VERSION ""

NS_ :

BS_:

BU_:

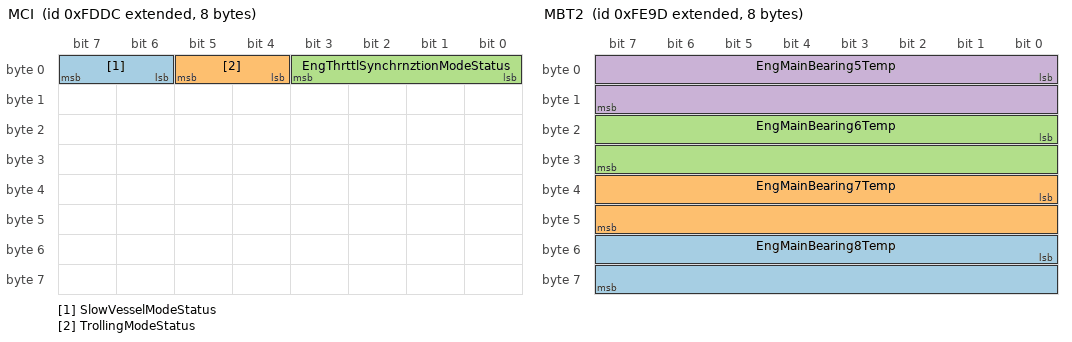
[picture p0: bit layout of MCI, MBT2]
BO_ 2147548636 MCI: 8 Vector__XXX
 SG_ SlowVesselModeStatus : 6|2@1+ (1,0) [0|3] "" Vector__XXX
 SG_ TrollingModeStatus : 4|2@1+ (1,0) [0|3] "" Vector__XXX
 SG_ EngThrttlSynchrnztionModeStatus : 0|4@1+ (1,0) [0|15] "" Vector__XXX

BO_ 2147548828 MBT3: 8 Vector__XXX
 SG_ EngMainBearing11Temp : 32|16@1+ (0.03125,-273) [-273|1735] "deg" Vector__XXX
 SG_ EngMainBearing10Temp : 16|16@1+ (0.03125,-273) [-273|1735] "deg" Vector__XXX
 SG_ EngMainBearing9Temp : 0|16@1+ (0.03125,-273) [-273|1735] "deg" Vector__XXX

BO_ 2147548829 MBT2: 8 Vector__XXX
 SG_ EngMainBearing8Temp : 48|16@1+ (0.03125,-273) [-273|1735] "deg" Vector__XXX
 SG_ EngMainBearing7Temp : 32|16@1+ (0.03125,-273) [-273|1735] "deg" Vector__XXX
 SG_ EngMainBearing6Temp : 16|16@1+ (0.03125,-273) [-273|1735] "deg" Vector__XXX
 SG_ EngMainBearing5Temp : 0|16@1+ (0.03125,-273) [-273|1735] "deg" Vector__XXX

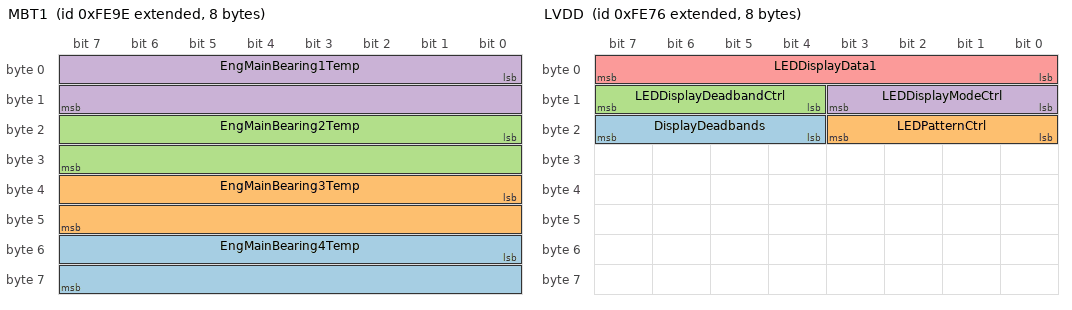
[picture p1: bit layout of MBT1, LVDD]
BO_ 2147548830 MBT1: 8 Vector__XXX
 SG_ EngMainBearing4Temp : 48|16@1+ (0.03125,-273) [-273|1735] "deg" Vector__XXX
 SG_ EngMainBearing3Temp : 32|16@1+ (0.03125,-273) [-273|1735] "deg" Vector__XXX
 SG_ EngMainBearing2Temp : 16|16@1+ (0.03125,-273) [-273|1735] "deg" Vector__XXX
 SG_ EngMainBearing1Temp : 0|16@1+ (0.03125,-273) [-273|1735] "deg" Vector__XXX

BO_ 2147548790 LVDD: 8 Vector__XXX
 SG_ DisplayDeadbands : 20|4@1+ (1,0) [0|15] "" Vector__XXX
 SG_ LEDPatternCtrl : 16|4@1+ (1,0) [0|15] "" Vector__XXX
 SG_ LEDDisplayDeadbandCtrl : 12|4@1+ (1,0) [0|15] "" Vector__XXX
 SG_ LEDDisplayModeCtrl : 8|4@1+ (1,0) [0|15] "" Vector__XXX
 SG_ LEDDisplayData1 : 0|8@1+ (1,0) [0|255] "" Vector__XXX

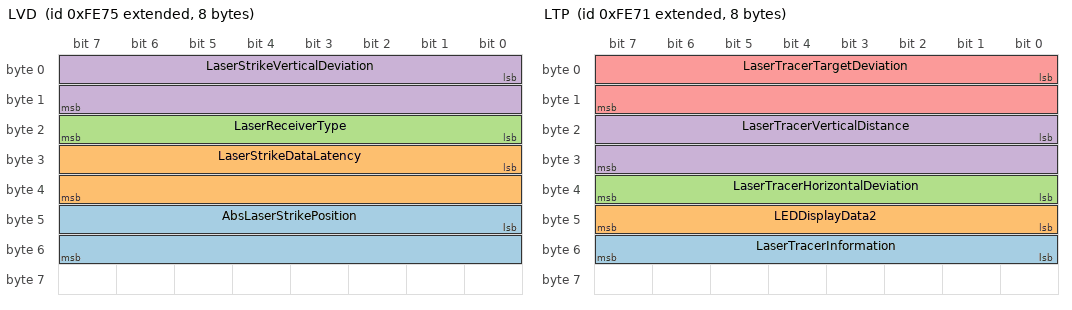
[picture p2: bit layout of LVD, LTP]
BO_ 2147548789 LVD: 8 Vector__XXX
 SG_ AbsLaserStrikePosition : 40|16@1+ (0.1,0) [0|6425.5] "mm" Vector__XXX
 SG_ LaserStrikeDataLatency : 24|16@1+ (51.2,0) [0|3.289856] "s" Vector__XXX
 SG_ LaserReceiverType : 16|8@1+ (1,0) [0|250] "" Vector__XXX
 SG_ LaserStrikeVerticalDeviation : 0|16@1+ (0.1,-2800) [-2800|3225.5] "mm" Vector__XXX

BO_ 2147548785 LTP: 8 Vector__XXX
 SG_ LaserTracerInformation : 48|8@1+ (1,0) [0|255] "" Vector__XXX
 SG_ LEDDisplayData2 : 40|8@1+ (1,0) [0|255] "" Vector__XXX
 SG_ LaserTracerHorizontalDeviation : 32|8@1+ (1,0) [0|250] "%" Vector__XXX
 SG_ LaserTracerVerticalDistance : 16|16@1+ (0.1,0) [0|6425.5] "mm" Vector__XXX
 SG_ LaserTracerTargetDeviation : 0|16@1+ (0.1,-2800) [-2800|3225.5] "mm" Vector__XXX

BO_ 2147548857 LTFI: 22 Vector__XXX
 SG_ TripDriveFuelEconomy : 160|16@1+ (1,0) [0|125.5] "km/kg" Vector__XXX
 SG_ TripCruiseFuelUsed : 128|32@1+ (0.5,0) [0|2105540607.5] "kg" Vector__XXX
 SG_ TripVehicleIdleFuelUsed : 96|32@1+ (0.5,0) [0|2105540607.5] "kg" Vector__XXX
 SG_ TripPTONonmovingFuelUsed : 64|32@1+ (0.5,0) [0|2105540607.5] "kg" Vector__XXX
 SG_ TripPTOMovingFuelUsed : 32|32@1+ (0.5,0) [0|2105540607.5] "kg" Vector__XXX
 SG_ TripDriveFuelUsed : 0|32@1+ (0.5,0) [0|2105540607.5] "kg" Vector__XXX

BO_ 2147548788 LSP: 8 Vector__XXX
 SG_ BldHeightSetPointHighResolution : 16|32@1+ (100,-208.2848) [-208.2848|0] "" Vector__XXX
 SG_ ModifySetPoint : 0|16@1+ (0.1,-2800) [-2800|3225.5] "mm" Vector__XXX

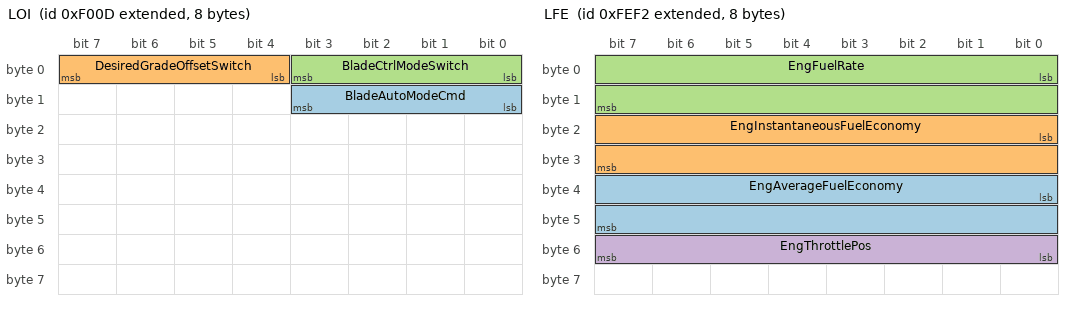
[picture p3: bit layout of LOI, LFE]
BO_ 2147545101 LOI: 8 Vector__XXX
 SG_ BladeAutoModeCmd : 8|4@1+ (1,0) [0|15] "" Vector__XXX
 SG_ DesiredGradeOffsetSwitch : 4|4@1+ (1,0) [0|15] "" Vector__XXX
 SG_ BladeCtrlModeSwitch : 0|4@1+ (1,0) [0|15] "" Vector__XXX

BO_ 2147548787 LMP: 8 Vector__XXX
 SG_ MastPos : 0|16@1+ (0.1,-2800) [-2800|3225.5] "mm" Vector__XXX

BO_ 2147548851 LFI: 8 Vector__XXX
 SG_ TripAverageFuelRate : 32|16@1+ (0.05,0) [0|3212.75] "kg/h" Vector__XXX
 SG_ TotalEngPTOFuelUsed : 0|32@1+ (0.5,0) [0|2105540607.5] "kg" Vector__XXX

BO_ 2147548914 LFE: 8 Vector__XXX
 SG_ EngAverageFuelEconomy : 32|16@1+ (1,0) [0|125.5] "km/kg" Vector__XXX
 SG_ EngInstantaneousFuelEconomy : 16|16@1+ (1,0) [0|125.5] "km/kg" Vector__XXX
 SG_ EngFuelRate : 0|16@1+ (0.05,0) [0|3212.75] "L/h" Vector__XXX
 SG_ EngThrottlePos : 48|8@1+ (0.4,0) [0|100] "%" Vector__XXX

BO_ 2147548905 LFC: 8 Vector__XXX
 SG_ EngTotalFuelUsed : 32|32@1+ (0.5,0) [0|2105540607.5] "L" Vector__XXX
 SG_ EngTripFuel : 0|32@1+ (0.5,0) [0|2105540607.5] "L" Vector__XXX

BO_ 2147548639 FWD: 8 Vector__XXX
 SG_ FrontWheelDriveActuatorStatus : 0|2@1+ (1,0) [0|3] "" Vector__XXX

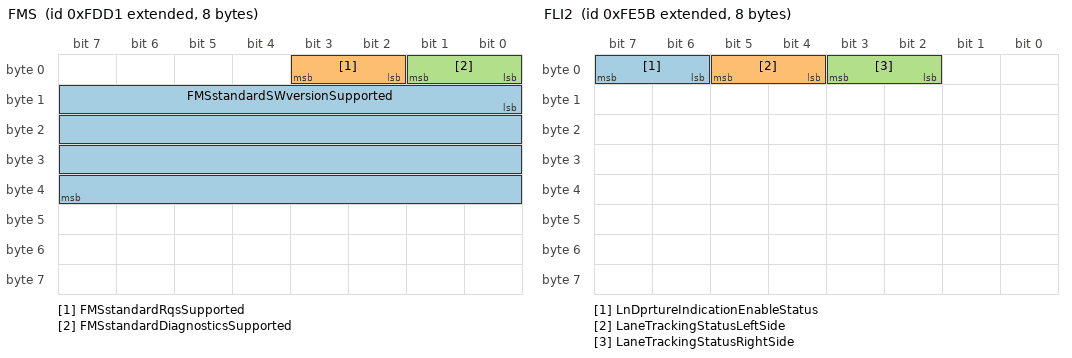
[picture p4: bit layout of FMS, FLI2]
BO_ 2147548625 FMS: 8 Vector__XXX
 SG_ FMSstandardSWversionSupported : 8|32@1+ (1,0) [0|255] "per" Vector__XXX
 SG_ FMSstandardRqsSupported : 2|2@1+ (1,0) [0|3] "" Vector__XXX
 SG_ FMSstandardDiagnosticsSupported : 0|2@1+ (1,0) [0|3] "" Vector__XXX

BO_ 2147548763 FLI2: 8 Vector__XXX
 SG_ LnDprtureIndicationEnableStatus : 6|2@1+ (1,0) [0|3] "" Vector__XXX
 SG_ LaneTrackingStatusLeftSide : 4|2@1+ (1,0) [0|3] "" Vector__XXX
 SG_ LaneTrackingStatusRightSide : 2|2@1+ (1,0) [0|3] "" Vector__XXX

BO_ 2147545095 FLI1: 8 Vector__XXX
 SG_ LaneDepartureImminentLeftSide : 6|2@1+ (1,0) [0|3] "" Vector__XXX
 SG_ LaneDepartureImminentRightSide : 4|2@1+ (1,0) [0|3] "" Vector__XXX

BO_ 2147548817 FL: 8 Vector__XXX
 SG_ EngFuelLeakage2 : 2|2@1+ (1,0) [0|3] "" Vector__XXX
 SG_ EngFuelLeakage1 : 0|2@1+ (1,0) [0|3] "" Vector__XXX

BO_ 2147548861 FD: 8 Vector__XXX
 SG_ FanSpeed : 16|16@1+ (0.125,0) [0|8031.875] "rpm" Vector__XXX
 SG_ FanDriveState : 8|4@1+ (1,0) [0|15] "" Vector__XXX
 SG_ EstPercentFanSpeed : 0|8@1+ (0.4,0) [0|100] "%" Vector__XXX

BO_ 2147548816 ETH: 33 Vector__XXX
 SG_ EngTorqueLimit6AxleInput : 248|16@1+ (2,0) [0|128510] "Nm" Vector__XXX
 SG_ EngTorqueLimit5Switch : 232|16@1+ (1,0) [0|64255] "Nm" Vector__XXX
 SG_ EngTorqueLimit4Trans : 216|16@1+ (1,0) [0|64255] "Nm" Vector__XXX
 SG_ EngTorqueLimit3Trans : 200|16@1+ (1,0) [0|64255] "Nm" Vector__XXX
 SG_ TransGearRatio3 : 184|16@1+ (0.01,0) [0|642.55] "" Vector__XXX
 SG_ EngTorqueLimit2Trans : 168|16@1+ (1,0) [0|64255] "Nm" Vector__XXX
 SG_ TransGearRatio2 : 152|16@1+ (0.01,0) [0|642.55] "" Vector__XXX
 SG_ EngTorqueLimit1Trans : 136|16@1+ (1,0) [0|64255] "Nm" Vector__XXX
 SG_ TransGearRatio1 : 120|16@1+ (0.01,0) [0|642.55] "" Vector__XXX
 SG_ EngTorqueLimitFeature : 114|3@1+ (1,0) [0|7] "" Vector__XXX
 SG_ TorqueLimitingFeatureStatus : 112|2@1+ (1,0) [0|3] "" Vector__XXX
 SG_ CalibRecordDurationTime : 80|32@1+ (0.05,0) [0|210554060.75] "hr" Vector__XXX
 SG_ CalibRecordStartYear : 72|8@1+ (1,1985) [1985|2235] "years" Vector__XXX
 SG_ CalibRecordStartDay : 64|8@1+ (0.25,0) [0|62.5] "days" Vector__XXX
 SG_ CalibRecordStartMonth : 56|8@1+ (1,0) [0|250] "months" Vector__XXX
 SG_ EngPeakTorque2 : 40|16@1+ (1,0) [0|64255] "Nm" Vector__XXX
 SG_ EngPeakTorque1 : 24|16@1+ (1,0) [0|64255] "Nm" Vector__XXX
 SG_ EngPower : 8|16@1+ (0.5,0) [0|32127.5] "kW" Vector__XXX
 SG_ NumberOfEngTorqueHistoryRecords : 0|8@1+ (1,0) [0|250] "records" Vector__XXX

BO_ 2147545100 ETC8: 8 Vector__XXX
 SG_ TransTorqueConverterRatio : 0|16@1+ (0.001,0) [0|64.255] "" Vector__XXX

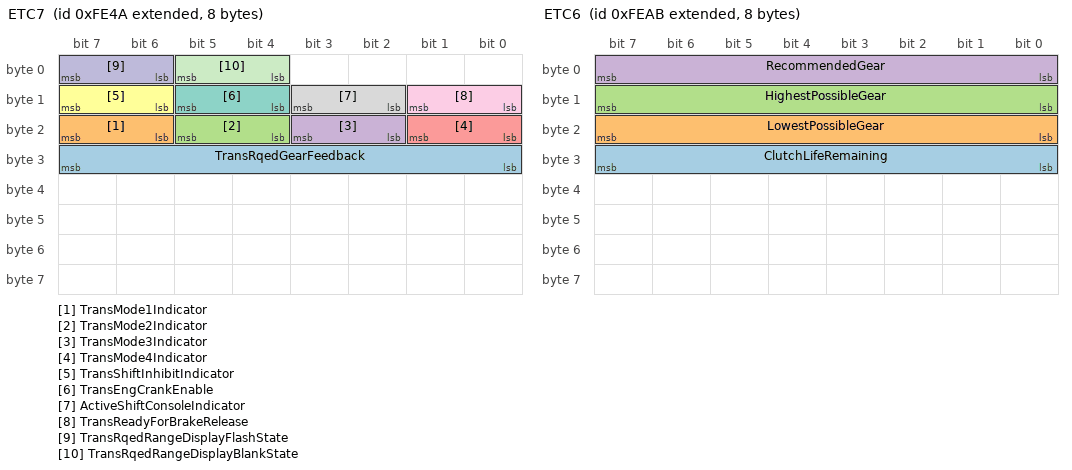
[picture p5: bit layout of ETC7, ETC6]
BO_ 2147548746 ETC7: 8 Vector__XXX
 SG_ TransRqedGearFeedback : 24|8@1+ (1,-125) [-125|125] "" Vector__XXX
 SG_ TransMode1Indicator : 22|2@1+ (1,0) [0|3] "" Vector__XXX
 SG_ TransMode2Indicator : 20|2@1+ (1,0) [0|3] "" Vector__XXX
 SG_ TransMode3Indicator : 18|2@1+ (1,0) [0|3] "" Vector__XXX
 SG_ TransMode4Indicator : 16|2@1+ (1,0) [0|3] "" Vector__XXX
 SG_ TransShiftInhibitIndicator : 14|2@1+ (1,0) [0|3] "" Vector__XXX
 SG_ TransEngCrankEnable : 12|2@1+ (1,0) [0|3] "" Vector__XXX
 SG_ ActiveShiftConsoleIndicator : 10|2@1+ (1,0) [0|3] "" Vector__XXX
 SG_ TransReadyForBrakeRelease : 8|2@1+ (1,0) [0|3] "" Vector__XXX
 SG_ TransRqedRangeDisplayFlashState : 6|2@1+ (1,0) [0|3] "" Vector__XXX
 SG_ TransRqedRangeDisplayBlankState : 4|2@1+ (1,0) [0|3] "" Vector__XXX

BO_ 2147548843 ETC6: 8 Vector__XXX
 SG_ ClutchLifeRemaining : 24|8@1+ (0.4,0) [0|100] "%" Vector__XXX
 SG_ LowestPossibleGear : 16|8@1+ (1,-125) [-125|125] "" Vector__XXX
 SG_ HighestPossibleGear : 8|8@1+ (1,-125) [-125|125] "" Vector__XXX
 SG_ RecommendedGear : 0|8@1+ (1,-125) [-125|125] "" Vector__XXX

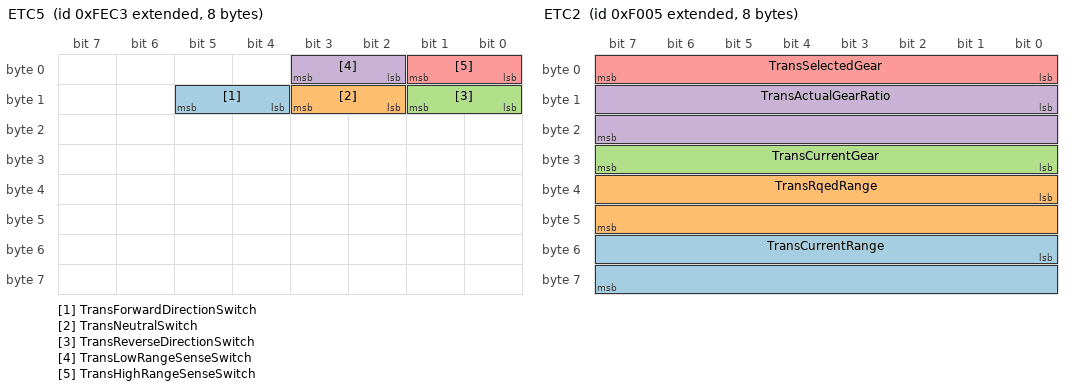
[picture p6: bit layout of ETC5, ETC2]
BO_ 2147548867 ETC5: 8 Vector__XXX
 SG_ TransForwardDirectionSwitch : 12|2@1+ (1,0) [0|3] "" Vector__XXX
 SG_ TransNeutralSwitch : 10|2@1+ (1,0) [0|3] "" Vector__XXX
 SG_ TransReverseDirectionSwitch : 8|2@1+ (1,0) [0|3] "" Vector__XXX
 SG_ TransLowRangeSenseSwitch : 2|2@1+ (1,0) [0|3] "" Vector__XXX
 SG_ TransHighRangeSenseSwitch : 0|2@1+ (1,0) [0|3] "" Vector__XXX

BO_ 2147548869 ETC4: 8 Vector__XXX
 SG_ TransSynchronizerBrakeValue : 8|8@1+ (0.4,0) [0|100] "%" Vector__XXX
 SG_ TransSynchronizerClutchValue : 0|8@1+ (0.4,0) [0|100] "%" Vector__XXX

BO_ 2147548871 ETC3: 8 Vector__XXX
 SG_ TransInertiaBrakeActuator : 46|2@1+ (1,0) [0|3] "" Vector__XXX
 SG_ TransDefuelActuator : 44|2@1+ (1,0) [0|3] "" Vector__XXX
 SG_ TransLockupClutchActuator : 42|2@1+ (1,0) [0|3] "" Vector__XXX
 SG_ TransClutchActuator : 40|2@1+ (1,0) [0|3] "" Vector__XXX
 SG_ TransSplitterIndirectActuator : 38|2@1+ (1,0) [0|3] "" Vector__XXX
 SG_ TransSplitterDirectActuator : 36|2@1+ (1,0) [0|3] "" Vector__XXX
 SG_ TransRangeLowActuator : 34|2@1+ (1,0) [0|3] "" Vector__XXX
 SG_ TransRangeHighActuator : 32|2@1+ (1,0) [0|3] "" Vector__XXX
 SG_ TransShiftFingerGearActuator2 : 30|2@1+ (1,0) [0|3] "" Vector__XXX
 SG_ TransShiftFingerRailActuator2 : 28|2@1+ (1,0) [0|3] "" Vector__XXX
 SG_ TransShiftFingerGearActuator1 : 26|2@1+ (1,0) [0|3] "" Vector__XXX
 SG_ TransShiftFingerRailActuator1 : 24|2@1+ (1,0) [0|3] "" Vector__XXX
 SG_ TrnsShftFngrCenterRailIndicator : 20|2@1+ (1,0) [0|3] "" Vector__XXX
 SG_ TrnsShftFngrEngagementIndicator : 18|2@1+ (1,0) [0|3] "" Vector__XXX
 SG_ TrnsShiftFingerNeutralIndicator : 16|2@1+ (1,0) [0|3] "" Vector__XXX
 SG_ TransShiftFingerRailPos : 8|8@1+ (0.4,0) [0|100] "%" Vector__XXX
 SG_ TransShiftFingerGearPos : 0|8@1+ (0.4,0) [0|100] "%" Vector__XXX

BO_ 2147545093 ETC2: 8 Vector__XXX
 SG_ TransCurrentRange : 48|16@1+ (1,0) [0|255] "per" Vector__XXX
 SG_ TransRqedRange : 32|16@1+ (1,0) [0|255] "per" Vector__XXX
 SG_ TransCurrentGear : 24|8@1+ (1,-125) [-125|125] "" Vector__XXX
 SG_ TransActualGearRatio : 8|16@1+ (0.001,0) [0|64.255] "" Vector__XXX
 SG_ TransSelectedGear : 0|8@1+ (1,-125) [-125|125] "" Vector__XXX

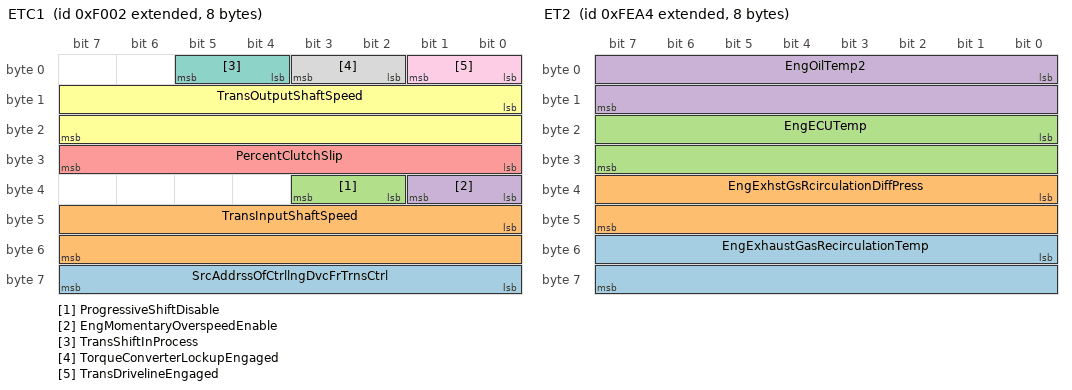
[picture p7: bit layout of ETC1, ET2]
BO_ 2147545090 ETC1: 8 Vector__XXX
 SG_ SrcAddrssOfCtrllngDvcFrTrnsCtrl : 56|8@1+ (1,0) [0|255] "" Vector__XXX
 SG_ TransInputShaftSpeed : 40|16@1+ (0.125,0) [0|8031.875] "rpm" Vector__XXX
 SG_ ProgressiveShiftDisable : 34|2@1+ (1,0) [0|3] "" Vector__XXX
 SG_ EngMomentaryOverspeedEnable : 32|2@1+ (1,0) [0|3] "" Vector__XXX
 SG_ PercentClutchSlip : 24|8@1+ (0.4,0) [0|100] "%" Vector__XXX
 SG_ TransOutputShaftSpeed : 8|16@1+ (0.125,0) [0|8031.875] "rpm" Vector__XXX
 SG_ TransShiftInProcess : 4|2@1+ (1,0) [0|3] "" Vector__XXX
 SG_ TorqueConverterLockupEngaged : 2|2@1+ (1,0) [0|3] "" Vector__XXX
 SG_ TransDrivelineEngaged : 0|2@1+ (1,0) [0|3] "" Vector__XXX

BO_ 2147548777 ET3: 8 Vector__XXX
 SG_ EngCoolantTempHiRes : 16|16@1+ (0.03125,-273) [-273|1735] "deg" Vector__XXX
 SG_ EngIntkVlvActationSystemOilTemp : 32|16@1+ (0.03125,-273) [-273|1735] "deg" Vector__XXX
 SG_ EngIntakeManifold1AirTemp : 0|16@1+ (0.03125,-273) [-273|1735] "deg" Vector__XXX

BO_ 2147548836 ET2: 8 Vector__XXX
 SG_ EngExhaustGasRecirculationTemp : 48|16@1+ (0.03125,-273) [-273|1735] "deg" Vector__XXX
 SG_ EngExhstGsRcirculationDiffPress : 32|16@1+ (1,-250) [-250|0] "a" Vector__XXX
 SG_ EngECUTemp : 16|16@1+ (0.03125,-273) [-273|1735] "deg" Vector__XXX
 SG_ EngOilTemp2 : 0|16@1+ (0.03125,-273) [-273|1735] "deg" Vector__XXX

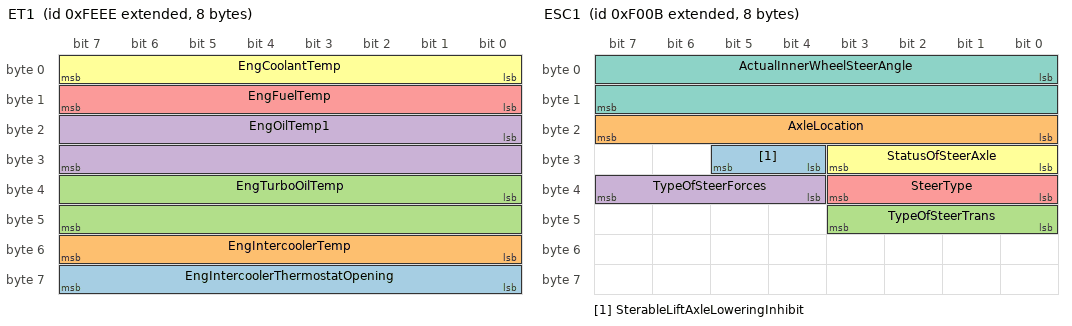
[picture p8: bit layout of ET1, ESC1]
BO_ 2147548910 ET1: 8 Vector__XXX
 SG_ EngIntercoolerThermostatOpening : 56|8@1+ (0.4,0) [0|100] "%" Vector__XXX
 SG_ EngIntercoolerTemp : 48|8@1+ (1,-40) [-40|210] "deg" Vector__XXX
 SG_ EngTurboOilTemp : 32|16@1+ (0.03125,-273) [-273|1735] "deg" Vector__XXX
 SG_ EngOilTemp1 : 16|16@1+ (0.03125,-273) [-273|1735] "deg" Vector__XXX
 SG_ EngFuelTemp : 8|8@1+ (1,-40) [-40|210] "deg" Vector__XXX
 SG_ EngCoolantTemp : 0|8@1+ (1,-40) [-40|210] "deg" Vector__XXX

BO_ 2147548679 ET: 8 Vector__XXX
 SG_ EngExhstExhstGsTempLeftManifold : 16|16@1+ (0.03125,-273) [-273|1735] "deg" Vector__XXX
 SG_ EngExhstExhstGsTmpRightManifold : 0|16@1+ (0.03125,-273) [-273|1735] "deg" Vector__XXX

BO_ 2147545099 ESC1: 8 Vector__XXX
 SG_ SterableLiftAxleLoweringInhibit : 28|2@1+ (1,0) [0|3] "" Vector__XXX
 SG_ AxleLocation : 16|8@1+ (1,0) [0|255] "" Vector__XXX
 SG_ TypeOfSteerTrans : 40|4@1+ (1,0) [0|15] "" Vector__XXX
 SG_ TypeOfSteerForces : 36|4@1+ (1,0) [0|15] "" Vector__XXX
 SG_ SteerType : 32|4@1+ (1,0) [0|15] "" Vector__XXX
 SG_ StatusOfSteerAxle : 24|4@1+ (1,0) [0|15] "" Vector__XXX
 SG_ ActualInnerWheelSteerAngle : 0|16@1+ (1,-125) [-125|125] "deg" Vector__XXX

BO_ 2147548866 ERC2: 8 Vector__XXX
 SG_ TransOutputRetarder : 0|2@1+ (1,0) [0|3] "" Vector__XXX

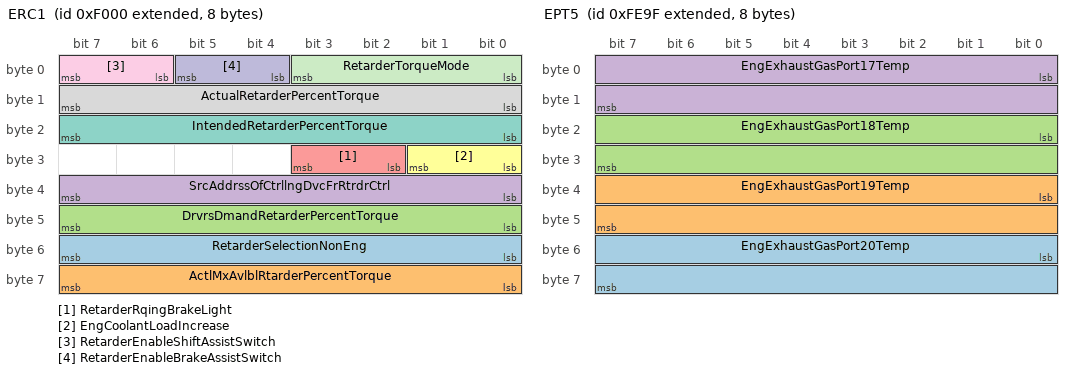
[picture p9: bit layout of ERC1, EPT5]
BO_ 2147545088 ERC1: 8 Vector__XXX
 SG_ RetarderSelectionNonEng : 48|8@1+ (0.4,0) [0|100] "%" Vector__XXX
 SG_ ActlMxAvlblRtarderPercentTorque : 56|8@1+ (1,-125) [-125|125] "%" Vector__XXX
 SG_ DrvrsDmandRetarderPercentTorque : 40|8@1+ (1,-125) [-125|125] "%" Vector__XXX
 SG_ SrcAddrssOfCtrllngDvcFrRtrdrCtrl : 32|8@1+ (1,0) [0|255] "" Vector__XXX
 SG_ RetarderRqingBrakeLight : 26|2@1+ (1,0) [0|3] "" Vector__XXX
 SG_ EngCoolantLoadIncrease : 24|2@1+ (1,0) [0|3] "" Vector__XXX
 SG_ IntendedRetarderPercentTorque : 16|8@1+ (1,-125) [-125|125] "%" Vector__XXX
 SG_ ActualRetarderPercentTorque : 8|8@1+ (1,-125) [-125|125] "%" Vector__XXX
 SG_ RetarderEnableShiftAssistSwitch : 6|2@1+ (1,0) [0|3] "" Vector__XXX
 SG_ RetarderEnableBrakeAssistSwitch : 4|2@1+ (1,0) [0|3] "" Vector__XXX
 SG_ RetarderTorqueMode : 0|4@1+ (1,0) [0|15] "" Vector__XXX

BO_ 2147548831 EPT5: 8 Vector__XXX
 SG_ EngExhaustGasPort20Temp : 48|16@1+ (0.03125,-273) [-273|1735] "deg" Vector__XXX
 SG_ EngExhaustGasPort19Temp : 32|16@1+ (0.03125,-273) [-273|1735] "deg" Vector__XXX
 SG_ EngExhaustGasPort18Temp : 16|16@1+ (0.03125,-273) [-273|1735] "deg" Vector__XXX
 SG_ EngExhaustGasPort17Temp : 0|16@1+ (0.03125,-273) [-273|1735] "deg" Vector__XXX

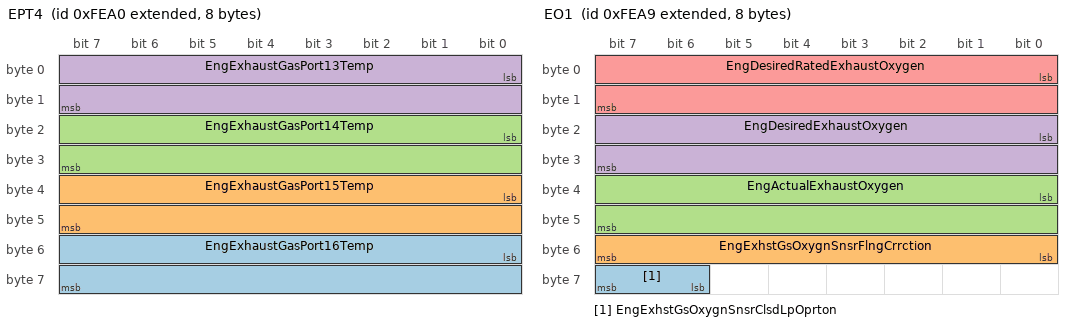
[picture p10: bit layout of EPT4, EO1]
BO_ 2147548832 EPT4: 8 Vector__XXX
 SG_ EngExhaustGasPort16Temp : 48|16@1+ (0.03125,-273) [-273|1735] "deg" Vector__XXX
 SG_ EngExhaustGasPort15Temp : 32|16@1+ (0.03125,-273) [-273|1735] "deg" Vector__XXX
 SG_ EngExhaustGasPort14Temp : 16|16@1+ (0.03125,-273) [-273|1735] "deg" Vector__XXX
 SG_ EngExhaustGasPort13Temp : 0|16@1+ (0.03125,-273) [-273|1735] "deg" Vector__XXX

BO_ 2147548833 EPT3: 8 Vector__XXX
 SG_ EngExhaustGasPort12Temp : 48|16@1+ (0.03125,-273) [-273|1735] "deg" Vector__XXX
 SG_ EngExhaustGasPort11Temp : 32|16@1+ (0.03125,-273) [-273|1735] "deg" Vector__XXX
 SG_ EngExhaustGasPort10Temp : 16|16@1+ (0.03125,-273) [-273|1735] "deg" Vector__XXX
 SG_ EngExhaustGasPort9Temp : 0|16@1+ (0.03125,-273) [-273|1735] "deg" Vector__XXX

BO_ 2147548834 EPT2: 8 Vector__XXX
 SG_ EngExhaustGasPort8Temp : 48|16@1+ (0.03125,-273) [-273|1735] "deg" Vector__XXX
 SG_ EngExhaustGasPort7Temp : 32|16@1+ (0.03125,-273) [-273|1735] "deg" Vector__XXX
 SG_ EngExhaustGasPort6Temp : 16|16@1+ (0.03125,-273) [-273|1735] "deg" Vector__XXX
 SG_ EngExhaustGasPort5Temp : 0|16@1+ (0.03125,-273) [-273|1735] "deg" Vector__XXX

BO_ 2147548835 EPT1: 8 Vector__XXX
 SG_ EngExhaustGasPort4Temp : 48|16@1+ (0.03125,-273) [-273|1735] "deg" Vector__XXX
 SG_ EngExhaustGasPort3Temp : 32|16@1+ (0.03125,-273) [-273|1735] "deg" Vector__XXX
 SG_ EngExhaustGasPort2Temp : 16|16@1+ (0.03125,-273) [-273|1735] "deg" Vector__XXX
 SG_ EngExhaustGasPort1Temp : 0|16@1+ (0.03125,-273) [-273|1735] "deg" Vector__XXX

BO_ 2147548644 EPD: 8 Vector__XXX
 SG_ PayloadPercentage : 0|8@1+ (1,0) [0|250] "%" Vector__XXX

BO_ 2147548626 EP: 8 Vector__XXX
 SG_ DataMemoryUsage : 16|8@1+ (0.4,0) [0|100] "%" Vector__XXX
 SG_ KeepAliveBatteryConsumption : 0|16@1+ (1,0) [0|64255] "mAhr" Vector__XXX

BO_ 2147548643 EOAC: 8 Vector__XXX
 SG_ TravelVelocityCtrlPos : 0|8@1+ (1,-125) [-125|125] "%" Vector__XXX

BO_ 2147548841 EO1: 8 Vector__XXX
 SG_ EngExhstGsOxygnSnsrClsdLpOprton : 62|2@1+ (1,0) [0|3] "" Vector__XXX
 SG_ EngExhstGsOxygnSnsrFlngCrrction : 48|8@1+ (1,-125) [-125|125] "%" Vector__XXX
 SG_ EngActualExhaustOxygen : 32|16@1+ (0.0025,0) [0|160.6375] "%" Vector__XXX
 SG_ EngDesiredExhaustOxygen : 16|16@1+ (0.0025,0) [0|160.6375] "%" Vector__XXX
 SG_ EngDesiredRatedExhaustOxygen : 0|16@1+ (0.0025,0) [0|160.6375] "%" Vector__XXX

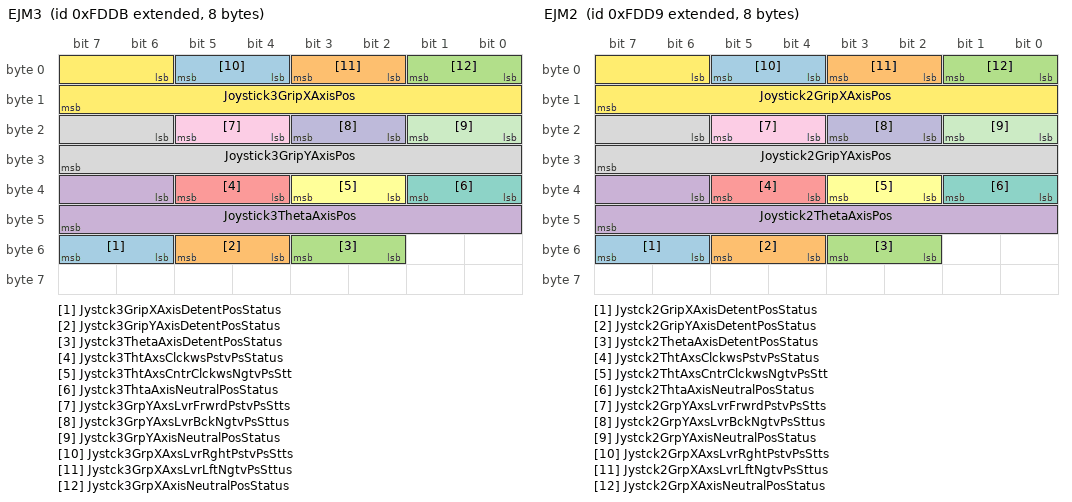
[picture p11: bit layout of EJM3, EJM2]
BO_ 2147548635 EJM3: 8 Vector__XXX
 SG_ Jystck3GripXAxisDetentPosStatus : 54|2@1+ (1,0) [0|3] "" Vector__XXX
 SG_ Jystck3GripYAxisDetentPosStatus : 52|2@1+ (1,0) [0|3] "" Vector__XXX
 SG_ Jystck3ThetaAxisDetentPosStatus : 50|2@1+ (1,0) [0|3] "" Vector__XXX
 SG_ Joystick3ThetaAxisPos : 38|10@1+ (0.1,0) [0|102] "%" Vector__XXX
 SG_ Jystck3ThtAxsClckwsPstvPsStatus : 36|2@1+ (1,0) [0|3] "" Vector__XXX
 SG_ Jystck3ThtAxsCntrClckwsNgtvPsStt : 34|2@1+ (1,0) [0|3] "" Vector__XXX
 SG_ Jystck3ThtaAxisNeutralPosStatus : 32|2@1+ (1,0) [0|3] "" Vector__XXX
 SG_ Joystick3GripYAxisPos : 22|10@1+ (0.1,0) [0|102] "%" Vector__XXX
 SG_ Jystck3GrpYAxsLvrFrwrdPstvPsStts : 20|2@1+ (1,0) [0|3] "" Vector__XXX
 SG_ Jystck3GrpYAxsLvrBckNgtvPsSttus : 18|2@1+ (1,0) [0|3] "" Vector__XXX
 SG_ Jystck3GrpYAxisNeutralPosStatus : 16|2@1+ (1,0) [0|3] "" Vector__XXX
 SG_ Joystick3GripXAxisPos : 6|10@1+ (0.1,0) [0|102] "%" Vector__XXX
 SG_ Jystck3GrpXAxsLvrRghtPstvPsStts : 4|2@1+ (1,0) [0|3] "" Vector__XXX
 SG_ Jystck3GrpXAxsLvrLftNgtvPsSttus : 2|2@1+ (1,0) [0|3] "" Vector__XXX
 SG_ Jystck3GrpXAxisNeutralPosStatus : 0|2@1+ (1,0) [0|3] "" Vector__XXX

BO_ 2147548633 EJM2: 8 Vector__XXX
 SG_ Jystck2GripXAxisDetentPosStatus : 54|2@1+ (1,0) [0|3] "" Vector__XXX
 SG_ Jystck2GripYAxisDetentPosStatus : 52|2@1+ (1,0) [0|3] "" Vector__XXX
 SG_ Jystck2ThetaAxisDetentPosStatus : 50|2@1+ (1,0) [0|3] "" Vector__XXX
 SG_ Joystick2ThetaAxisPos : 38|10@1+ (0.1,0) [0|102] "%" Vector__XXX
 SG_ Jystck2ThtAxsClckwsPstvPsStatus : 36|2@1+ (1,0) [0|3] "" Vector__XXX
 SG_ Jystck2ThtAxsCntrClckwsNgtvPsStt : 34|2@1+ (1,0) [0|3] "" Vector__XXX
 SG_ Jystck2ThtaAxisNeutralPosStatus : 32|2@1+ (1,0) [0|3] "" Vector__XXX
 SG_ Joystick2GripYAxisPos : 22|10@1+ (0.1,0) [0|102] "%" Vector__XXX
 SG_ Jystck2GrpYAxsLvrFrwrdPstvPsStts : 20|2@1+ (1,0) [0|3] "" Vector__XXX
 SG_ Jystck2GrpYAxsLvrBckNgtvPsSttus : 18|2@1+ (1,0) [0|3] "" Vector__XXX
 SG_ Jystck2GrpYAxisNeutralPosStatus : 16|2@1+ (1,0) [0|3] "" Vector__XXX
 SG_ Joystick2GripXAxisPos : 6|10@1+ (0.1,0) [0|102] "%" Vector__XXX
 SG_ Jystck2GrpXAxsLvrRghtPstvPsStts : 4|2@1+ (1,0) [0|3] "" Vector__XXX
 SG_ Jystck2GrpXAxsLvrLftNgtvPsSttus : 2|2@1+ (1,0) [0|3] "" Vector__XXX
 SG_ Jystck2GrpXAxisNeutralPosStatus : 0|2@1+ (1,0) [0|3] "" Vector__XXX

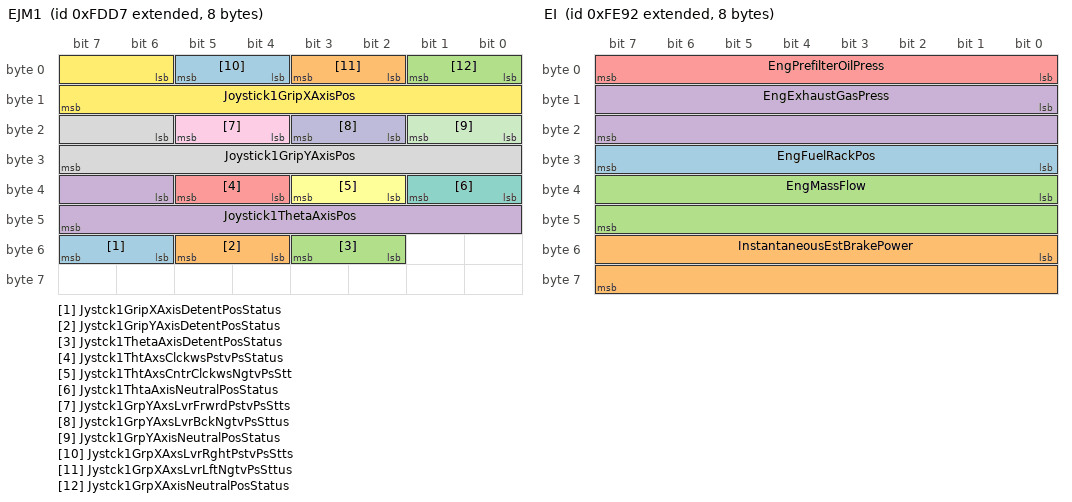
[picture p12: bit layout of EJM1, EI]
BO_ 2147548631 EJM1: 8 Vector__XXX
 SG_ Jystck1GripXAxisDetentPosStatus : 54|2@1+ (1,0) [0|3] "" Vector__XXX
 SG_ Jystck1GripYAxisDetentPosStatus : 52|2@1+ (1,0) [0|3] "" Vector__XXX
 SG_ Jystck1ThetaAxisDetentPosStatus : 50|2@1+ (1,0) [0|3] "" Vector__XXX
 SG_ Joystick1ThetaAxisPos : 38|10@1+ (0.1,0) [0|102] "%" Vector__XXX
 SG_ Jystck1ThtAxsClckwsPstvPsStatus : 36|2@1+ (1,0) [0|3] "" Vector__XXX
 SG_ Jystck1ThtAxsCntrClckwsNgtvPsStt : 34|2@1+ (1,0) [0|3] "" Vector__XXX
 SG_ Jystck1ThtaAxisNeutralPosStatus : 32|2@1+ (1,0) [0|3] "" Vector__XXX
 SG_ Joystick1GripYAxisPos : 22|10@1+ (0.1,0) [0|102] "%" Vector__XXX
 SG_ Jystck1GrpYAxsLvrFrwrdPstvPsStts : 20|2@1+ (1,0) [0|3] "" Vector__XXX
 SG_ Jystck1GrpYAxsLvrBckNgtvPsSttus : 18|2@1+ (1,0) [0|3] "" Vector__XXX
 SG_ Jystck1GrpYAxisNeutralPosStatus : 16|2@1+ (1,0) [0|3] "" Vector__XXX
 SG_ Joystick1GripXAxisPos : 6|10@1+ (0.1,0) [0|102] "%" Vector__XXX
 SG_ Jystck1GrpXAxsLvrRghtPstvPsStts : 4|2@1+ (1,0) [0|3] "" Vector__XXX
 SG_ Jystck1GrpXAxsLvrLftNgtvPsSttus : 2|2@1+ (1,0) [0|3] "" Vector__XXX
 SG_ Jystck1GrpXAxisNeutralPosStatus : 0|2@1+ (1,0) [0|3] "" Vector__XXX

BO_ 2147548818 EI: 8 Vector__XXX
 SG_ EngFuelRackPos : 24|8@1+ (0.4,0) [0|100] "%" Vector__XXX
 SG_ InstantaneousEstBrakePower : 48|16@1+ (0.5,0) [0|32127.5] "kW" Vector__XXX
 SG_ EngMassFlow : 32|16@1+ (0.05,0) [0|3212.75] "kg/h" Vector__XXX
 SG_ EngExhaustGasPress : 8|16@1+ (1,-250) [-250|0] "a" Vector__XXX
 SG_ EngPrefilterOilPress : 0|8@1+ (4,0) [0|1000] "kPa" Vector__XXX

BO_ 2147548849 EH: 8 Vector__XXX
 SG_ TotalECURunTime : 32|32@1+ (0.05,0) [0|210554060.75] "hr" Vector__XXX
 SG_ TotalECUDistance : 0|32@1+ (0.125,0) [0|526385151.9] "km" Vector__XXX

BO_ 2147545098 EGF1: 8 Vector__XXX
 SG_ EngInletAirMassFlowRate : 16|16@1+ (0.05,0) [0|3212.75] "kg/h" Vector__XXX
 SG_ EngExhstGsRcrcltionMassFlowRate : 0|16@1+ (0.05,0) [0|3212.75] "kg/h" Vector__XXX

BO_ 2147548778 EFS: 8 Vector__XXX
 SG_ EngFuelFilterSucSideDiffPress : 16|8@1+ (2,0) [0|500] "kPa" Vector__XXX
 SG_ EngFuelSupplyPumpInletPress : 8|8@1+ (2,0) [0|500] "kPa" Vector__XXX
 SG_ EngOilLevelRemoteReservoir : 0|8@1+ (0.4,0) [0|100] "%" Vector__XXX

BO_ 2147548609 EFL_P3: 8 Vector__XXX
 SG_ EngIntkVlvActtionSystemOilPress : 0|16@1+ (1,0) [0|251] "Mpa" Vector__XXX

BO_ 2147548891 EFL_P2: 8 Vector__XXX
 SG_ EngInjectorMeteringRail2Press : 48|16@1+ (1,0) [0|251] "Mpa" Vector__XXX
 SG_ EngInjectorTimingRail1Press : 32|16@1+ (1,0) [0|251] "Mpa" Vector__XXX
 SG_ EngInjectorMeteringRail1Press : 16|16@1+ (1,0) [0|251] "Mpa" Vector__XXX
 SG_ EngInjectionCtrlPress : 0|16@1+ (1,0) [0|251] "Mpa" Vector__XXX

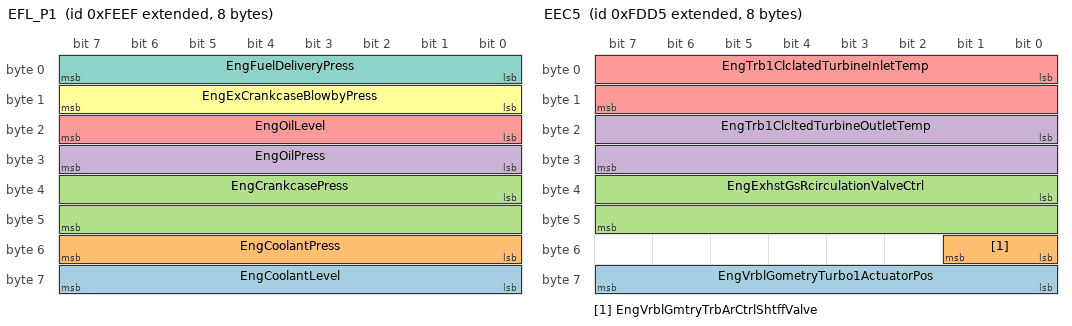
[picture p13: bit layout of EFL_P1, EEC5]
BO_ 2147548911 EFL_P1: 8 Vector__XXX
 SG_ EngCoolantLevel : 56|8@1+ (0.4,0) [0|100] "%" Vector__XXX
 SG_ EngCoolantPress : 48|8@1+ (2,0) [0|500] "kPa" Vector__XXX
 SG_ EngCrankcasePress : 32|16@1+ (1,-250) [-250|0] "a" Vector__XXX
 SG_ EngOilPress : 24|8@1+ (4,0) [0|1000] "kPa" Vector__XXX
 SG_ EngOilLevel : 16|8@1+ (0.4,0) [0|100] "%" Vector__XXX
 SG_ EngExCrankcaseBlowbyPress : 8|8@1+ (0.05,0) [0|12.5] "kPa" Vector__XXX
 SG_ EngFuelDeliveryPress : 0|8@1+ (4,0) [0|1000] "kPa" Vector__XXX

BO_ 2147548819 EES: 8 Vector__XXX
 SG_ TurningGearEngaged : 18|2@1+ (1,0) [0|3] "" Vector__XXX
 SG_ SafetyWireStatus : 16|2@1+ (1,0) [0|3] "" Vector__XXX
 SG_ ElectricalLoad : 0|16@1+ (0.5,0) [0|32127.5] "kW" Vector__XXX

BO_ 2147548629 EEC5: 8 Vector__XXX
 SG_ EngVrblGometryTurbo1ActuatorPos : 56|8@1+ (0.4,0) [0|100] "%" Vector__XXX
 SG_ EngVrblGmtryTrbArCtrlShtffValve : 48|2@1+ (1,0) [0|3] "" Vector__XXX
 SG_ EngExhstGsRcirculationValveCtrl : 32|16@1+ (0.0025,0) [0|160.6375] "%" Vector__XXX
 SG_ EngTrb1ClcltedTurbineOutletTemp : 16|16@1+ (0.03125,-273) [-273|1735] "deg" Vector__XXX
 SG_ EngTrb1ClclatedTurbineInletTemp : 0|16@1+ (0.03125,-273) [-273|1735] "deg" Vector__XXX

BO_ 2147548862 EEC4: 8 Vector__XXX
 SG_ EngRatedSpeed : 16|16@1+ (0.125,0) [0|8031.875] "rpm" Vector__XXX
 SG_ EngRatedPower : 0|16@1+ (0.5,0) [0|32127.5] "kW" Vector__XXX

BO_ 2147548895 EEC3: 8 Vector__XXX
 SG_ EstEngPrsticLossesPercentTorque : 32|8@1+ (1,-125) [-125|125] "%" Vector__XXX
 SG_ EngsDsrdOprtngSpdAsymmtryAdjstmn : 24|8@1+ (1,0) [0|250] "" Vector__XXX
 SG_ EngsDesiredOperatingSpeed : 8|16@1+ (0.125,0) [0|8031.875] "rpm" Vector__XXX
 SG_ NominalFrictionPercentTorque : 0|8@1+ (1,-125) [-125|125] "%" Vector__XXX

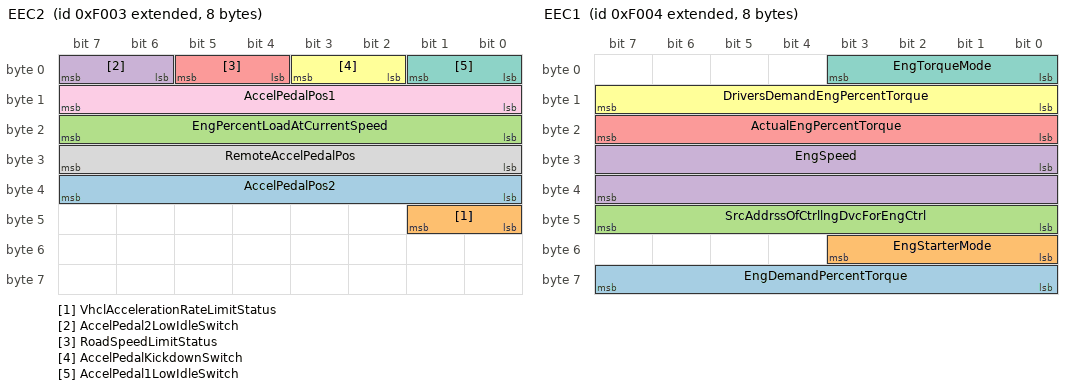
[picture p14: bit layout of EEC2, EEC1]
BO_ 2147545091 EEC2: 8 Vector__XXX
 SG_ AccelPedalPos2 : 32|8@1+ (0.4,0) [0|100] "%" Vector__XXX
 SG_ VhclAccelerationRateLimitStatus : 40|2@1+ (1,0) [0|3] "" Vector__XXX
 SG_ EngPercentLoadAtCurrentSpeed : 16|8@1+ (1,0) [0|250] "%" Vector__XXX
 SG_ AccelPedal2LowIdleSwitch : 6|2@1+ (1,0) [0|3] "" Vector__XXX
 SG_ RoadSpeedLimitStatus : 4|2@1+ (1,0) [0|3] "" Vector__XXX
 SG_ AccelPedalKickdownSwitch : 2|2@1+ (1,0) [0|3] "" Vector__XXX
 SG_ AccelPedal1LowIdleSwitch : 0|2@1+ (1,0) [0|3] "" Vector__XXX
 SG_ RemoteAccelPedalPos : 24|8@1+ (0.4,0) [0|100] "%" Vector__XXX
 SG_ AccelPedalPos1 : 8|8@1+ (0.4,0) [0|100] "%" Vector__XXX

BO_ 2147545092 EEC1: 8 Vector__XXX
 SG_ EngDemandPercentTorque : 56|8@1+ (1,-125) [-125|125] "%" Vector__XXX
 SG_ EngStarterMode : 48|4@1+ (1,0) [0|15] "" Vector__XXX
 SG_ SrcAddrssOfCtrllngDvcForEngCtrl : 40|8@1+ (1,0) [0|255] "" Vector__XXX
 SG_ EngSpeed : 24|16@1+ (0.125,0) [0|8031.875] "rpm" Vector__XXX
 SG_ ActualEngPercentTorque : 16|8@1+ (1,-125) [-125|125] "%" Vector__XXX
 SG_ DriversDemandEngPercentTorque : 8|8@1+ (1,-125) [-125|125] "%" Vector__XXX
 SG_ EngTorqueMode : 0|4@1+ (1,0) [0|15] "" Vector__XXX

BO_ 2147548613 ECUID: 8 Vector__XXX

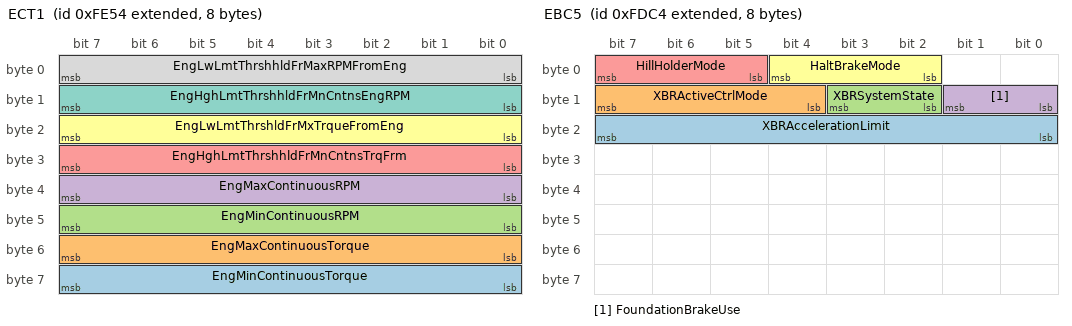
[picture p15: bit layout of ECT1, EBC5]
BO_ 2147548756 ECT1: 8 Vector__XXX
 SG_ EngMinContinuousTorque : 56|8@1+ (1,-125) [-125|125] "%" Vector__XXX
 SG_ EngMaxContinuousTorque : 48|8@1+ (1,-125) [-125|125] "%" Vector__XXX
 SG_ EngMinContinuousRPM : 40|8@1+ (32,0) [0|8000] "rpm" Vector__XXX
 SG_ EngMaxContinuousRPM : 32|8@1+ (32,0) [0|8000] "rpm" Vector__XXX
 SG_ EngHghLmtThrshhldFrMnCntnsTrqFrm : 24|8@1+ (1,-125) [-125|125] "%" Vector__XXX
 SG_ EngLwLmtThrshldFrMxTrqueFromEng : 16|8@1+ (1,-125) [-125|125] "%" Vector__XXX
 SG_ EngHghLmtThrshhldFrMnCntnsEngRPM : 8|8@1+ (32,0) [0|8000] "rpm" Vector__XXX
 SG_ EngLwLmtThrshhldFrMaxRPMFromEng : 0|8@1+ (32,0) [0|8000] "rpm" Vector__XXX

BO_ 2147548899 EC: 34 Vector__XXX
 SG_ EngDefaultTorqueLimit : 256|16@1+ (1,0) [0|64255] "Nm" Vector__XXX
 SG_ EngMomentOfInertia : 240|16@1+ (0.004,0) [0|257.02] "kg-m^2" Vector__XXX
 SG_ EngExRngRqdSpdCtrlRngUpperLimit : 224|16@1+ (0.125,0) [0|8031.875] "rpm" Vector__XXX
 SG_ EngRqdTorqueCtrlRangeUpperLimit : 216|8@1+ (1,-125) [-125|125] "%" Vector__XXX
 SG_ EngRqdTorqueCtrlRangeLowerLimit : 208|8@1+ (1,-125) [-125|125] "%" Vector__XXX
 SG_ EngRqedSpeedCtrlRangeUpperLimit : 200|8@1+ (10,0) [0|2500] "rpm" Vector__XXX
 SG_ EngRqedSpeedCtrlRangeLowerLimit : 192|8@1+ (10,0) [0|2500] "rpm" Vector__XXX
 SG_ EngMxMomentaryOverrideTimeLimit : 184|8@1+ (0.1,0) [0|25] "s" Vector__XXX
 SG_ EngMxMmntaryOverrideSpeedPoint7 : 168|16@1+ (0.125,0) [0|8031.875] "rpm" Vector__XXX
 SG_ EngReferenceTorque : 152|16@1+ (1,0) [0|64255] "Nm" Vector__XXX
 SG_ EngSpeedAtHighIdlePoint6 : 120|16@1+ (0.125,0) [0|8031.875] "rpm" Vector__XXX
 SG_ EngGainOfEndspeedGovernor : 136|16@1+ (1,0) [0|50.2] "%/rpm" Vector__XXX
 SG_ EngPercentTorqueAtPoint5 : 112|8@1+ (1,-125) [-125|125] "%" Vector__XXX
 SG_ EngSpeedAtPoint5 : 96|16@1+ (0.125,0) [0|8031.875] "rpm" Vector__XXX
 SG_ EngPercentTorqueAtPoint4 : 88|8@1+ (1,-125) [-125|125] "%" Vector__XXX
 SG_ EngSpeedAtPoint4 : 72|16@1+ (0.125,0) [0|8031.875] "rpm" Vector__XXX
 SG_ EngPercentTorqueAtPoint3 : 64|8@1+ (1,-125) [-125|125] "%" Vector__XXX
 SG_ EngSpeedAtPoint3 : 48|16@1+ (0.125,0) [0|8031.875] "rpm" Vector__XXX
 SG_ EngPercentTorqueAtPoint2 : 40|8@1+ (1,-125) [-125|125] "%" Vector__XXX
 SG_ EngSpeedAtPoint2 : 24|16@1+ (0.125,0) [0|8031.875] "rpm" Vector__XXX
 SG_ EngPercentTorqueAtIdlePoint1 : 16|8@1+ (1,-125) [-125|125] "%" Vector__XXX
 SG_ EngSpeedAtIdlePoint1 : 0|16@1+ (0.125,0) [0|8031.875] "rpm" Vector__XXX

BO_ 2147548612 EBC5: 8 Vector__XXX
 SG_ XBRAccelerationLimit : 16|8@1+ (0.1,-11.5) [-11.5|0] "+12.5" Vector__XXX
 SG_ XBRActiveCtrlMode : 12|4@1+ (1,0) [0|15] "" Vector__XXX
 SG_ XBRSystemState : 10|2@1+ (1,0) [0|3] "" Vector__XXX
 SG_ FoundationBrakeUse : 8|2@1+ (1,0) [0|3] "" Vector__XXX
 SG_ HillHolderMode : 5|3@1+ (1,0) [0|7] "" Vector__XXX
 SG_ HaltBrakeMode : 2|3@1+ (1,0) [0|7] "" Vector__XXX

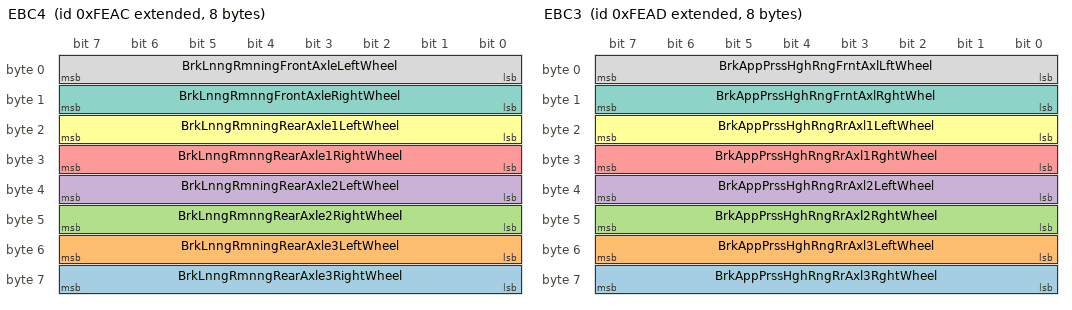
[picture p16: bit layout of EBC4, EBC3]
BO_ 2147548844 EBC4: 8 Vector__XXX
 SG_ BrkLnngRmnngRearAxle3RightWheel : 56|8@1+ (0.4,0) [0|100] "%" Vector__XXX
 SG_ BrkLnngRmningRearAxle3LeftWheel : 48|8@1+ (0.4,0) [0|100] "%" Vector__XXX
 SG_ BrkLnngRmnngRearAxle2RightWheel : 40|8@1+ (0.4,0) [0|100] "%" Vector__XXX
 SG_ BrkLnngRmningRearAxle2LeftWheel : 32|8@1+ (0.4,0) [0|100] "%" Vector__XXX
 SG_ BrkLnngRmnngRearAxle1RightWheel : 24|8@1+ (0.4,0) [0|100] "%" Vector__XXX
 SG_ BrkLnngRmningRearAxle1LeftWheel : 16|8@1+ (0.4,0) [0|100] "%" Vector__XXX
 SG_ BrkLnngRmnngFrontAxleRightWheel : 8|8@1+ (0.4,0) [0|100] "%" Vector__XXX
 SG_ BrkLnngRmningFrontAxleLeftWheel : 0|8@1+ (0.4,0) [0|100] "%" Vector__XXX

BO_ 2147548845 EBC3: 8 Vector__XXX
 SG_ BrkAppPrssHghRngRrAxl3RghtWheel : 56|8@1+ (5,0) [0|1250] "kPa" Vector__XXX
 SG_ BrkAppPrssHghRngRrAxl3LeftWheel : 48|8@1+ (5,0) [0|1250] "kPa" Vector__XXX
 SG_ BrkAppPrssHghRngRrAxl2RghtWheel : 40|8@1+ (5,0) [0|1250] "kPa" Vector__XXX
 SG_ BrkAppPrssHghRngRrAxl2LeftWheel : 32|8@1+ (5,0) [0|1250] "kPa" Vector__XXX
 SG_ BrkAppPrssHghRngRrAxl1RghtWheel : 24|8@1+ (5,0) [0|1250] "kPa" Vector__XXX
 SG_ BrkAppPrssHghRngRrAxl1LeftWheel : 16|8@1+ (5,0) [0|1250] "kPa" Vector__XXX
 SG_ BrkAppPrssHghRngFrntAxlRghtWhel : 8|8@1+ (5,0) [0|1250] "kPa" Vector__XXX
 SG_ BrkAppPrssHghRngFrntAxlLftWheel : 0|8@1+ (5,0) [0|1250] "kPa" Vector__XXX

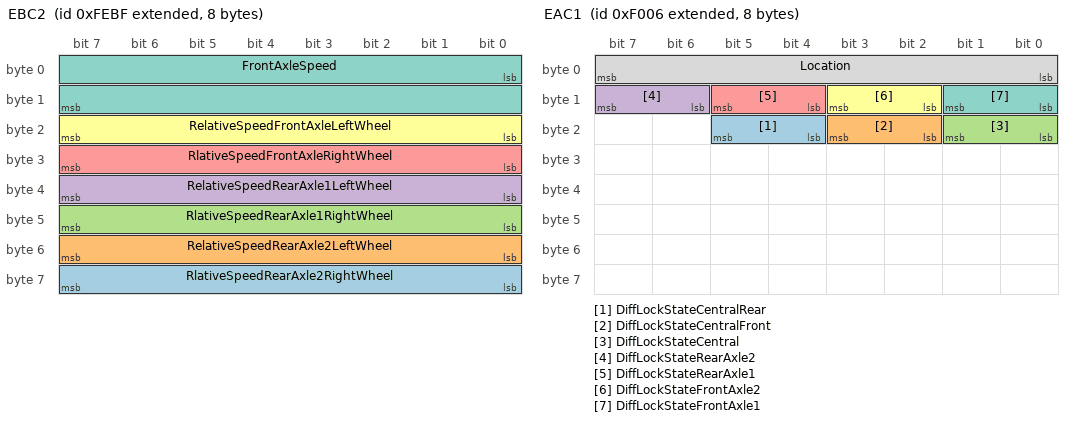
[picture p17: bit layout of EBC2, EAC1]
BO_ 2147548863 EBC2: 8 Vector__XXX
 SG_ RlativeSpeedRearAxle2RightWheel : 56|8@1+ (1,-6.1875) [-6.1875|7.8125] "km/h" Vector__XXX
 SG_ RelativeSpeedRearAxle2LeftWheel : 48|8@1+ (1,-6.1875) [-6.1875|7.8125] "km/h" Vector__XXX
 SG_ RlativeSpeedRearAxle1RightWheel : 40|8@1+ (1,-6.1875) [-6.1875|7.8125] "km/h" Vector__XXX
 SG_ RelativeSpeedRearAxle1LeftWheel : 32|8@1+ (1,-6.1875) [-6.1875|7.8125] "km/h" Vector__XXX
 SG_ RlativeSpeedFrontAxleRightWheel : 24|8@1+ (1,-6.1875) [-6.1875|7.8125] "km/h" Vector__XXX
 SG_ RelativeSpeedFrontAxleLeftWheel : 16|8@1+ (1,-6.1875) [-6.1875|7.8125] "km/h" Vector__XXX
 SG_ FrontAxleSpeed : 0|16@1+ (0.01,0) [0|655.35] "km/h" Vector__XXX

BO_ 2147545089 EBC1: 8 Vector__XXX
 SG_ SrcAddrssOfCtrllngDvcFrBrkCntrl : 48|8@1+ (1,0) [0|255] "" Vector__XXX
 SG_ BrakePedalPos : 8|8@1+ (0.4,0) [0|100] "%" Vector__XXX
 SG_ TrctrMntdTrilerABSWarningSignal : 62|2@1+ (1,0) [0|3] "" Vector__XXX
 SG_ TrailerABSStatus : 60|2@1+ (1,0) [0|3] "" Vector__XXX
 SG_ HaltBrakeSwitch : 58|2@1+ (1,0) [0|3] "" Vector__XXX
 SG_ ATC_ASRInformationSignal : 46|2@1+ (1,0) [0|3] "" Vector__XXX
 SG_ ABS_EBSAmberWarningSignal : 44|2@1+ (1,0) [0|3] "" Vector__XXX
 SG_ EBSRedWarningSignal : 42|2@1+ (1,0) [0|3] "" Vector__XXX
 SG_ ABSFullyOperational : 40|2@1+ (1,0) [0|3] "" Vector__XXX
 SG_ EngRetarderSelection : 32|8@1+ (0.4,0) [0|100] "%" Vector__XXX
 SG_ RemoteAccelEnableSwitch : 30|2@1+ (1,0) [0|3] "" Vector__XXX
 SG_ EngAuxEngShutdownSwitch : 28|2@1+ (1,0) [0|3] "" Vector__XXX
 SG_ EngDerateSwitch : 26|2@1+ (1,0) [0|3] "" Vector__XXX
 SG_ AccelInterlockSwitch : 24|2@1+ (1,0) [0|3] "" Vector__XXX
 SG_ TractionCtrlOverrideSwitch : 22|2@1+ (1,0) [0|3] "" Vector__XXX
 SG_ ASRHillHolderSwitch : 20|2@1+ (1,0) [0|3] "" Vector__XXX
 SG_ ASROffroadSwitch : 18|2@1+ (1,0) [0|3] "" Vector__XXX
 SG_ ABSOffroadSwitch : 16|2@1+ (1,0) [0|3] "" Vector__XXX
 SG_ EBSBrakeSwitch : 6|2@1+ (1,0) [0|3] "" Vector__XXX
 SG_ AntiLockBrakingActive : 4|2@1+ (1,0) [0|3] "" Vector__XXX
 SG_ ASRBrakeCtrlActive : 2|2@1+ (1,0) [0|3] "" Vector__XXX
 SG_ ASREngCtrlActive : 0|2@1+ (1,0) [0|3] "" Vector__XXX

BO_ 2147545094 EAC1: 8 Vector__XXX
 SG_ DiffLockStateCentralRear : 20|2@1+ (1,0) [0|3] "" Vector__XXX
 SG_ DiffLockStateCentralFront : 18|2@1+ (1,0) [0|3] "" Vector__XXX
 SG_ DiffLockStateCentral : 16|2@1+ (1,0) [0|3] "" Vector__XXX
 SG_ DiffLockStateRearAxle2 : 14|2@1+ (1,0) [0|3] "" Vector__XXX
 SG_ DiffLockStateRearAxle1 : 12|2@1+ (1,0) [0|3] "" Vector__XXX
 SG_ DiffLockStateFrontAxle2 : 10|2@1+ (1,0) [0|3] "" Vector__XXX
 SG_ DiffLockStateFrontAxle1 : 8|2@1+ (1,0) [0|3] "" Vector__XXX
 SG_ Location : 0|8@1+ (1,0) [0|255] "" Vector__XXX

BO_ 2147548820 EAC: 8 Vector__XXX
 SG_ SeaWaterPumpOutletPress : 16|8@1+ (2,0) [0|500] "kPa" Vector__XXX
 SG_ EngAuxCoolantTemp : 8|8@1+ (1,-40) [-40|210] "deg" Vector__XXX
 SG_ EngAuxCoolantPress : 0|8@1+ (4,0) [0|1000] "kPa" Vector__XXX

BO_ 2147548779 DI: 8 Vector__XXX

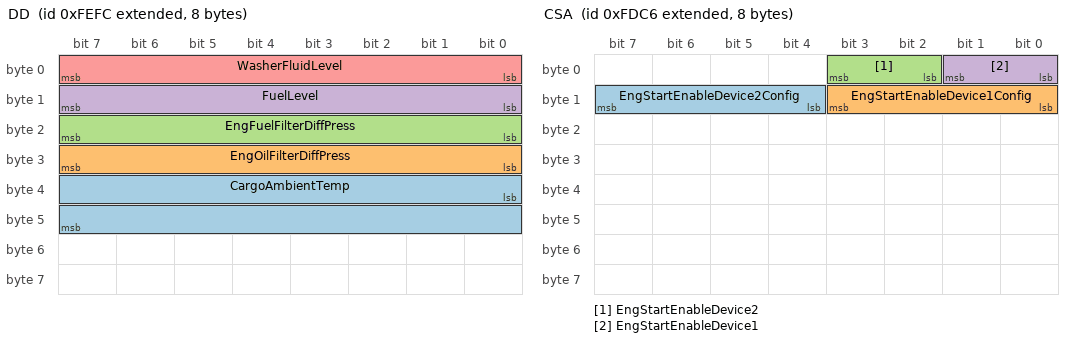
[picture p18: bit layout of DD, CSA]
BO_ 2147548924 DD: 8 Vector__XXX
 SG_ CargoAmbientTemp : 32|16@1+ (0.03125,-273) [-273|1735] "deg" Vector__XXX
 SG_ EngOilFilterDiffPress : 24|8@1+ (0.5,0) [0|125] "kPa" Vector__XXX
 SG_ EngFuelFilterDiffPress : 16|8@1+ (2,0) [0|500] "kPa" Vector__XXX
 SG_ FuelLevel : 8|8@1+ (0.4,0) [0|100] "%" Vector__XXX
 SG_ WasherFluidLevel : 0|8@1+ (0.4,0) [0|100] "%" Vector__XXX

BO_ 2147548750 DC: 8 Vector__XXX
 SG_ Ramp_WheelChairLiftPos : 4|2@1+ (1,0) [0|3] "" Vector__XXX
 SG_ PosOfDoors : 0|4@1+ (1,0) [0|15] "" Vector__XXX

BO_ 2147548614 CSA: 8 Vector__XXX
 SG_ EngStartEnableDevice2Config : 12|4@1+ (1,0) [0|15] "" Vector__XXX
 SG_ EngStartEnableDevice1Config : 8|4@1+ (1,0) [0|15] "" Vector__XXX
 SG_ EngStartEnableDevice2 : 2|2@1+ (1,0) [0|3] "" Vector__XXX
 SG_ EngStartEnableDevice1 : 0|2@1+ (1,0) [0|3] "" Vector__XXX

BO_ 2147548784 CVW: 8 Vector__XXX
 SG_ PoweredVehicleWeight : 0|16@1+ (10,0) [0|642550] "kg" Vector__XXX
 SG_ GrossCombinationVehicleWeight : 16|16@1+ (10,0) [0|642550] "kg" Vector__XXX

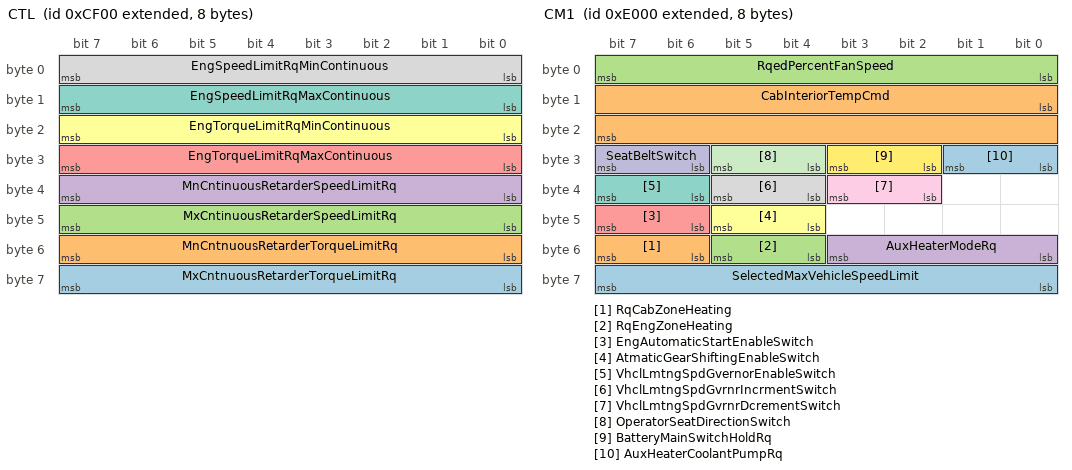
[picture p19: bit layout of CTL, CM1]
BO_ 2147536640 CTL: 8 Vector__XXX
 SG_ MxCntnuousRetarderTorqueLimitRq : 56|8@1+ (1,-125) [-125|125] "%" Vector__XXX
 SG_ MnCntnuousRetarderTorqueLimitRq : 48|8@1+ (1,-125) [-125|125] "%" Vector__XXX
 SG_ MxCntinuousRetarderSpeedLimitRq : 40|8@1+ (32,0) [0|8000] "rpm" Vector__XXX
 SG_ MnCntinuousRetarderSpeedLimitRq : 32|8@1+ (32,0) [0|8000] "rpm" Vector__XXX
 SG_ EngTorqueLimitRqMaxContinuous : 24|8@1+ (1,-125) [-125|125] "%" Vector__XXX
 SG_ EngTorqueLimitRqMinContinuous : 16|8@1+ (1,-125) [-125|125] "%" Vector__XXX
 SG_ EngSpeedLimitRqMaxContinuous : 8|8@1+ (32,0) [0|8000] "rpm" Vector__XXX
 SG_ EngSpeedLimitRqMinContinuous : 0|8@1+ (32,0) [0|8000] "rpm" Vector__XXX

BO_ 2147548800 CT6: 8 Vector__XXX
 SG_ EngAverageCombustionTime : 16|16@1+ (0.01,0) [0|642.55] "ms" Vector__XXX
 SG_ EngDesiredCombustionTime : 0|16@1+ (0.01,0) [0|642.55] "ms" Vector__XXX

BO_ 2147548799 CT5: 8 Vector__XXX
 SG_ EngCyl20CombustionTime : 48|16@1+ (0.01,0) [0|642.55] "ms" Vector__XXX
 SG_ EngCyl19CombustionTime : 32|16@1+ (0.01,0) [0|642.55] "ms" Vector__XXX
 SG_ EngCyl18CombustionTime : 16|16@1+ (0.01,0) [0|642.55] "ms" Vector__XXX
 SG_ EngCyl17CombustionTime : 0|16@1+ (0.01,0) [0|642.55] "ms" Vector__XXX

BO_ 2147548798 CT4: 8 Vector__XXX
 SG_ EngCyl16CombustionTime : 48|16@1+ (0.01,0) [0|642.55] "ms" Vector__XXX
 SG_ EngCyl15CombustionTime : 32|16@1+ (0.01,0) [0|642.55] "ms" Vector__XXX
 SG_ EngCyl14CombustionTime : 16|16@1+ (0.01,0) [0|642.55] "ms" Vector__XXX
 SG_ EngCyl13CombustionTime : 0|16@1+ (0.01,0) [0|642.55] "ms" Vector__XXX

BO_ 2147548797 CT3: 8 Vector__XXX
 SG_ EngCyl12CombustionTime : 48|16@1+ (0.01,0) [0|642.55] "ms" Vector__XXX
 SG_ EngCyl11CombustionTime : 32|16@1+ (0.01,0) [0|642.55] "ms" Vector__XXX
 SG_ EngCyl10CombustionTime : 16|16@1+ (0.01,0) [0|642.55] "ms" Vector__XXX
 SG_ EngCyl9CombustionTime : 0|16@1+ (0.01,0) [0|642.55] "ms" Vector__XXX

BO_ 2147548796 CT2: 8 Vector__XXX
 SG_ EngCyl8CombustionTime : 48|16@1+ (0.01,0) [0|642.55] "ms" Vector__XXX
 SG_ EngCyl7CombustionTime : 32|16@1+ (0.01,0) [0|642.55] "ms" Vector__XXX
 SG_ EngCyl6CombustionTime : 16|16@1+ (0.01,0) [0|642.55] "ms" Vector__XXX
 SG_ EngCyl5CombustionTime : 0|16@1+ (0.01,0) [0|642.55] "ms" Vector__XXX

BO_ 2147548795 CT1: 8 Vector__XXX
 SG_ EngCyl4CombustionTime : 48|16@1+ (0.01,0) [0|642.55] "ms" Vector__XXX
 SG_ EngCyl3CombustionTime : 32|16@1+ (0.01,0) [0|642.55] "ms" Vector__XXX
 SG_ EngCyl2CombustionTime : 16|16@1+ (0.01,0) [0|642.55] "ms" Vector__XXX
 SG_ EngCyl1CombustionTime : 0|16@1+ (0.01,0) [0|642.55] "ms" Vector__XXX

BO_ 2147548617 CMI: 8 Vector__XXX
 SG_ TotalCountOfConfigChangesMade : 0|16@1+ (1,0) [0|64255] "counts" Vector__XXX

BO_ 2147548628 CM3: 8 Vector__XXX
 SG_ TransferCaseSelectorSwitch : 0|3@1+ (1,0) [0|7] "" Vector__XXX

BO_ 2147540992 CM1: 8 Vector__XXX
 SG_ SelectedMaxVehicleSpeedLimit : 56|8@1+ (1,0) [0|250] "" Vector__XXX
 SG_ RqCabZoneHeating : 54|2@1+ (1,0) [0|3] "" Vector__XXX
 SG_ RqEngZoneHeating : 52|2@1+ (1,0) [0|3] "" Vector__XXX
 SG_ AuxHeaterModeRq : 48|4@1+ (1,0) [0|15] "" Vector__XXX
 SG_ EngAutomaticStartEnableSwitch : 46|2@1+ (1,0) [0|3] "" Vector__XXX
 SG_ AtmaticGearShiftingEnableSwitch : 44|2@1+ (1,0) [0|3] "" Vector__XXX
 SG_ VhclLmtngSpdGvernorEnableSwitch : 38|2@1+ (1,0) [0|3] "" Vector__XXX
 SG_ VhclLmtngSpdGvrnrIncrmentSwitch : 36|2@1+ (1,0) [0|3] "" Vector__XXX
 SG_ VhclLmtngSpdGvrnrDcrementSwitch : 34|2@1+ (1,0) [0|3] "" Vector__XXX
 SG_ SeatBeltSwitch : 30|2@1+ (1,0) [0|3] "" Vector__XXX
 SG_ OperatorSeatDirectionSwitch : 28|2@1+ (1,0) [0|3] "" Vector__XXX
 SG_ BatteryMainSwitchHoldRq : 26|2@1+ (1,0) [0|3] "" Vector__XXX
 SG_ AuxHeaterCoolantPumpRq : 24|2@1+ (1,0) [0|3] "" Vector__XXX
 SG_ CabInteriorTempCmd : 8|16@1+ (0.03125,-273) [-273|1735] "deg" Vector__XXX
 SG_ RqedPercentFanSpeed : 0|8@1+ (0.4,0) [0|100] "%" Vector__XXX

BO_ 2147536896 CL: 8 Vector__XXX
 SG_ IlluminationBrightnessPercent : 0|8@1+ (0.4,0) [0|100] "%" Vector__XXX

BO_ 2147548907 CI: 8 Vector__XXX

BO_ 2147548913 CCVS: 8 Vector__XXX
 SG_ EngShutdownOverrideSwitch : 62|2@1+ (1,0) [0|3] "" Vector__XXX
 SG_ EngTestModeSwitch : 60|2@1+ (1,0) [0|3] "" Vector__XXX
 SG_ EngIdleDecrementSwitch : 58|2@1+ (1,0) [0|3] "" Vector__XXX
 SG_ EngIdleIncrementSwitch : 56|2@1+ (1,0) [0|3] "" Vector__XXX
 SG_ CruiseCtrlStates : 53|3@1+ (1,0) [0|7] "" Vector__XXX
 SG_ PTOState : 48|5@1+ (1,0) [0|31] "" Vector__XXX
 SG_ CruiseCtrlSetSpeed : 40|8@1+ (1,0) [0|250] "km/h" Vector__XXX
 SG_ CruiseCtrlAccelerateSwitch : 38|2@1+ (1,0) [0|3] "" Vector__XXX
 SG_ CruiseCtrlResumeSwitch : 36|2@1+ (1,0) [0|3] "" Vector__XXX
 SG_ CruiseCtrlCoastSwitch : 34|2@1+ (1,0) [0|3] "" Vector__XXX
 SG_ CruiseCtrlSetSwitch : 32|2@1+ (1,0) [0|3] "" Vector__XXX
 SG_ ClutchSwitch : 30|2@1+ (1,0) [0|3] "" Vector__XXX
 SG_ BrakeSwitch : 28|2@1+ (1,0) [0|3] "" Vector__XXX
 SG_ CruiseCtrlEnableSwitch : 26|2@1+ (1,0) [0|3] "" Vector__XXX
 SG_ CruiseCtrlActive : 24|2@1+ (1,0) [0|3] "" Vector__XXX
 SG_ WheelBasedVehicleSpeed : 8|16@1+ (0.00390625,0) [0|250.99609375] "km/h" Vector__XXX
 SG_ CruiseCtrlPauseSwitch : 4|2@1+ (1,0) [0|3] "" Vector__XXX
 SG_ ParkingBrakeSwitch : 2|2@1+ (1,0) [0|3] "" Vector__XXX
 SG_ TwoSpeedAxleSwitch : 0|2@1+ (1,0) [0|3] "" Vector__XXX

BO_ 2147548909 CCSS: 8 Vector__XXX
 SG_ CruiseCtrlLowSetLimitSpeed : 16|8@1+ (1,0) [0|250] "km/h" Vector__XXX
 SG_ CruiseCtrlHighSetLimitSpeed : 8|8@1+ (1,0) [0|250] "km/h" Vector__XXX
 SG_ MaxVehicleSpeedLimit : 0|8@1+ (1,0) [0|250] "km/h" Vector__XXX

BO_ 2147548775 CCC: 8 Vector__XXX
 SG_ AuxHeaterMaxOutputPower : 0|16@1+ (2,0) [0|128510] "W" Vector__XXX

BO_ 2147548860 CBI: 16 Vector__XXX
 SG_ TripServiceBrakeApps : 96|32@1+ (1,0) [0|4227858431] "appl" Vector__XXX
 SG_ TripServiceBrakeDistance : 64|32@1+ (0.125,0) [0|526385151.9] "km" Vector__XXX
 SG_ TripCompressionBrakeDistance : 32|32@1+ (0.125,0) [0|526385151.9] "km" Vector__XXX
 SG_ TotalCompressionBrakeDistance : 0|32@1+ (0.125,0) [0|526385151.9] "km" Vector__XXX

BO_ 2147548641 CACI: 8 Vector__XXX
 SG_ CbA_CRfrgrntCmprssorOutletPress : 0|8@1+ (16,0) [0|4000] "kPa" Vector__XXX

BO_ 2147548752 BT1: 8 Vector__XXX
 SG_ Battery2Temp : 8|8@1+ (1,-40) [-40|210] "deg" Vector__XXX
 SG_ Battery1Temp : 0|8@1+ (1,-40) [-40|210] "deg" Vector__XXX

BO_ 2147548774 BM: 8 Vector__XXX
 SG_ BatteryMainSwitchHoldState : 0|2@1+ (1,0) [0|3] "" Vector__XXX

BO_ 2147548634 BJM3: 8 Vector__XXX
 SG_ Joystick3XAxisDetentPosStatus : 38|2@1+ (1,0) [0|3] "" Vector__XXX
 SG_ Joystick3Button9PressedStatus : 62|2@1+ (1,0) [0|3] "" Vector__XXX
 SG_ Joystick3Button10PressedStatus : 60|2@1+ (1,0) [0|3] "" Vector__XXX
 SG_ Joystick3Button11PressedStatus : 58|2@1+ (1,0) [0|3] "" Vector__XXX
 SG_ Joystick3Button12PressedStatus : 56|2@1+ (1,0) [0|3] "" Vector__XXX
 SG_ Joystick3YAxisDetentPosStatus : 36|2@1+ (1,0) [0|3] "" Vector__XXX
 SG_ Joystick3YAxisPos : 22|10@1+ (0.1,0) [0|102] "%" Vector__XXX
 SG_ Jystck3YAxsLvrFrwrdPstvPsStatus : 20|2@1+ (1,0) [0|3] "" Vector__XXX
 SG_ Jystck3YAxsLvrBckNgtvePosStatus : 18|2@1+ (1,0) [0|3] "" Vector__XXX
 SG_ Joystick3YAxisNeutralPosStatus : 16|2@1+ (1,0) [0|3] "" Vector__XXX
 SG_ Joystick3XAxisPos : 6|10@1+ (0.1,0) [0|102] "%" Vector__XXX
 SG_ Jystck3XAxsLvrRghtPstvPosStatus : 4|2@1+ (1,0) [0|3] "" Vector__XXX
 SG_ Jystck3XAxsLvrLftNgtvePosStatus : 2|2@1+ (1,0) [0|3] "" Vector__XXX
 SG_ Joystick3XAxisNeutralPosStatus : 0|2@1+ (1,0) [0|3] "" Vector__XXX
 SG_ Joystick3Button5PressedStatus : 54|2@1+ (1,0) [0|3] "" Vector__XXX
 SG_ Joystick3Button6PressedStatus : 52|2@1+ (1,0) [0|3] "" Vector__XXX
 SG_ Joystick3Button7PressedStatus : 50|2@1+ (1,0) [0|3] "" Vector__XXX
 SG_ Joystick3Button8PressedStatus : 48|2@1+ (1,0) [0|3] "" Vector__XXX
 SG_ Joystick3Button1PressedStatus : 46|2@1+ (1,0) [0|3] "" Vector__XXX
 SG_ Joystick3Button2PressedStatus : 44|2@1+ (1,0) [0|3] "" Vector__XXX
 SG_ Joystick3Button3PressedStatus : 42|2@1+ (1,0) [0|3] "" Vector__XXX
 SG_ Joystick3Button4PressedStatus : 40|2@1+ (1,0) [0|3] "" Vector__XXX

BO_ 2147548632 BJM2: 8 Vector__XXX
 SG_ Joystick2XAxisDetentPosStatus : 38|2@1+ (1,0) [0|3] "" Vector__XXX
 SG_ Joystick2YAxisDetentPosStatus : 36|2@1+ (1,0) [0|3] "" Vector__XXX
 SG_ Joystick2YAxisPos : 22|10@1+ (0.1,0) [0|102] "%" Vector__XXX
 SG_ Jystck2YAxsLvrFrwrdPstvPsStatus : 20|2@1+ (1,0) [0|3] "" Vector__XXX
 SG_ Jystck2YAxsLvrBckNgtvePosStatus : 18|2@1+ (1,0) [0|3] "" Vector__XXX
 SG_ Joystick2YAxisNeutralPosStatus : 16|2@1+ (1,0) [0|3] "" Vector__XXX
 SG_ Joystick2XAxisPos : 6|10@1+ (0.1,0) [0|102] "%" Vector__XXX
 SG_ Jystck2XAxsLvrRghtPstvPosStatus : 4|2@1+ (1,0) [0|3] "" Vector__XXX
 SG_ Jystck2XAxsLvrLftNgtvePosStatus : 2|2@1+ (1,0) [0|3] "" Vector__XXX
 SG_ Joystick2XAxisNeutralPosStatus : 0|2@1+ (1,0) [0|3] "" Vector__XXX
 SG_ Joystick2Button9PressedStatus : 62|2@1+ (1,0) [0|3] "" Vector__XXX
 SG_ Joystick2Button10PressedStatus : 60|2@1+ (1,0) [0|3] "" Vector__XXX
 SG_ Joystick2Button11PressedStatus : 58|2@1+ (1,0) [0|3] "" Vector__XXX
 SG_ Joystick2Button12PressedStatus : 56|2@1+ (1,0) [0|3] "" Vector__XXX
 SG_ Joystick2Button5PressedStatus : 54|2@1+ (1,0) [0|3] "" Vector__XXX
 SG_ Joystick2Button6PressedStatus : 52|2@1+ (1,0) [0|3] "" Vector__XXX
 SG_ Joystick2Button7PressedStatus : 50|2@1+ (1,0) [0|3] "" Vector__XXX
 SG_ Joystick2Button8PressedStatus : 48|2@1+ (1,0) [0|3] "" Vector__XXX
 SG_ Joystick2Button1PressedStatus : 46|2@1+ (1,0) [0|3] "" Vector__XXX
 SG_ Joystick2Button2PressedStatus : 44|2@1+ (1,0) [0|3] "" Vector__XXX
 SG_ Joystick2Button3PressedStatus : 42|2@1+ (1,0) [0|3] "" Vector__XXX
 SG_ Joystick2Button4PressedStatus : 40|2@1+ (1,0) [0|3] "" Vector__XXX

CM_ BO_ 2147548636 "Marine Control Information";
CM_ SG_ 2147548636 SlowVesselModeStatus "The status of the Slow Vessel Mode.";
CM_ SG_ 2147548636 TrollingModeStatus "The status of the Trolling Mode.";
CM_ SG_ 2147548636 EngThrttlSynchrnztionModeStatus "The status of the Throttle Synchronization Mode.";
CM_ BO_ 2147548828 "Main Bearing Temperature 3";
CM_ SG_ 2147548828 EngMainBearing11Temp "Temperature of the main bearing which supports the crankshaft of the engine.";
CM_ SG_ 2147548828 EngMainBearing10Temp "Temperature of the main bearing which supports the crankshaft of the engine.";
CM_ SG_ 2147548828 EngMainBearing9Temp "Temperature of the main bearing which supports the crankshaft of the engine.";
CM_ BO_ 2147548829 "Main Bearing Temperature 2";
CM_ SG_ 2147548829 EngMainBearing8Temp "Temperature of the main bearing which supports the crankshaft of the engine.";
CM_ SG_ 2147548829 EngMainBearing7Temp "Temperature of the main bearing which supports the crankshaft of the engine.";
CM_ SG_ 2147548829 EngMainBearing6Temp "Temperature of the main bearing which supports the crankshaft of the engine.";
CM_ SG_ 2147548829 EngMainBearing5Temp "Temperature of the main bearing which supports the crankshaft of the engine.";
CM_ BO_ 2147548830 "Main Bearing Temperature 1";
CM_ SG_ 2147548830 EngMainBearing4Temp "Temperature of the main bearing which supports the crankshaft of the engine.";
CM_ SG_ 2147548830 EngMainBearing3Temp "Temperature of the main bearing which supports the crankshaft of the engine.";
CM_ SG_ 2147548830 EngMainBearing2Temp "Temperature of the main bearing which supports the crankshaft of the engine.";
CM_ SG_ 2147548830 EngMainBearing1Temp "Temperature of the main bearing which supports the crankshaft of the engine.";
CM_ BO_ 2147548790 "Laser Leveling System Vertical Position Display Data";
CM_ SG_ 2147548790 DisplayDeadbands "Sets Display Deadbands mode.";
CM_ SG_ 2147548790 LEDPatternCtrl "Sets LED Pattern control mode on laser leveling systems.";
CM_ SG_ 2147548790 LEDDisplayDeadbandCtrl "This parameter informs the system what the selected Display deadband will be.";
CM_ SG_ 2147548790 LEDDisplayModeCtrl "This parameter informs the system what the selected Display mode will be.";
CM_ SG_ 2147548790 LEDDisplayData1 "Informs display devices how to display the current vertical position.";
CM_ BO_ 2147548789 "Laser Leveling System Vertical Deviation";
CM_ SG_ 2147548789 AbsLaserStrikePosition "Laser Strike location on the survey type laser receiver.";
CM_ SG_ 2147548789 LaserStrikeDataLatency "Time from laser strike to CAN message transmission.";
CM_ SG_ 2147548789 LaserReceiverType "Identifies which type of Laser Receiver transmitted the message.";
CM_ SG_ 2147548789 LaserStrikeVerticalDeviation "The calculated distance from the laser strike position to the current land leveling system reference point.";
CM_ BO_ 2147548785 "Laser Tracer Position";
CM_ SG_ 2147548785 LaserTracerInformation "Provides the status of the laser tracer to the operator.";
CM_ SG_ 2147548785 LEDDisplayData2 "Informs display devices how to display the current position of the laser tracer.";
CM_ SG_ 2147548785 LaserTracerHorizontalDeviation "The calculated percent deviation between the target distance and the center of the laser tracer.";
CM_ SG_ 2147548785 LaserTracerVerticalDistance "The elevation of the laser tracer sensor in a laser leveling system.";
CM_ SG_ 2147548785 LaserTracerTargetDeviation "The calculated distance for the laser target to the current laser tracer reference point.";
CM_ BO_ 2147548857 "Trip Fuel Information (Liquid)";
CM_ SG_ 2147548857 TripCruiseFuelUsed "Total fuel consumed while the engine is in the cruise hold state since the last trip reset.";
CM_ BO_ 2147548788 "Modify Leveling System Control Set Point";
CM_ SG_ 2147548788 BldHeightSetPointHighResolution "High resolution for the laser guided blade set point.";
CM_ SG_ 2147548788 ModifySetPoint "Used to control and coordinate the set point for the leveling system.";
CM_ BO_ 2147545101 "Land Leveling System Operational Information";
CM_ SG_ 2147545101 DesiredGradeOffsetSwitch "This parameter indicates the grade offset switch state the user has set for the land leveling system.";
CM_ SG_ 2147545101 BladeCtrlModeSwitch "This parameter indicates the blade control mode switch state the user has set for the land leveling system.";
CM_ BO_ 2147548787 "Laser Receiver Mast Position";
CM_ SG_ 2147548787 MastPos "Used to monitor the position of the sensor attached to the land leveling mast.";
CM_ BO_ 2147548851 "Fuel Information (Liquid)";
CM_ SG_ 2147548851 TripAverageFuelRate "Average fuel rate, equal to trip fuel divided by trip time while the engine speed is above zero, since the last trip reset.";
CM_ SG_ 2147548851 TotalEngPTOFuelUsed "Total fuel used while the PTO or remote PTO is in the hold state and engine speed is above zero, over the life of the engine.";
CM_ BO_ 2147548914 "Fuel Economy (Liquid)";
CM_ SG_ 2147548914 EngAverageFuelEconomy "Average of instantaneous fuel economy for that segment of vehicle operation of interest.";
CM_ SG_ 2147548914 EngInstantaneousFuelEconomy "Current fuel economy at current vehicle velocity.";
CM_ SG_ 2147548914 EngFuelRate "Amount of fuel consumed by engine per unit of time.";
CM_ SG_ 2147548914 EngThrottlePos "The position of the valve used to regulate the supply of a fluid, usually air or fuel/air mixture, to an engine.";
CM_ BO_ 2147548905 "Fuel Consumption (Liquid)";
CM_ SG_ 2147548905 EngTotalFuelUsed "Accumulated amount of fuel used during vehicle operation.";
CM_ SG_ 2147548905 EngTripFuel "Fuel consumed during all or part of a journey.";
CM_ BO_ 2147548639 "Front Wheel Drive Status";
CM_ SG_ 2147548639 FrontWheelDriveActuatorStatus "Feedback on the front wheel drive actuator.";
CM_ BO_ 2147548625 "FMS-standard Interface Identity/Capabilities";
CM_ BO_ 2147548763 "Forward Lane Image";
CM_ SG_ 2147548763 LnDprtureIndicationEnableStatus "Indicates whether lane departure indication is active.";
CM_ SG_ 2147548763 LaneTrackingStatusLeftSide "Indicates whether the left side is tracking lane.";
CM_ SG_ 2147548763 LaneTrackingStatusRightSide "Indicates whether right side is tracking lane.";
CM_ BO_ 2147545095 "Forward Lane Image urgent msg";
CM_ SG_ 2147545095 LaneDepartureImminentLeftSide "Indicates departure imminent on left side of lane.";
CM_ SG_ 2147545095 LaneDepartureImminentRightSide "Indicates departure imminent on right side of lane.";
CM_ BO_ 2147548817 "Fuel Leakage";
CM_ SG_ 2147548817 EngFuelLeakage2 "Status signal which indicates fuel leakage in the fuel rail of the engine.";
CM_ SG_ 2147548817 EngFuelLeakage1 "Status signal which indicates fuel leakage in the fuel rail of the engine.";
CM_ BO_ 2147548861 "Fan Drive";
CM_ SG_ 2147548861 FanSpeed "The speed of the fan associated with engine coolant system.";
CM_ SG_ 2147548861 FanDriveState "This parameter is used to indicate the current state or mode of operation by the fan drive.";
CM_ SG_ 2147548861 EstPercentFanSpeed "Estimated fan speed as a ratio of the fan drive (current speed) to the fully engaged fan drive (maximum fan speed).";
CM_ BO_ 2147548816 "Engine Torque History";
CM_ SG_ 2147548816 EngTorqueLimit6AxleInput "Limit applied to the engine output torque based on the maximum allowable axle input torque.";
CM_ SG_ 2147548816 EngTorqueLimit5Switch "Limit applied to the engine output torque based on activation of an ECU switch input.";
CM_ SG_ 2147548816 EngTorqueLimitFeature "Torque limit rating described in the current record.";
CM_ SG_ 2147548816 TorqueLimitingFeatureStatus "Status of an ECU feature which limits the torque output of the engine.";
CM_ SG_ 2147548816 CalibRecordDurationTime "Duration in hours for which the engine operated in the conditions captured in the current record.";
CM_ SG_ 2147548816 CalibRecordStartYear "Calendar year timestamp when an ECU record was established.";
CM_ SG_ 2147548816 CalibRecordStartDay "Calendar day timestamp when an ECU record was established.";
CM_ SG_ 2147548816 CalibRecordStartMonth "Calendar month timestamp when an ECU record was established.";
CM_ SG_ 2147548816 EngPeakTorque2 "Maximum torque output of the current ECU calibration when the engine operates on torque curve 2.";
CM_ SG_ 2147548816 EngPeakTorque1 "Maximum torque output of the current ECU calibration when the engine operates on torque curve 1.";
CM_ SG_ 2147548816 EngPower "Advertised engine power capability.";
CM_ SG_ 2147548816 NumberOfEngTorqueHistoryRecords "Number of torque history records contained in the engine torque history PGN.";
CM_ BO_ 2147545100 "Electronic Transmission Controller #8";
CM_ SG_ 2147545100 TransTorqueConverterRatio "Ratio of the transmissions torque converter output torque to torque converter input torque at current speed.";
CM_ BO_ 2147548746 "Electronic Transmission Controller 7";
CM_ SG_ 2147548746 TransShiftInhibitIndicator "State signal indicating a transmission request for the Shift Inhibit Indicator to be active or inactive.";
CM_ SG_ 2147548746 TransEngCrankEnable "State signal from the transmission indicating if the transmission’s status is such that engine cranking is allowed (i.";
CM_ BO_ 2147548843 "Electronic Transmission Controller 6";
CM_ SG_ 2147548843 ClutchLifeRemaining "Signal which indicates the actual clutch life remaining in percent.";
CM_ SG_ 2147548843 LowestPossibleGear "The transmission calculates this gear continuously.";
CM_ SG_ 2147548843 HighestPossibleGear "The transmission calculates this gear continuously.";
CM_ SG_ 2147548843 RecommendedGear "The transmission calculates this gear continuously.";
CM_ BO_ 2147548867 "Electronic Transmission Controller 5";
CM_ SG_ 2147548867 TransForwardDirectionSwitch "Identifies the status of the switch that indicates forward direction.";
CM_ SG_ 2147548867 TransNeutralSwitch "Identifies the status of the switch that indicates neutral.";
CM_ SG_ 2147548867 TransReverseDirectionSwitch "Identifies the status of the switch that indicates reverse direction.";
CM_ SG_ 2147548867 TransLowRangeSenseSwitch "Identifies the status of the switch that represents low range.";
CM_ SG_ 2147548867 TransHighRangeSenseSwitch "Identifies the status of the switch that represents high range.";
CM_ BO_ 2147548869 "Electronic Transmission Controller 4";
CM_ SG_ 2147548869 TransSynchronizerBrakeValue "The current modulated value for the air supply to the synchronizer brake.";
CM_ SG_ 2147548869 TransSynchronizerClutchValue "The current modulated value for the air supply to the synchronizer clutch.";
CM_ BO_ 2147548871 "Electronic Transmission Controller 3";
CM_ SG_ 2147548871 TransInertiaBrakeActuator "Identifies the status of the actuator that controls the inertia brake.";
CM_ SG_ 2147548871 TransDefuelActuator "Identifies the status of the actuator that controls the engine defuel mechanism.";
CM_ SG_ 2147548871 TransLockupClutchActuator "Identifies the status of the actuator that controls the lockup clutch.";
CM_ SG_ 2147548871 TransClutchActuator "Identifies the status of the actuator that controls the clutch.";
CM_ SG_ 2147548871 TransSplitterIndirectActuator "Identifies the status of the splitter indirect actuator in the auxiliary unit.";
CM_ SG_ 2147548871 TransSplitterDirectActuator "Identifies the status of the splitter direct actuator in the auxiliary unit.";
CM_ SG_ 2147548871 TransRangeLowActuator "Identifies the status of the range low actuator in the auxiliary unit.";
CM_ SG_ 2147548871 TransRangeHighActuator "Identifies the status of the range high actuator in the auxiliary unit.";
CM_ SG_ 2147548871 TransShiftFingerGearActuator2 "Identifies the status of the actuator that moves the shift finger identified as gear actuator #2.";
CM_ SG_ 2147548871 TransShiftFingerRailActuator2 "Identifies the status of the actuator that moves the shift finger identified as rail actuator #2.";
CM_ SG_ 2147548871 TransShiftFingerGearActuator1 "Identifies the status of the actuator that moves the shift finger identified as gear actuator #1.";
CM_ SG_ 2147548871 TransShiftFingerRailActuator1 "Identifies the status of the actuator that moves the shift finger identified as rail actuator #1.";
CM_ SG_ 2147548871 TrnsShftFngrCenterRailIndicator "Identifies the status of the shift finger in the center rail position.";
CM_ SG_ 2147548871 TrnsShftFngrEngagementIndicator "Identifies the status of the shift finger in the engagement position.";
CM_ SG_ 2147548871 TrnsShiftFingerNeutralIndicator "Indicates the status of the shift finger in the neutral position.";
CM_ SG_ 2147548871 TransShiftFingerRailPos "The current position of the shift finger in the rail direction.";
CM_ SG_ 2147548871 TransShiftFingerGearPos "The current position of the shift finger in the gear direction.";
CM_ BO_ 2147545093 "Electronic Transmission Controller 2";
CM_ SG_ 2147545093 TransCurrentRange "Range currently being commanded by the transmission control system.";
CM_ SG_ 2147545093 TransRqedRange "Range selected by the operator.";
CM_ SG_ 2147545093 TransActualGearRatio "Actual ratio of input shaft speed to output shaft speed.";
CM_ BO_ 2147545090 "Electronic Transmission Controller 1";
CM_ SG_ 2147545090 SrcAddrssOfCtrllngDvcFrTrnsCtrl "The source address of the SAE J1939 device currently controlling the transmission.";
CM_ SG_ 2147545090 TransInputShaftSpeed "Rotational velocity of the primary shaft transferring power into the transmission.";
CM_ SG_ 2147545090 ProgressiveShiftDisable "Command signal used to indicate that progressive shifting by the engine should be disallowed.";
CM_ SG_ 2147545090 PercentClutchSlip "Parameter which represents the ratio of input shaft speed to current engine speed (in percent).";
CM_ SG_ 2147545090 TransOutputShaftSpeed "Calculated speed of the transmission output shaft.";
CM_ SG_ 2147545090 TransShiftInProcess "Indicates that the transmission is in process of shifting from the current gear to the selected gear.";
CM_ SG_ 2147545090 TorqueConverterLockupEngaged "State signal which indicates whether the torque converter lockup is engaged.";
CM_ BO_ 2147548777 "Engine Temperature 3";
CM_ SG_ 2147548777 EngCoolantTempHiRes "Temperature of liquid found in engine cooling system.";
CM_ SG_ 2147548777 EngIntkVlvActationSystemOilTemp "The temperature of the oil in the hydraulic system that powers the intake valve actuation system.";
CM_ SG_ 2147548777 EngIntakeManifold1AirTemp "Temperature of pre-combustion air found in intake manifold of engine air supply system.";
CM_ BO_ 2147548836 "Engine Temperature 2";
CM_ SG_ 2147548836 EngECUTemp "Temperature of the engine electronic control unit.";
CM_ SG_ 2147548836 EngOilTemp2 "Temperature of the engine lubricant.";
CM_ BO_ 2147548910 "Engine Temperature 1";
CM_ SG_ 2147548910 EngIntercoolerThermostatOpening "The current position of the thermostat used to regulate the temperature of the engine intercooler.";
CM_ SG_ 2147548910 EngIntercoolerTemp "Temperature of liquid found in the intercooler located after the turbocharger.";
CM_ SG_ 2147548910 EngTurboOilTemp "Temperature of the turbocharger lubricant.";
CM_ SG_ 2147548910 EngOilTemp1 "Temperature of the engine lubricant.";
CM_ SG_ 2147548910 EngFuelTemp "Temperature of fuel entering injectors.";
CM_ SG_ 2147548910 EngCoolantTemp "Temperature of liquid found in engine cooling system.";
CM_ BO_ 2147548679 "Exhaust Temperature";
CM_ SG_ 2147548679 EngExhstExhstGsTempLeftManifold "Temperature of combustion byproducts within the left engine exhaust manifold.";
CM_ SG_ 2147548679 EngExhstExhstGsTmpRightManifold "Temperature of combustion byproducts within the right engine exhaust manifold.";
CM_ BO_ 2147545099 "Electronic Steering Control";
CM_ SG_ 2147545099 SterableLiftAxleLoweringInhibit "A signal which indicates if lowering of lifted axle is allowed or inhibited.";
CM_ SG_ 2147545099 AxleLocation "To identify to which of several similar devices (such as tires or fuel tanks) the information applies.";
CM_ SG_ 2147545099 TypeOfSteerTrans "Type of Steering Transmission (Ref.";
CM_ SG_ 2147545099 TypeOfSteerForces "Type of Steering Forces (Ref.";
CM_ SG_ 2147545099 SteerType "Indicates the different types of steering systems (ref.";
CM_ SG_ 2147545099 ActualInnerWheelSteerAngle "Signal which indicates the actual inner wheel steering angle.";
CM_ BO_ 2147548866 "Electronic Retarder Controller 2";
CM_ SG_ 2147548866 TransOutputRetarder "Identifies the status of the transmission output retarder.";
CM_ BO_ 2147545088 "Electronic Retarder Controller 1";
CM_ SG_ 2147545088 ActlMxAvlblRtarderPercentTorque "This is the maximum amount of torque that the retarder can immediately deliver.";
CM_ SG_ 2147545088 SrcAddrssOfCtrllngDvcFrRtrdrCtrl "The source address of the SAE J1939 device currently controlling the retarder.";
CM_ SG_ 2147545088 EngCoolantLoadIncrease "Status of an event, external to the engine, that may increase the nominal temperature of the engine coolant liquid.";
CM_ SG_ 2147545088 IntendedRetarderPercentTorque "Braking torque of retarder that the retarder is currently trying to achieve.";
CM_ SG_ 2147545088 ActualRetarderPercentTorque "Actual braking torque of the retarder as a percent of retarder configuration reference torque SPN 556.";
CM_ SG_ 2147545088 RetarderEnableShiftAssistSwitch "Switch signal which indicates whether the operator wishes the retarder to be enabled for transmission shift assist.";
CM_ SG_ 2147545088 RetarderEnableBrakeAssistSwitch "Switch signal which indicates whether the operator wishes the retarder to be enabled for vehicle braking assist.";
CM_ SG_ 2147545088 RetarderTorqueMode "State signal which indicates which retarder torque mode is currently generating, limiting, or controlling the torque.";
CM_ BO_ 2147548831 "Exhaust Port Temperature 5";
CM_ SG_ 2147548831 EngExhaustGasPort20Temp "Temperature at the cylinder exhaust port of the engine.";
CM_ SG_ 2147548831 EngExhaustGasPort19Temp "Temperature at the cylinder exhaust port of the engine.";
CM_ SG_ 2147548831 EngExhaustGasPort18Temp "Temperature at the cylinder exhaust port of the engine.";
CM_ SG_ 2147548831 EngExhaustGasPort17Temp "Temperature at the cylinder exhaust port of the engine.";
CM_ BO_ 2147548832 "Exhaust Port Temperature 4";
CM_ SG_ 2147548832 EngExhaustGasPort16Temp "Temperature at the cylinder exhaust port of the engine.";
CM_ SG_ 2147548832 EngExhaustGasPort15Temp "Temperature at the cylinder exhaust port of the engine.";
CM_ SG_ 2147548832 EngExhaustGasPort14Temp "Temperature at the cylinder exhaust port of the engine.";
CM_ SG_ 2147548832 EngExhaustGasPort13Temp "Temperature at the cylinder exhaust port of the engine.";
CM_ BO_ 2147548833 "Exhaust Port Temperature 3";
CM_ SG_ 2147548833 EngExhaustGasPort12Temp "Temperature at the cylinder exhaust port of the engine.";
CM_ SG_ 2147548833 EngExhaustGasPort11Temp "Temperature at the cylinder exhaust port of the engine.";
CM_ SG_ 2147548833 EngExhaustGasPort10Temp "Temperature at the cylinder exhaust port of the engine.";
CM_ SG_ 2147548833 EngExhaustGasPort9Temp "Temperature at the cylinder exhaust port of the engine.";
CM_ BO_ 2147548834 "Exhaust Port Temperature 2";
CM_ SG_ 2147548834 EngExhaustGasPort8Temp "Temperature at the cylinder exhaust port of the engine.";
CM_ SG_ 2147548834 EngExhaustGasPort7Temp "Temperature at the cylinder exhaust port of the engine.";
CM_ SG_ 2147548834 EngExhaustGasPort6Temp "Temperature at the cylinder exhaust port of the engine.";
CM_ SG_ 2147548834 EngExhaustGasPort5Temp "Temperature at the cylinder exhaust port of the engine.";
CM_ BO_ 2147548835 "Exhaust Port Temperature 1";
CM_ SG_ 2147548835 EngExhaustGasPort4Temp "Temperature at the cylinder exhaust port of the engine.";
CM_ SG_ 2147548835 EngExhaustGasPort3Temp "Temperature at the cylinder exhaust port of the engine.";
CM_ SG_ 2147548835 EngExhaustGasPort2Temp "Temperature at the cylinder exhaust port of the engine.";
CM_ SG_ 2147548835 EngExhaustGasPort1Temp "Temperature at the cylinder exhaust port of the engine.";
CM_ BO_ 2147548644 "Equipment Performance Data";
CM_ SG_ 2147548644 PayloadPercentage "The current payload of the equipment, reported as a percentage of the equipment's rated payload limit.";
CM_ BO_ 2147548626 "ECU Performance";
CM_ SG_ 2147548626 DataMemoryUsage "The used storage capacity of the data buffer memory internal to an ECU, such as a data logger.";
CM_ SG_ 2147548626 KeepAliveBatteryConsumption "The capacity consumed from the direct battery connection since the key was last turned off.";
CM_ BO_ 2147548643 "Equipment Operation and Control";
CM_ BO_ 2147548841 "Exhaust Oxygen 1";
CM_ SG_ 2147548841 EngExhstGsOxygnSnsrClsdLpOprton "Indicates whether the engine is using the Exhaust Gas Oxygen sensor to control the air/fuel ratio.";
CM_ BO_ 2147548635 "Extended Joystick Message 3";
CM_ SG_ 2147548635 Jystck3GripXAxisDetentPosStatus "Reports when the current joystick grip position is in the detent position for that axis of travel.";
CM_ SG_ 2147548635 Jystck3GripYAxisDetentPosStatus "Reports when the current joystick grip position is in the detent position for that axis of travel.";
CM_ SG_ 2147548635 Jystck3ThetaAxisDetentPosStatus "Reports when the current joystick position is in the detent position for that axis of travel.";
CM_ SG_ 2147548635 Joystick3ThetaAxisPos "The position of the joystick in the relative motion of travel from the neutral position.";
CM_ SG_ 2147548635 Jystck3ThtaAxisNeutralPosStatus "Reports when the current joystick position is in the neutral position for that axis of travel.";
CM_ SG_ 2147548635 Joystick3GripYAxisPos "The position of the joystick grip in the relative motion of travel from the neutral position.";
CM_ SG_ 2147548635 Jystck3GrpYAxisNeutralPosStatus "Reports when the current joystick grip position is in the neutral position for that axis of travel.";
CM_ SG_ 2147548635 Joystick3GripXAxisPos "The position of the joystick grip in the relative motion of travel from the neutral position.";
CM_ SG_ 2147548635 Jystck3GrpXAxisNeutralPosStatus "Reports when the current joystick grip position is in the neutral position for that axis of travel.";
CM_ BO_ 2147548633 "Extended Joystick Message 2";
CM_ SG_ 2147548633 Jystck2GripXAxisDetentPosStatus "Reports when the current joystick grip position is in the detent position for that axis of travel.";
CM_ SG_ 2147548633 Jystck2GripYAxisDetentPosStatus "Reports when the current joystick grip position is in the detent position for that axis of travel.";
CM_ SG_ 2147548633 Jystck2ThetaAxisDetentPosStatus "Reports when the current joystick position is in the detent position for that axis of travel.";
CM_ SG_ 2147548633 Joystick2ThetaAxisPos "The position of the joystick in the relative motion of travel from the neutral position.";
CM_ SG_ 2147548633 Jystck2ThtaAxisNeutralPosStatus "Reports when the current joystick position is in the neutral position for that axis of travel.";
CM_ SG_ 2147548633 Joystick2GripYAxisPos "The position of the joystick grip in the relative motion of travel from the neutral position.";
CM_ SG_ 2147548633 Jystck2GrpYAxisNeutralPosStatus "Reports when the current joystick grip position is in the neutral position for that axis of travel.";
CM_ SG_ 2147548633 Joystick2GripXAxisPos "The position of the joystick grip in the relative motion of travel from the neutral position.";
CM_ SG_ 2147548633 Jystck2GrpXAxisNeutralPosStatus "Reports when the current joystick grip position is in the neutral position for that axis of travel.";
CM_ BO_ 2147548631 "Extended Joystick Message 1";
CM_ SG_ 2147548631 Jystck1GripXAxisDetentPosStatus "Reports when the current joystick grip position is in the detent position for that axis of travel.";
CM_ SG_ 2147548631 Jystck1GripYAxisDetentPosStatus "Reports when the current joystick grip position is in the detent position for that axis of travel.";
CM_ SG_ 2147548631 Jystck1ThetaAxisDetentPosStatus "Reports when the current joystick position is in the detent position for that axis of travel.";
CM_ SG_ 2147548631 Joystick1ThetaAxisPos "The position of the joystick in the relative motion of travel from the neutral position.";
CM_ SG_ 2147548631 Jystck1ThtaAxisNeutralPosStatus "Reports when the current joystick position is in the neutral position for that axis of travel.";
CM_ SG_ 2147548631 Joystick1GripYAxisPos "The position of the joystick grip in the relative motion of travel from the neutral position.";
CM_ SG_ 2147548631 Jystck1GrpYAxisNeutralPosStatus "Reports when the current joystick grip position is in the neutral position for that axis of travel.";
CM_ SG_ 2147548631 Joystick1GripXAxisPos "The position of the joystick grip in the relative motion of travel from the neutral position.";
CM_ SG_ 2147548631 Jystck1GrpXAxisNeutralPosStatus "Reports when the current joystick grip position is in the neutral position for that axis of travel.";
CM_ BO_ 2147548818 "Engine Information";
CM_ SG_ 2147548818 EngFuelRackPos "Measured position of the engine fuel rack.";
CM_ SG_ 2147548818 InstantaneousEstBrakePower "Estimate of the power developed by the engine.";
CM_ SG_ 2147548818 EngMassFlow "Mass flow of natural gas to the engine.";
CM_ SG_ 2147548818 EngExhaustGasPress "Gage pressure of the exhaust gasses as measured at the turbine inlet of the turbocharger.";
CM_ SG_ 2147548818 EngPrefilterOilPress "Gage pressure of the engine oil before the oil reaches the oil filter.";
CM_ BO_ 2147548849 "ECU History";
CM_ SG_ 2147548849 TotalECURunTime "Total time accumulated over the life of the ECU, from ignition switch ON to ignition switch OFF.";
CM_ SG_ 2147548849 TotalECUDistance "Total distance accumulated over the life of the ECU.";
CM_ BO_ 2147545098 "Engine Gas Flow Rate";
CM_ SG_ 2147545098 EngInletAirMassFlowRate "Mass flow rate of fresh air entering the engine air intake, before any EGR mixer, if used.";
CM_ SG_ 2147545098 EngExhstGsRcrcltionMassFlowRate "Flow rate of gas through the EGR system.";
CM_ BO_ 2147548778 "Engine Fuel/lube systems";
CM_ SG_ 2147548778 EngFuelFilterSucSideDiffPress "Differential pressure measured across the fuel filter located between the fuel tank and the supply pump.";
CM_ SG_ 2147548778 EngFuelSupplyPumpInletPress "Absolute pressure of fuel at the fuel supply pump inlet.";
CM_ SG_ 2147548778 EngOilLevelRemoteReservoir "Ratio of current volume of engine oil in a remote reservoir to the maximum required volume.";
CM_ BO_ 2147548609 "Engine Fluid Level/Pressure 3";
CM_ BO_ 2147548891 "Engine Fluid Level/Pressure 2";
CM_ SG_ 2147548891 EngInjectorMeteringRail2Press "The gage pressure of fuel in the metering rail #2 as delivered from the supply pump to the injector metering inlet.";
CM_ SG_ 2147548891 EngInjectorTimingRail1Press "The gage pressure of fuel in the timing rail delivered from the supply pump to the injector timing inlet.";
CM_ SG_ 2147548891 EngInjectionCtrlPress "The gage pressure of the engine oil in the hydraulic accumulator that powers an intensifier used for fuel injection.";
CM_ BO_ 2147548911 "Engine Fluid Level/Pressure 1";
CM_ SG_ 2147548911 EngCoolantLevel "Ratio of volume of liquid found in engine cooling system to total cooling system volume.";
CM_ SG_ 2147548911 EngCoolantPress "Gage pressure of liquid found in engine cooling system.";
CM_ SG_ 2147548911 EngCrankcasePress "Gage pressure inside engine crankcase.";
CM_ SG_ 2147548911 EngOilPress "Gage pressure of oil in engine lubrication system as provided by oil pump.";
CM_ SG_ 2147548911 EngOilLevel "Ratio of current volume of engine sump oil to maximum required volume.";
CM_ SG_ 2147548911 EngExCrankcaseBlowbyPress "Differential crankcase blow-by pressure as measured through a tube with a venturi.";
CM_ SG_ 2147548911 EngFuelDeliveryPress "Gage pressure of fuel in system as delivered from supply pump to the injection pump.";
CM_ BO_ 2147548819 "Engine Electrical System/Module Information";
CM_ SG_ 2147548819 TurningGearEngaged "Status signal which indicates that the turning gear is engaged.";
CM_ SG_ 2147548819 SafetyWireStatus "Status signal which indicates that the safety wire has been activated.";
CM_ SG_ 2147548819 ElectricalLoad "Electrical power delivered by the engine to the electrical system connected to the generator.";
CM_ BO_ 2147548629 "Electronic Engine Controller 5";
CM_ SG_ 2147548629 EngVrblGometryTurbo1ActuatorPos "Sensor that measures the position of the variable geometry turbocharger actuator.";
CM_ SG_ 2147548629 EngVrblGmtryTrbArCtrlShtffValve "Isolates vehicle brake air from the Variable Geometry Turbocharger (VGT) system when engine is not running.";
CM_ SG_ 2147548629 EngExhstGsRcirculationValveCtrl "Desired percentage of maximum Exhaust Gas Recirculation (EGR) valve opening.";
CM_ SG_ 2147548629 EngTrb1ClcltedTurbineOutletTemp "Calculated value of turbocharger compressor outlet air temperature.";
CM_ BO_ 2147548862 "Electronic Engine Controller 4";
CM_ SG_ 2147548862 EngRatedSpeed "The maximum governed rotational velocity of the engine crankshaft under full load conditions.";
CM_ SG_ 2147548862 EngRatedPower "Net brake power that the engine will deliver continuously, specified for a given application at a rated speed.";
CM_ BO_ 2147548895 "Electronic Engine Controller 3";
CM_ SG_ 2147548895 EngsDesiredOperatingSpeed "An indication by the engine of the optimal operating speed of the engine for the current existing conditions.";
CM_ BO_ 2147545091 "Electronic Engine Controller 2";
CM_ SG_ 2147545091 VhclAccelerationRateLimitStatus "Status (active or not active) of the system used to limit maximum forward vehicle acceleration.";
CM_ SG_ 2147545091 AccelPedal2LowIdleSwitch "Switch signal which indicates the state of the accelerator pedal 2 low idle switch.";
CM_ SG_ 2147545091 RoadSpeedLimitStatus "Status (active or not active) of the system used to limit maximum vehicle velocity.";
CM_ SG_ 2147545091 AccelPedalKickdownSwitch "Switch signal which indicates whether the accelerator pedal kickdown switch is opened or closed.";
CM_ SG_ 2147545091 AccelPedal1LowIdleSwitch "Switch signal which indicates the state of the accelerator pedal 1 low idle switch.";
CM_ BO_ 2147545092 "Electronic Engine Controller 1";
CM_ SG_ 2147545092 EngStarterMode "There are several phases in a starting action and different reasons why a start cannot take place.";
CM_ SG_ 2147545092 SrcAddrssOfCtrllngDvcForEngCtrl "The source address of the SAE J1939 device currently controlling the engine.";
CM_ SG_ 2147545092 ActualEngPercentTorque "The calculated output torque of the engine.";
CM_ SG_ 2147545092 DriversDemandEngPercentTorque "The requested torque output of the engine by the driver.";
CM_ SG_ 2147545092 EngTorqueMode "State signal which indicates which engine torque mode is currently generating, limiting, or controlling the torque.";
CM_ BO_ 2147548613 "ECU Identification Information";
CM_ BO_ 2147548756 "Engine Continuous Torque & Speed Limit";
CM_ SG_ 2147548756 EngMaxContinuousTorque "Applied limit for maximum continuous engine torque.";
CM_ SG_ 2147548756 EngHghLmtThrshhldFrMnCntnsTrqFrm "Maximum allowable value for minimum continuous torque.";
CM_ SG_ 2147548756 EngLwLmtThrshldFrMxTrqueFromEng "Minimum allowable value for maximum continuous torque.";
CM_ BO_ 2147548899 "Engine Configuration";
CM_ SG_ 2147548899 EngDefaultTorqueLimit "Companion parameter to Transmission Torque Limit (SPN 1845).";
CM_ SG_ 2147548899 EngMomentOfInertia "Moment of inertia for the engine, including items driven full-time by the engine such as fuel, oil and cooling pumps.";
CM_ SG_ 2147548899 EngRqdTorqueCtrlRangeUpperLimit "The maximum engine torque that the engine will allow when operating in a torque control/limit mode.";
CM_ SG_ 2147548899 EngRqdTorqueCtrlRangeLowerLimit "The minimum engine torque that the engine will allow when operating in a torque control/limit mode.";
CM_ SG_ 2147548899 EngRqedSpeedCtrlRangeLowerLimit "The minimum engine speed that the engine will allow when operating in a speed control/limit mode.";
CM_ SG_ 2147548899 EngMxMomentaryOverrideTimeLimit "The maximum time limit allowed to override the engine's high idle speed.";
CM_ SG_ 2147548899 EngMxMmntaryOverrideSpeedPoint7 "The maximum engine speed above high idle allowed by the engine control during a momentary high idle override.";
CM_ SG_ 2147548899 EngReferenceTorque "This parameter is the 100% reference value for all defined indicated engine torque parameters.";
CM_ SG_ 2147548899 EngSpeedAtHighIdlePoint6 "Engine speed of high idle (point 6) of the engine torque map (see PGN 65251 and supporting document).";
CM_ SG_ 2147548899 EngSpeedAtPoint5 "Engine speed of point 3, 4, and 5 of the engine torque map (see PGN 65251 and supporting document).";
CM_ SG_ 2147548899 EngSpeedAtPoint4 "Engine speed of point 3, 4, and 5 of the engine torque map (see PGN 65251 and supporting document).";
CM_ SG_ 2147548899 EngSpeedAtPoint3 "Engine speed of point 3, 4, and 5 of the engine torque map (see PGN 65251 and supporting document).";
CM_ SG_ 2147548899 EngSpeedAtPoint2 "Engine speed of point 2 of the engine torque map (see PGN 65251 and supporting document).";
CM_ SG_ 2147548899 EngPercentTorqueAtIdlePoint1 "The torque limit that indicates the available engine torque which can be provided by the engine at idle speed.";
CM_ BO_ 2147548612 "Electronic Brake Controller 5";
CM_ SG_ 2147548612 XBRAccelerationLimit "The brake system may temporarily or generally limit the maximum brake performance available for external systems.";
CM_ SG_ 2147548612 XBRActiveCtrlMode "This parameter indicates which XBR Control Mode is executed by the brake system.";
CM_ SG_ 2147548612 XBRSystemState "This parameter indicates which external brake control is allowed.";
CM_ SG_ 2147548612 FoundationBrakeUse "This parameter indicates if the brake system presently uses the foundation brakes.";
CM_ SG_ 2147548612 HillHolderMode "Signal which indicates the current mode of the hill holder function.";
CM_ SG_ 2147548612 HaltBrakeMode "Signal which indicates the current mode of the halt brake function.";
CM_ BO_ 2147548844 "Wheel Brake Lining Remaining Information";
CM_ SG_ 2147548844 BrkLnngRmnngRearAxle3RightWheel "The percentage of brake lining which can still be measured for the right wheel on the rear axle #3.";
CM_ SG_ 2147548844 BrkLnngRmningRearAxle3LeftWheel "The percentage of brake lining which can still be measured for the left wheel on the rear axle #3.";
CM_ SG_ 2147548844 BrkLnngRmnngRearAxle2RightWheel "The percentage of brake lining which can still be measured for the right wheel on the rear axle #2.";
CM_ SG_ 2147548844 BrkLnngRmningRearAxle2LeftWheel "The percentage of brake lining which can still be measured for the left wheel on the rear axle #2.";
CM_ SG_ 2147548844 BrkLnngRmnngRearAxle1RightWheel "The percentage of brake lining which can still be measured for the right wheel on the rear axle #1.";
CM_ SG_ 2147548844 BrkLnngRmningRearAxle1LeftWheel "The percentage of brake lining which can still be measured for the left wheel on the rear axle #1.";
CM_ SG_ 2147548844 BrkLnngRmnngFrontAxleRightWheel "The percentage of brake lining which can still be measured for the right wheel on the front axle.";
CM_ SG_ 2147548844 BrkLnngRmningFrontAxleLeftWheel "The percentage of brake lining which can still be measured for the left wheel on the front axle.";
CM_ BO_ 2147548845 "Wheel Application Pressure High Range Information";
CM_ SG_ 2147548845 BrkAppPrssHghRngRrAxl3RghtWheel "The brake application pressure for the right wheel on the rear axle #3.";
CM_ SG_ 2147548845 BrkAppPrssHghRngRrAxl3LeftWheel "The brake application pressure for the left wheel on the rear axle #3.";
CM_ SG_ 2147548845 BrkAppPrssHghRngRrAxl2RghtWheel "The brake application pressure for the right wheel on the rear axle #2.";
CM_ SG_ 2147548845 BrkAppPrssHghRngRrAxl2LeftWheel "The brake application pressure for the left wheel on the rear axle #2.";
CM_ SG_ 2147548845 BrkAppPrssHghRngRrAxl1RghtWheel "The brake application pressure for the right wheel on the rear axle #1.";
CM_ SG_ 2147548845 BrkAppPrssHghRngRrAxl1LeftWheel "The brake application pressure for the left wheel on the rear axle #1.";
CM_ SG_ 2147548845 BrkAppPrssHghRngFrntAxlRghtWhel "The brake application pressure for the right wheel on the front axle.";
CM_ SG_ 2147548845 BrkAppPrssHghRngFrntAxlLftWheel "The brake application pressure for the left wheel on the front axle.";
CM_ BO_ 2147548863 "Wheel Speed Information";
CM_ SG_ 2147548863 RlativeSpeedRearAxle2RightWheel "The speed of the rear axle #2, right wheel relative to the front axle speed, SPN 904.";
CM_ SG_ 2147548863 RelativeSpeedRearAxle2LeftWheel "The speed of the rear axle #2, left wheel relative to the front axle speed, SPN 904.";
CM_ SG_ 2147548863 RlativeSpeedRearAxle1RightWheel "The speed of the rear axle #1, right wheel relative to the front axle speed, SPN 904.";
CM_ SG_ 2147548863 RelativeSpeedRearAxle1LeftWheel "The speed of the rear axle #1, left wheel relative to the front axle speed, SPN 904.";
CM_ SG_ 2147548863 RlativeSpeedFrontAxleRightWheel "The speed of the front axle, right wheel relative to the front axle speed, SPN 904.";
CM_ SG_ 2147548863 RelativeSpeedFrontAxleLeftWheel "The speed of the front axle, left wheel relative to the front axle speed, SPN 904.";
CM_ SG_ 2147548863 FrontAxleSpeed "The average speed of the two front wheels.";
CM_ BO_ 2147545089 "Electronic Brake Controller 1";
CM_ SG_ 2147545089 SrcAddrssOfCtrllngDvcFrBrkCntrl "The source address of the SAE J1939 device currently controlling the brake system.";
CM_ SG_ 2147545089 BrakePedalPos "Ratio of brake pedal position to maximum pedal position.";
CM_ SG_ 2147545089 TrctrMntdTrilerABSWarningSignal "This parameter commands the tractor-mounted trailer ABS optical warning signal.";
CM_ SG_ 2147545089 TrailerABSStatus "State signal which indicates that ABS in the trailer is actively controlling the brakes.";
CM_ SG_ 2147545089 HaltBrakeSwitch "Switch signal which indicates the position of the halt brake switch.";
CM_ SG_ 2147545089 ATC_ASRInformationSignal "This parameter commands the ATC/ASR driver information signal, for example a dash lamp.";
CM_ SG_ 2147545089 RemoteAccelEnableSwitch "Switch signal which indicates that the remote accelerator has been enabled and controls the engine.";
CM_ SG_ 2147545089 EngAuxEngShutdownSwitch "Switch signal which requests that all engine fueling stop.";
CM_ SG_ 2147545089 EngDerateSwitch "Switch signal used to activate the torque limiting feature of the engine.";
CM_ SG_ 2147545089 AccelInterlockSwitch "Switch signal used to disable the accelerator and remote accelerator inputs, causing the engine to return to idle.";
CM_ SG_ 2147545089 TractionCtrlOverrideSwitch "Switch signal which indicates the position of the traction control override switch.";
CM_ SG_ 2147545089 ASRHillHolderSwitch "Switch signal which indicates the position of the ASR “hill holder” switch.";
CM_ SG_ 2147545089 ASROffroadSwitch "Switch signal which indicates the position of the ASR off-road switch.";
CM_ SG_ 2147545089 ABSOffroadSwitch "Switch signal which indicates the position of the ABS off-road switch.";
CM_ SG_ 2147545089 EBSBrakeSwitch "Switch signal which indicates that the brake pedal is being pressed.";
CM_ SG_ 2147545089 AntiLockBrakingActive "State signal which indicates that the ABS is active.";
CM_ SG_ 2147545089 ASRBrakeCtrlActive "State signal which indicates that ASR brake control is active.";
CM_ SG_ 2147545089 ASREngCtrlActive "State signal which indicates that ASR engine control has been commanded to be active.";
CM_ BO_ 2147545094 "Electronic Axle Controller 1";
CM_ SG_ 2147545094 DiffLockStateCentralRear "State used which indicates the condition of the central rear differential lock.";
CM_ SG_ 2147545094 DiffLockStateCentralFront "State used which indicates the condition of the central front differential lock.";
CM_ SG_ 2147545094 DiffLockStateCentral "State used which indicates the condition of the central differential lock.";
CM_ SG_ 2147545094 DiffLockStateRearAxle2 "State used which indicates the condition of the rear axle 2 differential lock.";
CM_ SG_ 2147545094 DiffLockStateRearAxle1 "State used which indicates the condition of the rear axle 1 differential lock.";
CM_ SG_ 2147545094 DiffLockStateFrontAxle2 "State used which indicates the condition of the front axle 2 differential lock.";
CM_ SG_ 2147545094 DiffLockStateFrontAxle1 "State used which indicates the condition of the front axle 1 differential lock.";
CM_ SG_ 2147545094 Location "To identify to which of several similar devices (such as tires or fuel tanks) the information applies.";
CM_ BO_ 2147548820 "Engine Auxiliary Coolant";
CM_ SG_ 2147548820 SeaWaterPumpOutletPress "Gauge pressure of liquid found at outlet of sea water pump in sea water cooling system.";
CM_ SG_ 2147548820 EngAuxCoolantTemp "Temperature of coolant found in the intercooler which is located after the turbocharger.";
CM_ SG_ 2147548820 EngAuxCoolantPress "Gage pressure of coolant found in the intercooler which is located after the turbocharger.";
CM_ BO_ 2147548779 "Driver's Identification";
CM_ BO_ 2147548924 "Dash Display";
CM_ SG_ 2147548924 CargoAmbientTemp "Temperature of air inside vehicle container used to accommodate cargo.";
CM_ SG_ 2147548924 EngFuelFilterDiffPress "Differential pressure measured across the fuel filter located between the fuel tank and the supply pump.";
CM_ SG_ 2147548924 FuelLevel "Ratio of volume of fuel to the total volume of fuel storage container.";
CM_ SG_ 2147548924 WasherFluidLevel "Ratio of volume of liquid to total container volume of fluid reservoir in windshield wash system.";
CM_ BO_ 2147548750 "Door Control";
CM_ SG_ 2147548750 Ramp_WheelChairLiftPos "Signal which indicates the actual position of the ramp / wheel chair lift.";
CM_ SG_ 2147548750 PosOfDoors "Signal which indicates the actual position of the doors.";
CM_ BO_ 2147548614 "Cold Start Aids";
CM_ SG_ 2147548614 EngStartEnableDevice2Config "The start enable device installed for start enable device 2.";
CM_ SG_ 2147548614 EngStartEnableDevice1Config "The start enable device installed for start enable device 1.";
CM_ SG_ 2147548614 EngStartEnableDevice2 "Devices that assist an engine in starting, e.";
CM_ SG_ 2147548614 EngStartEnableDevice1 "Devices that assist an Engine in starting, e.";
CM_ BO_ 2147548784 "Combination Vehicle Weight";
CM_ SG_ 2147548784 PoweredVehicleWeight "Total mass imposed by the tires of the powered vehicle on the road surface.";
CM_ SG_ 2147548784 GrossCombinationVehicleWeight "The total weight of the truck and all attached trailers.";
CM_ BO_ 2147536640 "Continuous Torque & Speed Limit Request";
CM_ BO_ 2147548800 "Combustion Time 6";
CM_ SG_ 2147548800 EngAverageCombustionTime "The average combustion time of all cylinders of an engine.";
CM_ SG_ 2147548800 EngDesiredCombustionTime "The desired combustion time based upon engine load and speed lookup maps.";
CM_ BO_ 2147548799 "Combustion Time 5";
CM_ SG_ 2147548799 EngCyl20CombustionTime "The amount of time from when the ignition of the fuel is initiated to when the fuel is completely ignited (i.";
CM_ SG_ 2147548799 EngCyl19CombustionTime "The amount of time from when the ignition of the fuel is initiated to when the fuel is completely ignited (i.";
CM_ SG_ 2147548799 EngCyl18CombustionTime "The amount of time from when the ignition of the fuel is initiated to when the fuel is completely ignited (i.";
CM_ SG_ 2147548799 EngCyl17CombustionTime "The amount of time from when the ignition of the fuel is initiated to when the fuel is completely ignited (i.";
CM_ BO_ 2147548798 "Combustion Time 4";
CM_ SG_ 2147548798 EngCyl16CombustionTime "The amount of time from when the ignition of the fuel is initiated to when the fuel is completely ignited (i.";
CM_ SG_ 2147548798 EngCyl15CombustionTime "The amount of time from when the ignition of the fuel is initiated to when the fuel is completely ignited (i.";
CM_ SG_ 2147548798 EngCyl14CombustionTime "The amount of time from when the ignition of the fuel is initiated to when the fuel is completely ignited (i.";
CM_ SG_ 2147548798 EngCyl13CombustionTime "The amount of time from when the ignition of the fuel is initiated to when the fuel is completely ignited (i.";
CM_ BO_ 2147548797 "Combustion Time 3";
CM_ SG_ 2147548797 EngCyl12CombustionTime "The amount of time from when the ignition of the fuel is initiated to when the fuel is completely ignited (i.";
CM_ SG_ 2147548797 EngCyl11CombustionTime "The amount of time from when the ignition of the fuel is initiated to when the fuel is completely ignited (i.";
CM_ SG_ 2147548797 EngCyl10CombustionTime "The amount of time from when the ignition of the fuel is initiated to when the fuel is completely ignited (i.";
CM_ SG_ 2147548797 EngCyl9CombustionTime "The amount of time from when the ignition of the fuel is initiated to when the fuel is completely ignited (i.";
CM_ BO_ 2147548796 "Combustion Time 2";
CM_ SG_ 2147548796 EngCyl8CombustionTime "The amount of time from when the ignition of the fuel is initiated to when the fuel is completely ignited (i.";
CM_ SG_ 2147548796 EngCyl7CombustionTime "The amount of time from when the ignition of the fuel is initiated to when the fuel is completely ignited (i.";
CM_ SG_ 2147548796 EngCyl6CombustionTime "The amount of time from when the ignition of the fuel is initiated to when the fuel is completely ignited (i.";
CM_ SG_ 2147548796 EngCyl5CombustionTime "The amount of time from when the ignition of the fuel is initiated to when the fuel is completely ignited (i.";
CM_ BO_ 2147548795 "Combustion Time 1";
CM_ SG_ 2147548795 EngCyl4CombustionTime "The amount of time from when the ignition of the fuel is initiated to when the fuel is completely ignited (i.";
CM_ SG_ 2147548795 EngCyl3CombustionTime "The amount of time from when the ignition of the fuel is initiated to when the fuel is completely ignited (i.";
CM_ SG_ 2147548795 EngCyl2CombustionTime "The amount of time from when the ignition of the fuel is initiated to when the fuel is completely ignited (i.";
CM_ SG_ 2147548795 EngCyl1CombustionTime "The amount of time from when the ignition of the fuel is initiated to when the fuel is completely ignited (i.";
CM_ BO_ 2147548617 "Electronic Control Module Information";
CM_ SG_ 2147548617 TotalCountOfConfigChangesMade "Total number of times changes have been made to any of the configurable parameters.";
CM_ BO_ 2147548628 "Cab Message 3";
CM_ SG_ 2147548628 TransferCaseSelectorSwitch "Operator switch to select the condition of the transfer case.";
CM_ BO_ 2147540992 "Cab Message 1";
CM_ SG_ 2147540992 RqCabZoneHeating "Request to activate cab zone heating.";
CM_ SG_ 2147540992 RqEngZoneHeating "Request to activate engine zone heating.";
CM_ SG_ 2147540992 AuxHeaterModeRq "Request to activate the auxiliary heater.";
CM_ SG_ 2147540992 EngAutomaticStartEnableSwitch "Switch signal which enables the idle management system to be enabled.";
CM_ SG_ 2147540992 VhclLmtngSpdGvrnrIncrmentSwitch "Switch signal which increases the Vehicle Limiting Speed Governor (VLSG).";
CM_ SG_ 2147540992 VhclLmtngSpdGvrnrDcrementSwitch "Switch signal which decreases the Vehicle Limiting Speed Governor (VLSG).";
CM_ SG_ 2147540992 BatteryMainSwitchHoldRq "Request to hold the battery main switch.";
CM_ SG_ 2147540992 AuxHeaterCoolantPumpRq "Indicates whether to activate the auxiliary heater coolant water pump.";
CM_ SG_ 2147540992 CabInteriorTempCmd "Parameter used to command a certain cab interior temperature.";
CM_ SG_ 2147540992 RqedPercentFanSpeed "Fan speed as a ratio of the actual fan drive (current speed) to the fully engaged fan drive (maximum fan speed).";
CM_ BO_ 2147536896 "Cab Illumination Message";
CM_ BO_ 2147548907 "Component Identification";
CM_ BO_ 2147548913 "Cruise Control/Vehicle Speed";
CM_ SG_ 2147548913 EngShutdownOverrideSwitch "Switch signal which indicates the position of the engine shutdown override switch.";
CM_ SG_ 2147548913 EngTestModeSwitch "Switch signal which indicates the position of the engine test mode switch.";
CM_ SG_ 2147548913 EngIdleDecrementSwitch "Switch signal which indicates the position of the idle decrement switch.";
CM_ SG_ 2147548913 EngIdleIncrementSwitch "Switch signal which indicates the position of the idle increment switch.";
CM_ SG_ 2147548913 CruiseCtrlStates "This parameter is used to indicate the current state, or mode, of operation by the cruise control device.";
CM_ SG_ 2147548913 PTOState "This parameter is used to indicate the current state or mode of operation by the power takeoff (PTO) device.";
CM_ SG_ 2147548913 CruiseCtrlSetSpeed "Value of set (chosen) velocity of velocity control system.";
CM_ SG_ 2147548913 CruiseCtrlAccelerateSwitch "Switch signal of the cruise control activator which indicates that the activator is in the position “accelerate.";
CM_ SG_ 2147548913 CruiseCtrlResumeSwitch "Switch signal of the cruise control activator which indicates that the activator is in the position “resume.";
CM_ SG_ 2147548913 CruiseCtrlCoastSwitch "Switch signal of the cruise control activator which indicates that the activator is in the position “coast (decelerate).";
CM_ SG_ 2147548913 CruiseCtrlSetSwitch "Switch signal of the cruise control activator which indicates that the activator is in the position “set.";
CM_ SG_ 2147548913 ClutchSwitch "Switch signal which indicates that the clutch pedal is being pressed.";
CM_ SG_ 2147548913 BrakeSwitch "Switch signal which indicates that the driver operated brake foot pedal is being pressed.";
CM_ SG_ 2147548913 CruiseCtrlEnableSwitch "Switch signal which indicates that it is possible to manage the cruise control function.";
CM_ SG_ 2147548913 CruiseCtrlActive "Cruise control is switched on.";
CM_ SG_ 2147548913 WheelBasedVehicleSpeed "Speed of the vehicle as calculated from wheel or tailshaft speed.";
CM_ SG_ 2147548913 CruiseCtrlPauseSwitch "Switch signal which indicates the position of the Cruise Control Pause Switch used on Remote Cruise Control applications.";
CM_ SG_ 2147548913 ParkingBrakeSwitch "Switch signal which indicates when the parking brake is set.";
CM_ SG_ 2147548913 TwoSpeedAxleSwitch "Switch signal which indicates the current axle range.";
CM_ BO_ 2147548909 "Cruise Control/Vehicle Speed Setup";
CM_ SG_ 2147548909 CruiseCtrlHighSetLimitSpeed "Maximum vehicle velocity at which cruise can be set.";
CM_ SG_ 2147548909 MaxVehicleSpeedLimit "Maximum vehicle velocity allowed.";
CM_ BO_ 2147548775 "Climate Control Configuration";
CM_ SG_ 2147548775 AuxHeaterMaxOutputPower "The maximum output power of the auxiliary heater.";
CM_ BO_ 2147548860 "Compression/Service Brake Information";
CM_ SG_ 2147548860 TripServiceBrakeApps "Total number of times the service brakes have been activated since the last trip reset.";
CM_ SG_ 2147548860 TripServiceBrakeDistance "Total distance over which the service brakes have been active since the last trip reset.";
CM_ SG_ 2147548860 TripCompressionBrakeDistance "Total distance over which the compression brakes have been active since the last trip reset.";
CM_ SG_ 2147548860 TotalCompressionBrakeDistance "Total distance over which the compression brakes have been active for the life of the engine.";
CM_ BO_ 2147548641 "Cab A/C Climate System Information";
CM_ SG_ 2147548641 CbA_CRfrgrntCmprssorOutletPress "This is the gage pressure at the compressor outlet in the cab air conditioning system.";
CM_ BO_ 2147548752 "Battery Temperature";
CM_ SG_ 2147548752 Battery2Temp "Temperature of the battery 2.";
CM_ SG_ 2147548752 Battery1Temp "Temperature of the battery 1.";
CM_ BO_ 2147548774 "Battery Main Switch Information";
CM_ SG_ 2147548774 BatteryMainSwitchHoldState "Parameter indicating whether the battery main switch is held due to an external request or not.";
CM_ BO_ 2147548634 "Basic Joystick Message 3";
CM_ SG_ 2147548634 Joystick3XAxisDetentPosStatus "Reports when the current joystick position is in the detent position for that axis of travel.";
CM_ SG_ 2147548634 Joystick3Button9PressedStatus "Reports when the joystick button has been pressed.";
CM_ SG_ 2147548634 Joystick3Button10PressedStatus "Reports when the joystick button has been pressed.";
CM_ SG_ 2147548634 Joystick3Button11PressedStatus "Reports when the joystick button has been pressed.";
CM_ SG_ 2147548634 Joystick3Button12PressedStatus "Reports when the joystick button has been pressed.";
CM_ SG_ 2147548634 Joystick3YAxisDetentPosStatus "Reports when the current joystick position is in the detent position for that axis of travel.";
CM_ SG_ 2147548634 Joystick3YAxisPos "The position of the joystick in the relative motion of travel from the neutral position.";
CM_ SG_ 2147548634 Joystick3YAxisNeutralPosStatus "Reports when the current joystick position is in the neutral position for that axis of travel.";
CM_ SG_ 2147548634 Joystick3XAxisPos "The position of the joystick in the relative motion of travel from the neutral position.";
CM_ SG_ 2147548634 Joystick3XAxisNeutralPosStatus "Reports when the current joystick position is in the neutral position for that axis of travel.";
CM_ SG_ 2147548634 Joystick3Button5PressedStatus "Reports when the joystick button has been pressed.";
CM_ SG_ 2147548634 Joystick3Button6PressedStatus "Reports when the joystick button has been pressed.";
CM_ SG_ 2147548634 Joystick3Button7PressedStatus "Reports when the joystick button has been pressed.";
CM_ SG_ 2147548634 Joystick3Button8PressedStatus "Reports when the joystick button has been pressed.";
CM_ SG_ 2147548634 Joystick3Button1PressedStatus "Reports when the joystick button has been pressed.";
CM_ SG_ 2147548634 Joystick3Button2PressedStatus "Reports when the joystick button has been pressed.";
CM_ SG_ 2147548634 Joystick3Button3PressedStatus "Reports when the joystick button has been pressed.";
CM_ SG_ 2147548634 Joystick3Button4PressedStatus "Reports when the joystick button has been pressed.";
CM_ BO_ 2147548632 "Basic Joystick Message 2";
CM_ SG_ 2147548632 Joystick2XAxisDetentPosStatus "Reports when the current joystick position is in the detent position for that axis of travel.";
CM_ SG_ 2147548632 Joystick2YAxisDetentPosStatus "Reports when the current joystick position is in the detent position for that axis of travel.";
CM_ SG_ 2147548632 Joystick2YAxisPos "The position of the joystick in the relative motion of travel from the neutral position.";
CM_ SG_ 2147548632 Joystick2YAxisNeutralPosStatus "Reports when the current joystick position is in the neutral position for that axis of travel.";
CM_ SG_ 2147548632 Joystick2XAxisPos "The position of the joystick in the relative motion of travel from the neutral position.";
CM_ SG_ 2147548632 Joystick2XAxisNeutralPosStatus "Reports when the current joystick position is in the neutral position for that axis of travel.";
CM_ SG_ 2147548632 Joystick2Button9PressedStatus "Reports when the joystick button has been pressed.";
CM_ SG_ 2147548632 Joystick2Button10PressedStatus "Reports when the joystick button has been pressed.";
CM_ SG_ 2147548632 Joystick2Button11PressedStatus "Reports when the joystick button has been pressed.";
CM_ SG_ 2147548632 Joystick2Button12PressedStatus "Reports when the joystick button has been pressed.";
CM_ SG_ 2147548632 Joystick2Button5PressedStatus "Reports when the joystick button has been pressed.";
CM_ SG_ 2147548632 Joystick2Button6PressedStatus "Reports when the joystick button has been pressed.";
CM_ SG_ 2147548632 Joystick2Button7PressedStatus "Reports when the joystick button has been pressed.";
CM_ SG_ 2147548632 Joystick2Button8PressedStatus "Reports when the joystick button has been pressed.";
CM_ SG_ 2147548632 Joystick2Button1PressedStatus "Reports when the joystick button has been pressed.";
CM_ SG_ 2147548632 Joystick2Button2PressedStatus "Reports when the joystick button has been pressed.";
CM_ SG_ 2147548632 Joystick2Button3PressedStatus "Reports when the joystick button has been pressed.";
CM_ SG_ 2147548632 Joystick2Button4PressedStatus "Reports when the joystick button has been pressed.";
BA_DEF_ SG_  "SigType" STRING ;
BA_DEF_ SG_  "SPN" INT 0 524287;
BA_DEF_ BO_  "J1939PGPrio" INT 0 7;
BA_DEF_ BO_  "SingleFrame" INT 0 1;
BA_DEF_ BO_  "J1939PGRepetitionCycle" INT 0 1000000;
BA_DEF_ BO_  "J1939PGRepetitionType" ENUM  "always","when active","on request";
BA_DEF_DEF_  "SigType" "";
BA_DEF_DEF_  "SPN" 0;
BA_DEF_DEF_  "J1939PGPrio" 6;
BA_DEF_DEF_  "SingleFrame" 1;
BA_DEF_DEF_  "J1939PGRepetitionCycle" 0;
BA_DEF_DEF_  "J1939PGRepetitionType" "on request";
BA_ "J1939PGRepetitionCycle" BO_ 2147548636 1000;
BA_ "J1939PGRepetitionType" BO_ 2147548636 0;
BA_ "J1939PGRepetitionCycle" BO_ 2147548828 1000;
BA_ "J1939PGRepetitionType" BO_ 2147548828 0;
BA_ "J1939PGRepetitionCycle" BO_ 2147548829 1000;
BA_ "J1939PGRepetitionType" BO_ 2147548829 0;
BA_ "J1939PGRepetitionCycle" BO_ 2147548830 1000;
BA_ "J1939PGRepetitionType" BO_ 2147548830 0;
BA_ "J1939PGPrio" BO_ 2147548790 4;
BA_ "J1939PGRepetitionCycle" BO_ 2147548790 100;
BA_ "J1939PGRepetitionType" BO_ 2147548790 0;
BA_ "J1939PGPrio" BO_ 2147548789 3;
BA_ "J1939PGRepetitionCycle" BO_ 2147548789 50;
BA_ "J1939PGRepetitionType" BO_ 2147548789 0;
BA_ "J1939PGPrio" BO_ 2147548785 3;
BA_ "J1939PGRepetitionCycle" BO_ 2147548785 50;
BA_ "J1939PGRepetitionType" BO_ 2147548785 0;
BA_ "J1939PGPrio" BO_ 2147548857 7;
BA_ "J1939PGPrio" BO_ 2147548788 3;
BA_ "J1939PGRepetitionCycle" BO_ 2147548788 50;
BA_ "J1939PGRepetitionType" BO_ 2147548788 0;
BA_ "J1939PGPrio" BO_ 2147545101 3;
BA_ "J1939PGRepetitionCycle" BO_ 2147545101 100;
BA_ "J1939PGRepetitionType" BO_ 2147545101 0;
BA_ "J1939PGPrio" BO_ 2147548787 3;
BA_ "J1939PGRepetitionCycle" BO_ 2147548787 50;
BA_ "J1939PGRepetitionType" BO_ 2147548787 0;
BA_ "J1939PGPrio" BO_ 2147548851 7;
BA_ "J1939PGRepetitionCycle" BO_ 2147548914 100;
BA_ "J1939PGRepetitionType" BO_ 2147548914 0;
BA_ "J1939PGPrio" BO_ 2147548639 7;
BA_ "J1939PGRepetitionCycle" BO_ 2147548639 500;
BA_ "J1939PGRepetitionType" BO_ 2147548639 0;
BA_ "J1939PGPrio" BO_ 2147548625 7;
BA_ "J1939PGRepetitionCycle" BO_ 2147548625 10000;
BA_ "J1939PGRepetitionType" BO_ 2147548625 0;
BA_ "J1939PGRepetitionCycle" BO_ 2147548763 100;
BA_ "J1939PGRepetitionType" BO_ 2147548763 0;
BA_ "J1939PGPrio" BO_ 2147545095 4;
BA_ "J1939PGRepetitionCycle" BO_ 2147545095 50;
BA_ "J1939PGRepetitionType" BO_ 2147545095 1;
BA_ "J1939PGPrio" BO_ 2147548817 7;
BA_ "J1939PGRepetitionCycle" BO_ 2147548817 1000;
BA_ "J1939PGRepetitionType" BO_ 2147548817 0;
BA_ "J1939PGRepetitionCycle" BO_ 2147548861 1000;
BA_ "J1939PGRepetitionType" BO_ 2147548861 0;
BA_ "J1939PGPrio" BO_ 2147545100 7;
BA_ "J1939PGRepetitionCycle" BO_ 2147545100 20;
BA_ "J1939PGRepetitionType" BO_ 2147545100 0;
BA_ "J1939PGRepetitionCycle" BO_ 2147548746 100;
BA_ "J1939PGRepetitionType" BO_ 2147548746 0;
BA_ "J1939PGPrio" BO_ 2147548843 7;
BA_ "J1939PGPrio" BO_ 2147548867 7;
BA_ "J1939PGPrio" BO_ 2147548869 7;
BA_ "J1939PGPrio" BO_ 2147548871 7;
BA_ "J1939PGRepetitionCycle" BO_ 2147545093 100;
BA_ "J1939PGRepetitionType" BO_ 2147545093 0;
BA_ "J1939PGPrio" BO_ 2147545090 3;
BA_ "J1939PGRepetitionCycle" BO_ 2147545090 10;
BA_ "J1939PGRepetitionType" BO_ 2147545090 0;
BA_ "J1939PGRepetitionCycle" BO_ 2147548777 1000;
BA_ "J1939PGRepetitionType" BO_ 2147548777 0;
BA_ "J1939PGRepetitionCycle" BO_ 2147548836 1000;
BA_ "J1939PGRepetitionType" BO_ 2147548836 0;
BA_ "J1939PGRepetitionCycle" BO_ 2147548910 1000;
BA_ "J1939PGRepetitionType" BO_ 2147548910 0;
BA_ "J1939PGRepetitionCycle" BO_ 2147548679 500;
BA_ "J1939PGRepetitionType" BO_ 2147548679 0;
BA_ "J1939PGRepetitionCycle" BO_ 2147545099 20;
BA_ "J1939PGRepetitionType" BO_ 2147545099 0;
BA_ "J1939PGPrio" BO_ 2147548866 7;
BA_ "J1939PGRepetitionCycle" BO_ 2147548866 1000;
BA_ "J1939PGRepetitionType" BO_ 2147548866 1;
BA_ "J1939PGRepetitionCycle" BO_ 2147545088 100;
BA_ "J1939PGRepetitionType" BO_ 2147545088 0;
BA_ "J1939PGPrio" BO_ 2147548831 7;
BA_ "J1939PGRepetitionCycle" BO_ 2147548831 1000;
BA_ "J1939PGRepetitionType" BO_ 2147548831 0;
BA_ "J1939PGRepetitionCycle" BO_ 2147548832 1000;
BA_ "J1939PGRepetitionType" BO_ 2147548832 0;
BA_ "J1939PGPrio" BO_ 2147548833 7;
BA_ "J1939PGRepetitionCycle" BO_ 2147548833 1000;
BA_ "J1939PGRepetitionType" BO_ 2147548833 0;
BA_ "J1939PGPrio" BO_ 2147548834 7;
BA_ "J1939PGRepetitionCycle" BO_ 2147548834 1000;
BA_ "J1939PGRepetitionType" BO_ 2147548834 0;
BA_ "J1939PGPrio" BO_ 2147548835 7;
BA_ "J1939PGRepetitionCycle" BO_ 2147548835 1000;
BA_ "J1939PGRepetitionType" BO_ 2147548835 0;
BA_ "J1939PGRepetitionCycle" BO_ 2147548644 500;
BA_ "J1939PGRepetitionType" BO_ 2147548644 0;
BA_ "J1939PGRepetitionCycle" BO_ 2147548643 250;
BA_ "J1939PGRepetitionType" BO_ 2147548643 0;
BA_ "J1939PGPrio" BO_ 2147548841 7;
BA_ "J1939PGPrio" BO_ 2147548635 3;
BA_ "J1939PGRepetitionCycle" BO_ 2147548635 100;
BA_ "J1939PGRepetitionType" BO_ 2147548635 0;
BA_ "J1939PGPrio" BO_ 2147548633 3;
BA_ "J1939PGRepetitionCycle" BO_ 2147548633 100;
BA_ "J1939PGRepetitionType" BO_ 2147548633 0;
BA_ "J1939PGPrio" BO_ 2147548631 3;
BA_ "J1939PGRepetitionCycle" BO_ 2147548631 100;
BA_ "J1939PGRepetitionType" BO_ 2147548631 0;
BA_ "J1939PGPrio" BO_ 2147548818 7;
BA_ "J1939PGRepetitionCycle" BO_ 2147548818 100;
BA_ "J1939PGRepetitionType" BO_ 2147548818 0;
BA_ "J1939PGPrio" BO_ 2147548849 7;
BA_ "J1939PGPrio" BO_ 2147545098 3;
BA_ "J1939PGRepetitionCycle" BO_ 2147545098 50;
BA_ "J1939PGRepetitionType" BO_ 2147545098 0;
BA_ "J1939PGRepetitionCycle" BO_ 2147548778 500;
BA_ "J1939PGRepetitionType" BO_ 2147548778 0;
BA_ "J1939PGRepetitionCycle" BO_ 2147548609 500;
BA_ "J1939PGRepetitionType" BO_ 2147548609 0;
BA_ "J1939PGRepetitionCycle" BO_ 2147548891 500;
BA_ "J1939PGRepetitionType" BO_ 2147548891 0;
BA_ "J1939PGRepetitionCycle" BO_ 2147548911 500;
BA_ "J1939PGRepetitionType" BO_ 2147548911 0;
BA_ "J1939PGPrio" BO_ 2147548819 7;
BA_ "J1939PGRepetitionCycle" BO_ 2147548819 100;
BA_ "J1939PGRepetitionType" BO_ 2147548819 0;
BA_ "J1939PGPrio" BO_ 2147548862 7;
BA_ "J1939PGRepetitionCycle" BO_ 2147548895 250;
BA_ "J1939PGRepetitionType" BO_ 2147548895 0;
BA_ "J1939PGPrio" BO_ 2147545091 3;
BA_ "J1939PGRepetitionCycle" BO_ 2147545091 50;
BA_ "J1939PGRepetitionType" BO_ 2147545091 0;
BA_ "J1939PGPrio" BO_ 2147545092 3;
BA_ "J1939PGRepetitionCycle" BO_ 2147548756 5000;
BA_ "J1939PGRepetitionType" BO_ 2147548756 0;
BA_ "J1939PGRepetitionCycle" BO_ 2147548612 100;
BA_ "J1939PGRepetitionType" BO_ 2147548612 0;
BA_ "J1939PGPrio" BO_ 2147548844 7;
BA_ "J1939PGRepetitionCycle" BO_ 2147548845 100;
BA_ "J1939PGRepetitionType" BO_ 2147548845 0;
BA_ "J1939PGRepetitionCycle" BO_ 2147548863 100;
BA_ "J1939PGRepetitionType" BO_ 2147548863 0;
BA_ "J1939PGRepetitionCycle" BO_ 2147545089 100;
BA_ "J1939PGRepetitionType" BO_ 2147545089 0;
BA_ "J1939PGRepetitionCycle" BO_ 2147545094 500;
BA_ "J1939PGRepetitionType" BO_ 2147545094 0;
BA_ "J1939PGRepetitionCycle" BO_ 2147548820 500;
BA_ "J1939PGRepetitionType" BO_ 2147548820 0;
BA_ "J1939PGRepetitionCycle" BO_ 2147548924 1000;
BA_ "J1939PGRepetitionType" BO_ 2147548924 0;
BA_ "J1939PGRepetitionCycle" BO_ 2147548750 100;
BA_ "J1939PGRepetitionType" BO_ 2147548750 0;
BA_ "J1939PGRepetitionCycle" BO_ 2147536640 5000;
BA_ "J1939PGRepetitionType" BO_ 2147536640 0;
BA_ "J1939PGPrio" BO_ 2147548800 7;
BA_ "J1939PGPrio" BO_ 2147548799 7;
BA_ "J1939PGPrio" BO_ 2147548798 7;
BA_ "J1939PGPrio" BO_ 2147548797 7;
BA_ "J1939PGPrio" BO_ 2147548796 7;
BA_ "J1939PGPrio" BO_ 2147548795 7;
BA_ "J1939PGPrio" BO_ 2147548617 7;
BA_ "J1939PGRepetitionCycle" BO_ 2147540992 1000;
BA_ "J1939PGRepetitionType" BO_ 2147540992 0;
BA_ "J1939PGRepetitionCycle" BO_ 2147548913 100;
BA_ "J1939PGRepetitionType" BO_ 2147548913 0;
BA_ "J1939PGPrio" BO_ 2147548860 7;
BA_ "J1939PGRepetitionCycle" BO_ 2147548641 1000;
BA_ "J1939PGRepetitionType" BO_ 2147548641 0;
BA_ "J1939PGRepetitionCycle" BO_ 2147548752 1000;
BA_ "J1939PGRepetitionType" BO_ 2147548752 0;
BA_ "J1939PGRepetitionCycle" BO_ 2147548774 1000;
BA_ "J1939PGRepetitionType" BO_ 2147548774 0;
BA_ "J1939PGPrio" BO_ 2147548634 3;
BA_ "J1939PGRepetitionCycle" BO_ 2147548634 100;
BA_ "J1939PGRepetitionType" BO_ 2147548634 0;
BA_ "J1939PGPrio" BO_ 2147548632 3;
BA_ "J1939PGRepetitionCycle" BO_ 2147548632 100;
BA_ "J1939PGRepetitionType" BO_ 2147548632 0;
BA_ "SigType" SG_ 2147548636 SlowVesselModeStatus "DISCRETE";
BA_ "SPN" SG_ 2147548636 SlowVesselModeStatus 2617;
BA_ "SigType" SG_ 2147548636 TrollingModeStatus "DISCRETE";
BA_ "SPN" SG_ 2147548636 TrollingModeStatus 2616;
BA_ "SigType" SG_ 2147548636 EngThrttlSynchrnztionModeStatus "DISCRETE";
BA_ "SPN" SG_ 2147548636 EngThrttlSynchrnztionModeStatus 2615;
BA_ "SigType" SG_ 2147548828 EngMainBearing11Temp "RANGE";
BA_ "SPN" SG_ 2147548828 EngMainBearing11Temp 1167;
BA_ "SigType" SG_ 2147548828 EngMainBearing10Temp "RANGE";
BA_ "SPN" SG_ 2147548828 EngMainBearing10Temp 1166;
BA_ "SigType" SG_ 2147548828 EngMainBearing9Temp "RANGE";
BA_ "SPN" SG_ 2147548828 EngMainBearing9Temp 1165;
BA_ "SigType" SG_ 2147548829 EngMainBearing8Temp "RANGE";
BA_ "SPN" SG_ 2147548829 EngMainBearing8Temp 1164;
BA_ "SigType" SG_ 2147548829 EngMainBearing7Temp "RANGE";
BA_ "SPN" SG_ 2147548829 EngMainBearing7Temp 1163;
BA_ "SigType" SG_ 2147548829 EngMainBearing6Temp "RANGE";
BA_ "SPN" SG_ 2147548829 EngMainBearing6Temp 1162;
BA_ "SigType" SG_ 2147548829 EngMainBearing5Temp "RANGE";
BA_ "SPN" SG_ 2147548829 EngMainBearing5Temp 1161;
BA_ "SigType" SG_ 2147548830 EngMainBearing4Temp "RANGE";
BA_ "SPN" SG_ 2147548830 EngMainBearing4Temp 1160;
BA_ "SigType" SG_ 2147548830 EngMainBearing3Temp "RANGE";
BA_ "SPN" SG_ 2147548830 EngMainBearing3Temp 1159;
BA_ "SigType" SG_ 2147548830 EngMainBearing2Temp "RANGE";
BA_ "SPN" SG_ 2147548830 EngMainBearing2Temp 1158;
BA_ "SigType" SG_ 2147548830 EngMainBearing1Temp "RANGE";
BA_ "SPN" SG_ 2147548830 EngMainBearing1Temp 1157;
BA_ "SigType" SG_ 2147548790 DisplayDeadbands "DISCRETE";
BA_ "SPN" SG_ 2147548790 DisplayDeadbands 2577;
BA_ "SigType" SG_ 2147548790 LEDPatternCtrl "DISCRETE";
BA_ "SPN" SG_ 2147548790 LEDPatternCtrl 2578;
BA_ "SigType" SG_ 2147548790 LEDDisplayDeadbandCtrl "DISCRETE";
BA_ "SPN" SG_ 2147548790 LEDDisplayDeadbandCtrl 1806;
BA_ "SigType" SG_ 2147548790 LEDDisplayModeCtrl "DISCRETE";
BA_ "SPN" SG_ 2147548790 LEDDisplayModeCtrl 1805;
BA_ "SigType" SG_ 2147548790 LEDDisplayData1 "RANGE";
BA_ "SPN" SG_ 2147548790 LEDDisplayData1 1573;
BA_ "SigType" SG_ 2147548789 AbsLaserStrikePosition "RANGE";
BA_ "SPN" SG_ 2147548789 AbsLaserStrikePosition 2794;
BA_ "SigType" SG_ 2147548789 LaserStrikeDataLatency "DISCRETE";
BA_ "SPN" SG_ 2147548789 LaserStrikeDataLatency 2793;
BA_ "SigType" SG_ 2147548789 LaserReceiverType "RANGE";
BA_ "SPN" SG_ 2147548789 LaserReceiverType 2576;
BA_ "SigType" SG_ 2147548789 LaserStrikeVerticalDeviation "RANGE";
BA_ "SPN" SG_ 2147548789 LaserStrikeVerticalDeviation 1574;
BA_ "SigType" SG_ 2147548785 LaserTracerInformation "RANGE";
BA_ "SPN" SG_ 2147548785 LaserTracerInformation 1583;
BA_ "SigType" SG_ 2147548785 LEDDisplayData2 "RANGE";
BA_ "SPN" SG_ 2147548785 LEDDisplayData2 1582;
BA_ "SigType" SG_ 2147548785 LaserTracerHorizontalDeviation "RANGE";
BA_ "SPN" SG_ 2147548785 LaserTracerHorizontalDeviation 1581;
BA_ "SigType" SG_ 2147548785 LaserTracerVerticalDistance "RANGE";
BA_ "SPN" SG_ 2147548785 LaserTracerVerticalDistance 1580;
BA_ "SigType" SG_ 2147548785 LaserTracerTargetDeviation "RANGE";
BA_ "SPN" SG_ 2147548785 LaserTracerTargetDeviation 1579;
BA_ "SigType" SG_ 2147548857 TripDriveFuelEconomy "RANGE";
BA_ "SPN" SG_ 2147548857 TripDriveFuelEconomy 1012;
BA_ "SigType" SG_ 2147548857 TripCruiseFuelUsed "RANGE";
BA_ "SPN" SG_ 2147548857 TripCruiseFuelUsed 1011;
BA_ "SigType" SG_ 2147548857 TripVehicleIdleFuelUsed "RANGE";
BA_ "SPN" SG_ 2147548857 TripVehicleIdleFuelUsed 1010;
BA_ "SigType" SG_ 2147548857 TripPTONonmovingFuelUsed "RANGE";
BA_ "SPN" SG_ 2147548857 TripPTONonmovingFuelUsed 1009;
BA_ "SigType" SG_ 2147548857 TripPTOMovingFuelUsed "RANGE";
BA_ "SPN" SG_ 2147548857 TripPTOMovingFuelUsed 1008;
BA_ "SigType" SG_ 2147548857 TripDriveFuelUsed "RANGE";
BA_ "SPN" SG_ 2147548857 TripDriveFuelUsed 1007;
BA_ "SigType" SG_ 2147548788 BldHeightSetPointHighResolution "RANGE";
BA_ "SPN" SG_ 2147548788 BldHeightSetPointHighResolution 1759;
BA_ "SigType" SG_ 2147548788 ModifySetPoint "RANGE";
BA_ "SPN" SG_ 2147548788 ModifySetPoint 1575;
BA_ "SigType" SG_ 2147545101 BladeAutoModeCmd "DISCRETE";
BA_ "SPN" SG_ 2147545101 BladeAutoModeCmd 3158;
BA_ "SigType" SG_ 2147545101 DesiredGradeOffsetSwitch "DISCRETE";
BA_ "SPN" SG_ 2147545101 DesiredGradeOffsetSwitch 3157;
BA_ "SigType" SG_ 2147545101 BladeCtrlModeSwitch "DISCRETE";
BA_ "SPN" SG_ 2147545101 BladeCtrlModeSwitch 3156;
BA_ "SigType" SG_ 2147548787 MastPos "RANGE";
BA_ "SPN" SG_ 2147548787 MastPos 1576;
BA_ "SigType" SG_ 2147548851 TripAverageFuelRate "RANGE";
BA_ "SPN" SG_ 2147548851 TripAverageFuelRate 1031;
BA_ "SigType" SG_ 2147548851 TotalEngPTOFuelUsed "RANGE";
BA_ "SPN" SG_ 2147548851 TotalEngPTOFuelUsed 1030;
BA_ "SigType" SG_ 2147548914 EngAverageFuelEconomy "RANGE";
BA_ "SPN" SG_ 2147548914 EngAverageFuelEconomy 185;
BA_ "SigType" SG_ 2147548914 EngInstantaneousFuelEconomy "RANGE";
BA_ "SPN" SG_ 2147548914 EngInstantaneousFuelEconomy 184;
BA_ "SigType" SG_ 2147548914 EngFuelRate "RANGE";
BA_ "SPN" SG_ 2147548914 EngFuelRate 183;
BA_ "SigType" SG_ 2147548914 EngThrottlePos "RANGE";
BA_ "SPN" SG_ 2147548914 EngThrottlePos 51;
BA_ "SigType" SG_ 2147548905 EngTotalFuelUsed "RANGE";
BA_ "SPN" SG_ 2147548905 EngTotalFuelUsed 250;
BA_ "SigType" SG_ 2147548905 EngTripFuel "RANGE";
BA_ "SPN" SG_ 2147548905 EngTripFuel 182;
BA_ "SigType" SG_ 2147548639 FrontWheelDriveActuatorStatus "DISCRETE";
BA_ "SPN" SG_ 2147548639 FrontWheelDriveActuatorStatus 2612;
BA_ "SigType" SG_ 2147548625 FMSstandardSWversionSupported "RANGE";
BA_ "SPN" SG_ 2147548625 FMSstandardSWversionSupported 2806;
BA_ "SigType" SG_ 2147548625 FMSstandardRqsSupported "DISCRETE";
BA_ "SPN" SG_ 2147548625 FMSstandardRqsSupported 2805;
BA_ "SigType" SG_ 2147548625 FMSstandardDiagnosticsSupported "DISCRETE";
BA_ "SPN" SG_ 2147548625 FMSstandardDiagnosticsSupported 2804;
BA_ "SigType" SG_ 2147548763 LnDprtureIndicationEnableStatus "DISCRETE";
BA_ "SPN" SG_ 2147548763 LnDprtureIndicationEnableStatus 1702;
BA_ "SigType" SG_ 2147548763 LaneTrackingStatusLeftSide "DISCRETE";
BA_ "SPN" SG_ 2147548763 LaneTrackingStatusLeftSide 1710;
BA_ "SigType" SG_ 2147548763 LaneTrackingStatusRightSide "DISCRETE";
BA_ "SPN" SG_ 2147548763 LaneTrackingStatusRightSide 1711;
BA_ "SigType" SG_ 2147545095 LaneDepartureImminentLeftSide "DISCRETE";
BA_ "SPN" SG_ 2147545095 LaneDepartureImminentLeftSide 1700;
BA_ "SigType" SG_ 2147545095 LaneDepartureImminentRightSide "DISCRETE";
BA_ "SPN" SG_ 2147545095 LaneDepartureImminentRightSide 1701;
BA_ "SigType" SG_ 2147548817 EngFuelLeakage2 "DISCRETE";
BA_ "SPN" SG_ 2147548817 EngFuelLeakage2 1240;
BA_ "SigType" SG_ 2147548817 EngFuelLeakage1 "DISCRETE";
BA_ "SPN" SG_ 2147548817 EngFuelLeakage1 1239;
BA_ "SigType" SG_ 2147548861 FanSpeed "RANGE";
BA_ "SPN" SG_ 2147548861 FanSpeed 1639;
BA_ "SigType" SG_ 2147548861 FanDriveState "DISCRETE";
BA_ "SPN" SG_ 2147548861 FanDriveState 977;
BA_ "SigType" SG_ 2147548861 EstPercentFanSpeed "RANGE";
BA_ "SPN" SG_ 2147548861 EstPercentFanSpeed 975;
BA_ "SigType" SG_ 2147548816 EngTorqueLimit6AxleInput "RANGE";
BA_ "SPN" SG_ 2147548816 EngTorqueLimit6AxleInput 1263;
BA_ "SigType" SG_ 2147548816 EngTorqueLimit5Switch "RANGE";
BA_ "SPN" SG_ 2147548816 EngTorqueLimit5Switch 1262;
BA_ "SigType" SG_ 2147548816 EngTorqueLimit4Trans "RANGE";
BA_ "SPN" SG_ 2147548816 EngTorqueLimit4Trans 1261;
BA_ "SigType" SG_ 2147548816 EngTorqueLimit3Trans "RANGE";
BA_ "SPN" SG_ 2147548816 EngTorqueLimit3Trans 1260;
BA_ "SigType" SG_ 2147548816 TransGearRatio3 "RANGE";
BA_ "SPN" SG_ 2147548816 TransGearRatio3 1259;
BA_ "SigType" SG_ 2147548816 EngTorqueLimit2Trans "RANGE";
BA_ "SPN" SG_ 2147548816 EngTorqueLimit2Trans 1258;
BA_ "SigType" SG_ 2147548816 TransGearRatio2 "RANGE";
BA_ "SPN" SG_ 2147548816 TransGearRatio2 1257;
BA_ "SigType" SG_ 2147548816 EngTorqueLimit1Trans "RANGE";
BA_ "SPN" SG_ 2147548816 EngTorqueLimit1Trans 1256;
BA_ "SigType" SG_ 2147548816 TransGearRatio1 "RANGE";
BA_ "SPN" SG_ 2147548816 TransGearRatio1 1255;
BA_ "SigType" SG_ 2147548816 EngTorqueLimitFeature "DISCRETE";
BA_ "SPN" SG_ 2147548816 EngTorqueLimitFeature 1632;
BA_ "SigType" SG_ 2147548816 TorqueLimitingFeatureStatus "DISCRETE";
BA_ "SPN" SG_ 2147548816 TorqueLimitingFeatureStatus 1254;
BA_ "SigType" SG_ 2147548816 CalibRecordDurationTime "RANGE";
BA_ "SPN" SG_ 2147548816 CalibRecordDurationTime 1253;
BA_ "SigType" SG_ 2147548816 CalibRecordStartYear "RANGE";
BA_ "SPN" SG_ 2147548816 CalibRecordStartYear 1252;
BA_ "SigType" SG_ 2147548816 CalibRecordStartDay "RANGE";
BA_ "SPN" SG_ 2147548816 CalibRecordStartDay 1251;
BA_ "SigType" SG_ 2147548816 CalibRecordStartMonth "RANGE";
BA_ "SPN" SG_ 2147548816 CalibRecordStartMonth 1250;
BA_ "SigType" SG_ 2147548816 EngPeakTorque2 "RANGE";
BA_ "SPN" SG_ 2147548816 EngPeakTorque2 1249;
BA_ "SigType" SG_ 2147548816 EngPeakTorque1 "RANGE";
BA_ "SPN" SG_ 2147548816 EngPeakTorque1 1248;
BA_ "SigType" SG_ 2147548816 EngPower "RANGE";
BA_ "SPN" SG_ 2147548816 EngPower 1247;
BA_ "SigType" SG_ 2147548816 NumberOfEngTorqueHistoryRecords "RANGE";
BA_ "SPN" SG_ 2147548816 NumberOfEngTorqueHistoryRecords 1246;
BA_ "SigType" SG_ 2147545100 TransTorqueConverterRatio "RANGE";
BA_ "SPN" SG_ 2147545100 TransTorqueConverterRatio 3030;
BA_ "SigType" SG_ 2147548746 TransRqedGearFeedback "RANGE";
BA_ "SPN" SG_ 2147548746 TransRqedGearFeedback 3289;
BA_ "SigType" SG_ 2147548746 TransMode1Indicator "DISCRETE";
BA_ "SPN" SG_ 2147548746 TransMode1Indicator 2536;
BA_ "SigType" SG_ 2147548746 TransMode2Indicator "DISCRETE";
BA_ "SPN" SG_ 2147548746 TransMode2Indicator 2537;
BA_ "SigType" SG_ 2147548746 TransMode3Indicator "DISCRETE";
BA_ "SPN" SG_ 2147548746 TransMode3Indicator 2538;
BA_ "SigType" SG_ 2147548746 TransMode4Indicator "DISCRETE";
BA_ "SPN" SG_ 2147548746 TransMode4Indicator 2539;
BA_ "SigType" SG_ 2147548746 TransShiftInhibitIndicator "DISCRETE";
BA_ "SPN" SG_ 2147548746 TransShiftInhibitIndicator 1851;
BA_ "SigType" SG_ 2147548746 TransEngCrankEnable "DISCRETE";
BA_ "SPN" SG_ 2147548746 TransEngCrankEnable 2900;
BA_ "SigType" SG_ 2147548746 ActiveShiftConsoleIndicator "DISCRETE";
BA_ "SPN" SG_ 2147548746 ActiveShiftConsoleIndicator 2945;
BA_ "SigType" SG_ 2147548746 TransReadyForBrakeRelease "DISCRETE";
BA_ "SPN" SG_ 2147548746 TransReadyForBrakeRelease 3086;
BA_ "SigType" SG_ 2147548746 TransRqedRangeDisplayFlashState "DISCRETE";
BA_ "SPN" SG_ 2147548746 TransRqedRangeDisplayFlashState 1849;
BA_ "SigType" SG_ 2147548746 TransRqedRangeDisplayBlankState "DISCRETE";
BA_ "SPN" SG_ 2147548746 TransRqedRangeDisplayBlankState 1850;
BA_ "SigType" SG_ 2147548843 ClutchLifeRemaining "RANGE";
BA_ "SPN" SG_ 2147548843 ClutchLifeRemaining 2983;
BA_ "SigType" SG_ 2147548843 LowestPossibleGear "RANGE";
BA_ "SPN" SG_ 2147548843 LowestPossibleGear 1114;
BA_ "SigType" SG_ 2147548843 HighestPossibleGear "RANGE";
BA_ "SPN" SG_ 2147548843 HighestPossibleGear 1115;
BA_ "SigType" SG_ 2147548843 RecommendedGear "RANGE";
BA_ "SPN" SG_ 2147548843 RecommendedGear 1113;
BA_ "SigType" SG_ 2147548867 TransForwardDirectionSwitch "DISCRETE";
BA_ "SPN" SG_ 2147548867 TransForwardDirectionSwitch 903;
BA_ "SigType" SG_ 2147548867 TransNeutralSwitch "DISCRETE";
BA_ "SPN" SG_ 2147548867 TransNeutralSwitch 604;
BA_ "SigType" SG_ 2147548867 TransReverseDirectionSwitch "DISCRETE";
BA_ "SPN" SG_ 2147548867 TransReverseDirectionSwitch 767;
BA_ "SigType" SG_ 2147548867 TransLowRangeSenseSwitch "DISCRETE";
BA_ "SPN" SG_ 2147548867 TransLowRangeSenseSwitch 779;
BA_ "SigType" SG_ 2147548867 TransHighRangeSenseSwitch "DISCRETE";
BA_ "SPN" SG_ 2147548867 TransHighRangeSenseSwitch 778;
BA_ "SigType" SG_ 2147548869 TransSynchronizerBrakeValue "RANGE";
BA_ "SPN" SG_ 2147548869 TransSynchronizerBrakeValue 54;
BA_ "SigType" SG_ 2147548869 TransSynchronizerClutchValue "RANGE";
BA_ "SPN" SG_ 2147548869 TransSynchronizerClutchValue 53;
BA_ "SigType" SG_ 2147548871 TransInertiaBrakeActuator "DISCRETE";
BA_ "SPN" SG_ 2147548871 TransInertiaBrakeActuator 787;
BA_ "SigType" SG_ 2147548871 TransDefuelActuator "DISCRETE";
BA_ "SPN" SG_ 2147548871 TransDefuelActuator 786;
BA_ "SigType" SG_ 2147548871 TransLockupClutchActuator "DISCRETE";
BA_ "SPN" SG_ 2147548871 TransLockupClutchActuator 740;
BA_ "SigType" SG_ 2147548871 TransClutchActuator "DISCRETE";
BA_ "SPN" SG_ 2147548871 TransClutchActuator 788;
BA_ "SigType" SG_ 2147548871 TransSplitterIndirectActuator "DISCRETE";
BA_ "SPN" SG_ 2147548871 TransSplitterIndirectActuator 771;
BA_ "SigType" SG_ 2147548871 TransSplitterDirectActuator "DISCRETE";
BA_ "SPN" SG_ 2147548871 TransSplitterDirectActuator 770;
BA_ "SigType" SG_ 2147548871 TransRangeLowActuator "DISCRETE";
BA_ "SPN" SG_ 2147548871 TransRangeLowActuator 769;
BA_ "SigType" SG_ 2147548871 TransRangeHighActuator "DISCRETE";
BA_ "SPN" SG_ 2147548871 TransRangeHighActuator 768;
BA_ "SigType" SG_ 2147548871 TransShiftFingerGearActuator2 "DISCRETE";
BA_ "SPN" SG_ 2147548871 TransShiftFingerGearActuator2 784;
BA_ "SigType" SG_ 2147548871 TransShiftFingerRailActuator2 "DISCRETE";
BA_ "SPN" SG_ 2147548871 TransShiftFingerRailActuator2 783;
BA_ "SigType" SG_ 2147548871 TransShiftFingerGearActuator1 "DISCRETE";
BA_ "SPN" SG_ 2147548871 TransShiftFingerGearActuator1 773;
BA_ "SigType" SG_ 2147548871 TransShiftFingerRailActuator1 "DISCRETE";
BA_ "SPN" SG_ 2147548871 TransShiftFingerRailActuator1 772;
BA_ "SigType" SG_ 2147548871 TrnsShftFngrCenterRailIndicator "DISCRETE";
BA_ "SPN" SG_ 2147548871 TrnsShftFngrCenterRailIndicator 782;
BA_ "SigType" SG_ 2147548871 TrnsShftFngrEngagementIndicator "DISCRETE";
BA_ "SPN" SG_ 2147548871 TrnsShftFngrEngagementIndicator 781;
BA_ "SigType" SG_ 2147548871 TrnsShiftFingerNeutralIndicator "DISCRETE";
BA_ "SPN" SG_ 2147548871 TrnsShiftFingerNeutralIndicator 780;
BA_ "SigType" SG_ 2147548871 TransShiftFingerRailPos "RANGE";
BA_ "SPN" SG_ 2147548871 TransShiftFingerRailPos 60;
BA_ "SigType" SG_ 2147548871 TransShiftFingerGearPos "RANGE";
BA_ "SPN" SG_ 2147548871 TransShiftFingerGearPos 59;
BA_ "SigType" SG_ 2147545093 TransCurrentRange "RANGE";
BA_ "SPN" SG_ 2147545093 TransCurrentRange 163;
BA_ "SigType" SG_ 2147545093 TransRqedRange "RANGE";
BA_ "SPN" SG_ 2147545093 TransRqedRange 162;
BA_ "SigType" SG_ 2147545093 TransCurrentGear "RANGE";
BA_ "SPN" SG_ 2147545093 TransCurrentGear 523;
BA_ "SigType" SG_ 2147545093 TransActualGearRatio "RANGE";
BA_ "SPN" SG_ 2147545093 TransActualGearRatio 526;
BA_ "SigType" SG_ 2147545093 TransSelectedGear "RANGE";
BA_ "SPN" SG_ 2147545093 TransSelectedGear 524;
BA_ "SigType" SG_ 2147545090 SrcAddrssOfCtrllngDvcFrTrnsCtrl "RANGE";
BA_ "SPN" SG_ 2147545090 SrcAddrssOfCtrllngDvcFrTrnsCtrl 1482;
BA_ "SigType" SG_ 2147545090 TransInputShaftSpeed "RANGE";
BA_ "SPN" SG_ 2147545090 TransInputShaftSpeed 161;
BA_ "SigType" SG_ 2147545090 ProgressiveShiftDisable "DISCRETE";
BA_ "SPN" SG_ 2147545090 ProgressiveShiftDisable 607;
BA_ "SigType" SG_ 2147545090 EngMomentaryOverspeedEnable "DISCRETE";
BA_ "SPN" SG_ 2147545090 EngMomentaryOverspeedEnable 606;
BA_ "SigType" SG_ 2147545090 PercentClutchSlip "RANGE";
BA_ "SPN" SG_ 2147545090 PercentClutchSlip 522;
BA_ "SigType" SG_ 2147545090 TransOutputShaftSpeed "RANGE";
BA_ "SPN" SG_ 2147545090 TransOutputShaftSpeed 191;
BA_ "SigType" SG_ 2147545090 TransShiftInProcess "DISCRETE";
BA_ "SPN" SG_ 2147545090 TransShiftInProcess 574;
BA_ "SigType" SG_ 2147545090 TorqueConverterLockupEngaged "DISCRETE";
BA_ "SPN" SG_ 2147545090 TorqueConverterLockupEngaged 573;
BA_ "SigType" SG_ 2147545090 TransDrivelineEngaged "DISCRETE";
BA_ "SPN" SG_ 2147545090 TransDrivelineEngaged 560;
BA_ "SigType" SG_ 2147548777 EngCoolantTempHiRes "RANGE";
BA_ "SPN" SG_ 2147548777 EngCoolantTempHiRes 1637;
BA_ "SigType" SG_ 2147548777 EngIntkVlvActationSystemOilTemp "RANGE";
BA_ "SPN" SG_ 2147548777 EngIntkVlvActationSystemOilTemp 2986;
BA_ "SigType" SG_ 2147548777 EngIntakeManifold1AirTemp "RANGE";
BA_ "SPN" SG_ 2147548777 EngIntakeManifold1AirTemp 1636;
BA_ "SigType" SG_ 2147548836 EngExhaustGasRecirculationTemp "RANGE";
BA_ "SPN" SG_ 2147548836 EngExhaustGasRecirculationTemp 412;
BA_ "SigType" SG_ 2147548836 EngExhstGsRcirculationDiffPress "RANGE";
BA_ "SPN" SG_ 2147548836 EngExhstGsRcirculationDiffPress 411;
BA_ "SigType" SG_ 2147548836 EngECUTemp "RANGE";
BA_ "SPN" SG_ 2147548836 EngECUTemp 1136;
BA_ "SigType" SG_ 2147548836 EngOilTemp2 "RANGE";
BA_ "SPN" SG_ 2147548836 EngOilTemp2 1135;
BA_ "SigType" SG_ 2147548910 EngIntercoolerThermostatOpening "RANGE";
BA_ "SPN" SG_ 2147548910 EngIntercoolerThermostatOpening 1134;
BA_ "SigType" SG_ 2147548910 EngIntercoolerTemp "RANGE";
BA_ "SPN" SG_ 2147548910 EngIntercoolerTemp 52;
BA_ "SigType" SG_ 2147548910 EngTurboOilTemp "RANGE";
BA_ "SPN" SG_ 2147548910 EngTurboOilTemp 176;
BA_ "SigType" SG_ 2147548910 EngOilTemp1 "RANGE";
BA_ "SPN" SG_ 2147548910 EngOilTemp1 175;
BA_ "SigType" SG_ 2147548910 EngFuelTemp "RANGE";
BA_ "SPN" SG_ 2147548910 EngFuelTemp 174;
BA_ "SigType" SG_ 2147548910 EngCoolantTemp "RANGE";
BA_ "SPN" SG_ 2147548910 EngCoolantTemp 110;
BA_ "SigType" SG_ 2147548679 EngExhstExhstGsTempLeftManifold "RANGE";
BA_ "SPN" SG_ 2147548679 EngExhstExhstGsTempLeftManifold 2434;
BA_ "SigType" SG_ 2147548679 EngExhstExhstGsTmpRightManifold "RANGE";
BA_ "SPN" SG_ 2147548679 EngExhstExhstGsTmpRightManifold 2433;
BA_ "SigType" SG_ 2147545099 SterableLiftAxleLoweringInhibit "DISCRETE";
BA_ "SPN" SG_ 2147545099 SterableLiftAxleLoweringInhibit 2922;
BA_ "SigType" SG_ 2147545099 AxleLocation "RANGE";
BA_ "SPN" SG_ 2147545099 AxleLocation 2928;
BA_ "SigType" SG_ 2147545099 TypeOfSteerTrans "DISCRETE";
BA_ "SPN" SG_ 2147545099 TypeOfSteerTrans 2926;
BA_ "SigType" SG_ 2147545099 TypeOfSteerForces "DISCRETE";
BA_ "SPN" SG_ 2147545099 TypeOfSteerForces 2925;
BA_ "SigType" SG_ 2147545099 SteerType "DISCRETE";
BA_ "SPN" SG_ 2147545099 SteerType 2924;
BA_ "SigType" SG_ 2147545099 StatusOfSteerAxle "DISCRETE";
BA_ "SPN" SG_ 2147545099 StatusOfSteerAxle 2923;
BA_ "SigType" SG_ 2147545099 ActualInnerWheelSteerAngle "RANGE";
BA_ "SPN" SG_ 2147545099 ActualInnerWheelSteerAngle 2927;
BA_ "SigType" SG_ 2147548866 TransOutputRetarder "DISCRETE";
BA_ "SPN" SG_ 2147548866 TransOutputRetarder 748;
BA_ "SigType" SG_ 2147545088 RetarderSelectionNonEng "RANGE";
BA_ "SPN" SG_ 2147545088 RetarderSelectionNonEng 1716;
BA_ "SigType" SG_ 2147545088 ActlMxAvlblRtarderPercentTorque "RANGE";
BA_ "SPN" SG_ 2147545088 ActlMxAvlblRtarderPercentTorque 1717;
BA_ "SigType" SG_ 2147545088 DrvrsDmandRetarderPercentTorque "RANGE";
BA_ "SPN" SG_ 2147545088 DrvrsDmandRetarderPercentTorque 1715;
BA_ "SigType" SG_ 2147545088 SrcAddrssOfCtrllngDvcFrRtrdrCtrl "RANGE";
BA_ "SPN" SG_ 2147545088 SrcAddrssOfCtrllngDvcFrRtrdrCtrl 1480;
BA_ "SigType" SG_ 2147545088 RetarderRqingBrakeLight "DISCRETE";
BA_ "SPN" SG_ 2147545088 RetarderRqingBrakeLight 1667;
BA_ "SigType" SG_ 2147545088 EngCoolantLoadIncrease "DISCRETE";
BA_ "SPN" SG_ 2147545088 EngCoolantLoadIncrease 1082;
BA_ "SigType" SG_ 2147545088 IntendedRetarderPercentTorque "RANGE";
BA_ "SPN" SG_ 2147545088 IntendedRetarderPercentTorque 1085;
BA_ "SigType" SG_ 2147545088 ActualRetarderPercentTorque "RANGE";
BA_ "SPN" SG_ 2147545088 ActualRetarderPercentTorque 520;
BA_ "SigType" SG_ 2147545088 RetarderEnableShiftAssistSwitch "DISCRETE";
BA_ "SPN" SG_ 2147545088 RetarderEnableShiftAssistSwitch 572;
BA_ "SigType" SG_ 2147545088 RetarderEnableBrakeAssistSwitch "DISCRETE";
BA_ "SPN" SG_ 2147545088 RetarderEnableBrakeAssistSwitch 571;
BA_ "SigType" SG_ 2147545088 RetarderTorqueMode "DISCRETE";
BA_ "SPN" SG_ 2147545088 RetarderTorqueMode 900;
BA_ "SigType" SG_ 2147548831 EngExhaustGasPort20Temp "RANGE";
BA_ "SPN" SG_ 2147548831 EngExhaustGasPort20Temp 1156;
BA_ "SigType" SG_ 2147548831 EngExhaustGasPort19Temp "RANGE";
BA_ "SPN" SG_ 2147548831 EngExhaustGasPort19Temp 1155;
BA_ "SigType" SG_ 2147548831 EngExhaustGasPort18Temp "RANGE";
BA_ "SPN" SG_ 2147548831 EngExhaustGasPort18Temp 1154;
BA_ "SigType" SG_ 2147548831 EngExhaustGasPort17Temp "RANGE";
BA_ "SPN" SG_ 2147548831 EngExhaustGasPort17Temp 1153;
BA_ "SigType" SG_ 2147548832 EngExhaustGasPort16Temp "RANGE";
BA_ "SPN" SG_ 2147548832 EngExhaustGasPort16Temp 1152;
BA_ "SigType" SG_ 2147548832 EngExhaustGasPort15Temp "RANGE";
BA_ "SPN" SG_ 2147548832 EngExhaustGasPort15Temp 1151;
BA_ "SigType" SG_ 2147548832 EngExhaustGasPort14Temp "RANGE";
BA_ "SPN" SG_ 2147548832 EngExhaustGasPort14Temp 1150;
BA_ "SigType" SG_ 2147548832 EngExhaustGasPort13Temp "RANGE";
BA_ "SPN" SG_ 2147548832 EngExhaustGasPort13Temp 1149;
BA_ "SigType" SG_ 2147548833 EngExhaustGasPort12Temp "RANGE";
BA_ "SPN" SG_ 2147548833 EngExhaustGasPort12Temp 1148;
BA_ "SigType" SG_ 2147548833 EngExhaustGasPort11Temp "RANGE";
BA_ "SPN" SG_ 2147548833 EngExhaustGasPort11Temp 1147;
BA_ "SigType" SG_ 2147548833 EngExhaustGasPort10Temp "RANGE";
BA_ "SPN" SG_ 2147548833 EngExhaustGasPort10Temp 1146;
BA_ "SigType" SG_ 2147548833 EngExhaustGasPort9Temp "RANGE";
BA_ "SPN" SG_ 2147548833 EngExhaustGasPort9Temp 1145;
BA_ "SigType" SG_ 2147548834 EngExhaustGasPort8Temp "RANGE";
BA_ "SPN" SG_ 2147548834 EngExhaustGasPort8Temp 1144;
BA_ "SigType" SG_ 2147548834 EngExhaustGasPort7Temp "RANGE";
BA_ "SPN" SG_ 2147548834 EngExhaustGasPort7Temp 1143;
BA_ "SigType" SG_ 2147548834 EngExhaustGasPort6Temp "RANGE";
BA_ "SPN" SG_ 2147548834 EngExhaustGasPort6Temp 1142;
BA_ "SigType" SG_ 2147548834 EngExhaustGasPort5Temp "RANGE";
BA_ "SPN" SG_ 2147548834 EngExhaustGasPort5Temp 1141;
BA_ "SigType" SG_ 2147548835 EngExhaustGasPort4Temp "RANGE";
BA_ "SPN" SG_ 2147548835 EngExhaustGasPort4Temp 1140;
BA_ "SigType" SG_ 2147548835 EngExhaustGasPort3Temp "RANGE";
BA_ "SPN" SG_ 2147548835 EngExhaustGasPort3Temp 1139;
BA_ "SigType" SG_ 2147548835 EngExhaustGasPort2Temp "RANGE";
BA_ "SPN" SG_ 2147548835 EngExhaustGasPort2Temp 1138;
BA_ "SigType" SG_ 2147548835 EngExhaustGasPort1Temp "RANGE";
BA_ "SPN" SG_ 2147548835 EngExhaustGasPort1Temp 1137;
BA_ "SigType" SG_ 2147548644 PayloadPercentage "RANGE";
BA_ "SPN" SG_ 2147548644 PayloadPercentage 2600;
BA_ "SigType" SG_ 2147548626 DataMemoryUsage "RANGE";
BA_ "SPN" SG_ 2147548626 DataMemoryUsage 2802;
BA_ "SigType" SG_ 2147548626 KeepAliveBatteryConsumption "RANGE";
BA_ "SPN" SG_ 2147548626 KeepAliveBatteryConsumption 2803;
BA_ "SigType" SG_ 2147548643 TravelVelocityCtrlPos "RANGE";
BA_ "SPN" SG_ 2147548643 TravelVelocityCtrlPos 2601;
BA_ "SigType" SG_ 2147548841 EngExhstGsOxygnSnsrClsdLpOprton "DISCRETE";
BA_ "SPN" SG_ 2147548841 EngExhstGsOxygnSnsrClsdLpOprton 1696;
BA_ "SigType" SG_ 2147548841 EngExhstGsOxygnSnsrFlngCrrction "RANGE";
BA_ "SPN" SG_ 2147548841 EngExhstGsOxygnSnsrFlngCrrction 1695;
BA_ "SigType" SG_ 2147548841 EngActualExhaustOxygen "RANGE";
BA_ "SPN" SG_ 2147548841 EngActualExhaustOxygen 1119;
BA_ "SigType" SG_ 2147548841 EngDesiredExhaustOxygen "RANGE";
BA_ "SPN" SG_ 2147548841 EngDesiredExhaustOxygen 1118;
BA_ "SigType" SG_ 2147548841 EngDesiredRatedExhaustOxygen "RANGE";
BA_ "SPN" SG_ 2147548841 EngDesiredRatedExhaustOxygen 1117;
BA_ "SigType" SG_ 2147548635 Jystck3GripXAxisDetentPosStatus "DISCRETE";
BA_ "SPN" SG_ 2147548635 Jystck3GripXAxisDetentPosStatus 2756;
BA_ "SigType" SG_ 2147548635 Jystck3GripYAxisDetentPosStatus "DISCRETE";
BA_ "SPN" SG_ 2147548635 Jystck3GripYAxisDetentPosStatus 2757;
BA_ "SigType" SG_ 2147548635 Jystck3ThetaAxisDetentPosStatus "DISCRETE";
BA_ "SPN" SG_ 2147548635 Jystck3ThetaAxisDetentPosStatus 2758;
BA_ "SigType" SG_ 2147548635 Joystick3ThetaAxisPos "RANGE";
BA_ "SPN" SG_ 2147548635 Joystick3ThetaAxisPos 2738;
BA_ "SigType" SG_ 2147548635 Jystck3ThtAxsClckwsPstvPsStatus "DISCRETE";
BA_ "SPN" SG_ 2147548635 Jystck3ThtAxsClckwsPstvPsStatus 2743;
BA_ "SigType" SG_ 2147548635 Jystck3ThtAxsCntrClckwsNgtvPsStt "DISCRETE";
BA_ "SPN" SG_ 2147548635 Jystck3ThtAxsCntrClckwsNgtvPsStt 2748;
BA_ "SigType" SG_ 2147548635 Jystck3ThtaAxisNeutralPosStatus "DISCRETE";
BA_ "SPN" SG_ 2147548635 Jystck3ThtaAxisNeutralPosStatus 2753;
BA_ "SigType" SG_ 2147548635 Joystick3GripYAxisPos "RANGE";
BA_ "SPN" SG_ 2147548635 Joystick3GripYAxisPos 2737;
BA_ "SigType" SG_ 2147548635 Jystck3GrpYAxsLvrFrwrdPstvPsStts "DISCRETE";
BA_ "SPN" SG_ 2147548635 Jystck3GrpYAxsLvrFrwrdPstvPsStts 2742;
BA_ "SigType" SG_ 2147548635 Jystck3GrpYAxsLvrBckNgtvPsSttus "DISCRETE";
BA_ "SPN" SG_ 2147548635 Jystck3GrpYAxsLvrBckNgtvPsSttus 2747;
BA_ "SigType" SG_ 2147548635 Jystck3GrpYAxisNeutralPosStatus "DISCRETE";
BA_ "SPN" SG_ 2147548635 Jystck3GrpYAxisNeutralPosStatus 2752;
BA_ "SigType" SG_ 2147548635 Joystick3GripXAxisPos "RANGE";
BA_ "SPN" SG_ 2147548635 Joystick3GripXAxisPos 2736;
BA_ "SigType" SG_ 2147548635 Jystck3GrpXAxsLvrRghtPstvPsStts "DISCRETE";
BA_ "SPN" SG_ 2147548635 Jystck3GrpXAxsLvrRghtPstvPsStts 2741;
BA_ "SigType" SG_ 2147548635 Jystck3GrpXAxsLvrLftNgtvPsSttus "DISCRETE";
BA_ "SPN" SG_ 2147548635 Jystck3GrpXAxsLvrLftNgtvPsSttus 2746;
BA_ "SigType" SG_ 2147548635 Jystck3GrpXAxisNeutralPosStatus "DISCRETE";
BA_ "SPN" SG_ 2147548635 Jystck3GrpXAxisNeutralPosStatus 2751;
BA_ "SigType" SG_ 2147548633 Jystck2GripXAxisDetentPosStatus "DISCRETE";
BA_ "SPN" SG_ 2147548633 Jystck2GripXAxisDetentPosStatus 2719;
BA_ "SigType" SG_ 2147548633 Jystck2GripYAxisDetentPosStatus "DISCRETE";
BA_ "SPN" SG_ 2147548633 Jystck2GripYAxisDetentPosStatus 2720;
BA_ "SigType" SG_ 2147548633 Jystck2ThetaAxisDetentPosStatus "DISCRETE";
BA_ "SPN" SG_ 2147548633 Jystck2ThetaAxisDetentPosStatus 2721;
BA_ "SigType" SG_ 2147548633 Joystick2ThetaAxisPos "RANGE";
BA_ "SPN" SG_ 2147548633 Joystick2ThetaAxisPos 2701;
BA_ "SigType" SG_ 2147548633 Jystck2ThtAxsClckwsPstvPsStatus "DISCRETE";
BA_ "SPN" SG_ 2147548633 Jystck2ThtAxsClckwsPstvPsStatus 2706;
BA_ "SigType" SG_ 2147548633 Jystck2ThtAxsCntrClckwsNgtvPsStt "DISCRETE";
BA_ "SPN" SG_ 2147548633 Jystck2ThtAxsCntrClckwsNgtvPsStt 2711;
BA_ "SigType" SG_ 2147548633 Jystck2ThtaAxisNeutralPosStatus "DISCRETE";
BA_ "SPN" SG_ 2147548633 Jystck2ThtaAxisNeutralPosStatus 2716;
BA_ "SigType" SG_ 2147548633 Joystick2GripYAxisPos "RANGE";
BA_ "SPN" SG_ 2147548633 Joystick2GripYAxisPos 2700;
BA_ "SigType" SG_ 2147548633 Jystck2GrpYAxsLvrFrwrdPstvPsStts "DISCRETE";
BA_ "SPN" SG_ 2147548633 Jystck2GrpYAxsLvrFrwrdPstvPsStts 2705;
BA_ "SigType" SG_ 2147548633 Jystck2GrpYAxsLvrBckNgtvPsSttus "DISCRETE";
BA_ "SPN" SG_ 2147548633 Jystck2GrpYAxsLvrBckNgtvPsSttus 2710;
BA_ "SigType" SG_ 2147548633 Jystck2GrpYAxisNeutralPosStatus "DISCRETE";
BA_ "SPN" SG_ 2147548633 Jystck2GrpYAxisNeutralPosStatus 2715;
BA_ "SigType" SG_ 2147548633 Joystick2GripXAxisPos "RANGE";
BA_ "SPN" SG_ 2147548633 Joystick2GripXAxisPos 2699;
BA_ "SigType" SG_ 2147548633 Jystck2GrpXAxsLvrRghtPstvPsStts "DISCRETE";
BA_ "SPN" SG_ 2147548633 Jystck2GrpXAxsLvrRghtPstvPsStts 2704;
BA_ "SigType" SG_ 2147548633 Jystck2GrpXAxsLvrLftNgtvPsSttus "DISCRETE";
BA_ "SPN" SG_ 2147548633 Jystck2GrpXAxsLvrLftNgtvPsSttus 2709;
BA_ "SigType" SG_ 2147548633 Jystck2GrpXAxisNeutralPosStatus "DISCRETE";
BA_ "SPN" SG_ 2147548633 Jystck2GrpXAxisNeutralPosStatus 2714;
BA_ "SigType" SG_ 2147548631 Jystck1GripXAxisDetentPosStatus "DISCRETE";
BA_ "SPN" SG_ 2147548631 Jystck1GripXAxisDetentPosStatus 2682;
BA_ "SigType" SG_ 2147548631 Jystck1GripYAxisDetentPosStatus "DISCRETE";
BA_ "SPN" SG_ 2147548631 Jystck1GripYAxisDetentPosStatus 2683;
BA_ "SigType" SG_ 2147548631 Jystck1ThetaAxisDetentPosStatus "DISCRETE";
BA_ "SPN" SG_ 2147548631 Jystck1ThetaAxisDetentPosStatus 2684;
BA_ "SigType" SG_ 2147548631 Joystick1ThetaAxisPos "RANGE";
BA_ "SPN" SG_ 2147548631 Joystick1ThetaAxisPos 2664;
BA_ "SigType" SG_ 2147548631 Jystck1ThtAxsClckwsPstvPsStatus "DISCRETE";
BA_ "SPN" SG_ 2147548631 Jystck1ThtAxsClckwsPstvPsStatus 2669;
BA_ "SigType" SG_ 2147548631 Jystck1ThtAxsCntrClckwsNgtvPsStt "DISCRETE";
BA_ "SPN" SG_ 2147548631 Jystck1ThtAxsCntrClckwsNgtvPsStt 2674;
BA_ "SigType" SG_ 2147548631 Jystck1ThtaAxisNeutralPosStatus "DISCRETE";
BA_ "SPN" SG_ 2147548631 Jystck1ThtaAxisNeutralPosStatus 2679;
BA_ "SigType" SG_ 2147548631 Joystick1GripYAxisPos "RANGE";
BA_ "SPN" SG_ 2147548631 Joystick1GripYAxisPos 2663;
BA_ "SigType" SG_ 2147548631 Jystck1GrpYAxsLvrFrwrdPstvPsStts "DISCRETE";
BA_ "SPN" SG_ 2147548631 Jystck1GrpYAxsLvrFrwrdPstvPsStts 2668;
BA_ "SigType" SG_ 2147548631 Jystck1GrpYAxsLvrBckNgtvPsSttus "DISCRETE";
BA_ "SPN" SG_ 2147548631 Jystck1GrpYAxsLvrBckNgtvPsSttus 2673;
BA_ "SigType" SG_ 2147548631 Jystck1GrpYAxisNeutralPosStatus "DISCRETE";
BA_ "SPN" SG_ 2147548631 Jystck1GrpYAxisNeutralPosStatus 2678;
BA_ "SigType" SG_ 2147548631 Joystick1GripXAxisPos "RANGE";
BA_ "SPN" SG_ 2147548631 Joystick1GripXAxisPos 2662;
BA_ "SigType" SG_ 2147548631 Jystck1GrpXAxsLvrRghtPstvPsStts "DISCRETE";
BA_ "SPN" SG_ 2147548631 Jystck1GrpXAxsLvrRghtPstvPsStts 2667;
BA_ "SigType" SG_ 2147548631 Jystck1GrpXAxsLvrLftNgtvPsSttus "DISCRETE";
BA_ "SPN" SG_ 2147548631 Jystck1GrpXAxsLvrLftNgtvPsSttus 2672;
BA_ "SigType" SG_ 2147548631 Jystck1GrpXAxisNeutralPosStatus "DISCRETE";
BA_ "SPN" SG_ 2147548631 Jystck1GrpXAxisNeutralPosStatus 2677;
BA_ "SigType" SG_ 2147548818 EngFuelRackPos "RANGE";
BA_ "SPN" SG_ 2147548818 EngFuelRackPos 1210;
BA_ "SigType" SG_ 2147548818 InstantaneousEstBrakePower "RANGE";
BA_ "SPN" SG_ 2147548818 InstantaneousEstBrakePower 1242;
BA_ "SigType" SG_ 2147548818 EngMassFlow "RANGE";
BA_ "SPN" SG_ 2147548818 EngMassFlow 1241;
BA_ "SigType" SG_ 2147548818 EngExhaustGasPress "RANGE";
BA_ "SPN" SG_ 2147548818 EngExhaustGasPress 1209;
BA_ "SigType" SG_ 2147548818 EngPrefilterOilPress "RANGE";
BA_ "SPN" SG_ 2147548818 EngPrefilterOilPress 1208;
BA_ "SigType" SG_ 2147548849 TotalECURunTime "RANGE";
BA_ "SPN" SG_ 2147548849 TotalECURunTime 1033;
BA_ "SigType" SG_ 2147548849 TotalECUDistance "RANGE";
BA_ "SPN" SG_ 2147548849 TotalECUDistance 1032;
BA_ "SigType" SG_ 2147545098 EngInletAirMassFlowRate "RANGE";
BA_ "SPN" SG_ 2147545098 EngInletAirMassFlowRate 132;
BA_ "SigType" SG_ 2147545098 EngExhstGsRcrcltionMassFlowRate "RANGE";
BA_ "SPN" SG_ 2147545098 EngExhstGsRcrcltionMassFlowRate 2659;
BA_ "SigType" SG_ 2147548778 EngFuelFilterSucSideDiffPress "RANGE";
BA_ "SPN" SG_ 2147548778 EngFuelFilterSucSideDiffPress 1382;
BA_ "SigType" SG_ 2147548778 EngFuelSupplyPumpInletPress "RANGE";
BA_ "SPN" SG_ 2147548778 EngFuelSupplyPumpInletPress 1381;
BA_ "SigType" SG_ 2147548778 EngOilLevelRemoteReservoir "RANGE";
BA_ "SPN" SG_ 2147548778 EngOilLevelRemoteReservoir 1380;
BA_ "SigType" SG_ 2147548609 EngIntkVlvActtionSystemOilPress "RANGE";
BA_ "SPN" SG_ 2147548609 EngIntkVlvActtionSystemOilPress 2948;
BA_ "SigType" SG_ 2147548891 EngInjectorMeteringRail2Press "RANGE";
BA_ "SPN" SG_ 2147548891 EngInjectorMeteringRail2Press 1349;
BA_ "SigType" SG_ 2147548891 EngInjectorTimingRail1Press "RANGE";
BA_ "SPN" SG_ 2147548891 EngInjectorTimingRail1Press 156;
BA_ "SigType" SG_ 2147548891 EngInjectorMeteringRail1Press "RANGE";
BA_ "SPN" SG_ 2147548891 EngInjectorMeteringRail1Press 157;
BA_ "SigType" SG_ 2147548891 EngInjectionCtrlPress "RANGE";
BA_ "SPN" SG_ 2147548891 EngInjectionCtrlPress 164;
BA_ "SigType" SG_ 2147548911 EngCoolantLevel "RANGE";
BA_ "SPN" SG_ 2147548911 EngCoolantLevel 111;
BA_ "SigType" SG_ 2147548911 EngCoolantPress "RANGE";
BA_ "SPN" SG_ 2147548911 EngCoolantPress 109;
BA_ "SigType" SG_ 2147548911 EngCrankcasePress "RANGE";
BA_ "SPN" SG_ 2147548911 EngCrankcasePress 101;
BA_ "SigType" SG_ 2147548911 EngOilPress "RANGE";
BA_ "SPN" SG_ 2147548911 EngOilPress 100;
BA_ "SigType" SG_ 2147548911 EngOilLevel "RANGE";
BA_ "SPN" SG_ 2147548911 EngOilLevel 98;
BA_ "SigType" SG_ 2147548911 EngExCrankcaseBlowbyPress "DISCRETE";
BA_ "SPN" SG_ 2147548911 EngExCrankcaseBlowbyPress 22;
BA_ "SigType" SG_ 2147548911 EngFuelDeliveryPress "RANGE";
BA_ "SPN" SG_ 2147548911 EngFuelDeliveryPress 94;
BA_ "SigType" SG_ 2147548819 TurningGearEngaged "DISCRETE";
BA_ "SPN" SG_ 2147548819 TurningGearEngaged 1206;
BA_ "SigType" SG_ 2147548819 SafetyWireStatus "DISCRETE";
BA_ "SPN" SG_ 2147548819 SafetyWireStatus 1205;
BA_ "SigType" SG_ 2147548819 ElectricalLoad "RANGE";
BA_ "SPN" SG_ 2147548819 ElectricalLoad 1204;
BA_ "SigType" SG_ 2147548629 EngVrblGometryTurbo1ActuatorPos "RANGE";
BA_ "SPN" SG_ 2147548629 EngVrblGometryTurbo1ActuatorPos 2795;
BA_ "SigType" SG_ 2147548629 EngVrblGmtryTrbArCtrlShtffValve "DISCRETE";
BA_ "SPN" SG_ 2147548629 EngVrblGmtryTrbArCtrlShtffValve 2792;
BA_ "SigType" SG_ 2147548629 EngExhstGsRcirculationValveCtrl "RANGE";
BA_ "SPN" SG_ 2147548629 EngExhstGsRcirculationValveCtrl 2791;
BA_ "SigType" SG_ 2147548629 EngTrb1ClcltedTurbineOutletTemp "RANGE";
BA_ "SPN" SG_ 2147548629 EngTrb1ClcltedTurbineOutletTemp 2790;
BA_ "SigType" SG_ 2147548629 EngTrb1ClclatedTurbineInletTemp "RANGE";
BA_ "SPN" SG_ 2147548629 EngTrb1ClclatedTurbineInletTemp 2789;
BA_ "SigType" SG_ 2147548862 EngRatedSpeed "RANGE";
BA_ "SPN" SG_ 2147548862 EngRatedSpeed 189;
BA_ "SigType" SG_ 2147548862 EngRatedPower "RANGE";
BA_ "SPN" SG_ 2147548862 EngRatedPower 166;
BA_ "SigType" SG_ 2147548895 EstEngPrsticLossesPercentTorque "RANGE";
BA_ "SPN" SG_ 2147548895 EstEngPrsticLossesPercentTorque 2978;
BA_ "SigType" SG_ 2147548895 EngsDsrdOprtngSpdAsymmtryAdjstmn "RANGE";
BA_ "SPN" SG_ 2147548895 EngsDsrdOprtngSpdAsymmtryAdjstmn 519;
BA_ "SigType" SG_ 2147548895 EngsDesiredOperatingSpeed "RANGE";
BA_ "SPN" SG_ 2147548895 EngsDesiredOperatingSpeed 515;
BA_ "SigType" SG_ 2147548895 NominalFrictionPercentTorque "RANGE";
BA_ "SPN" SG_ 2147548895 NominalFrictionPercentTorque 514;
BA_ "SigType" SG_ 2147545091 AccelPedalPos2 "RANGE";
BA_ "SPN" SG_ 2147545091 AccelPedalPos2 29;
BA_ "SigType" SG_ 2147545091 VhclAccelerationRateLimitStatus "DISCRETE";
BA_ "SPN" SG_ 2147545091 VhclAccelerationRateLimitStatus 2979;
BA_ "SigType" SG_ 2147545091 EngPercentLoadAtCurrentSpeed "RANGE";
BA_ "SPN" SG_ 2147545091 EngPercentLoadAtCurrentSpeed 92;
BA_ "SigType" SG_ 2147545091 AccelPedal2LowIdleSwitch "DISCRETE";
BA_ "SPN" SG_ 2147545091 AccelPedal2LowIdleSwitch 2970;
BA_ "SigType" SG_ 2147545091 RoadSpeedLimitStatus "DISCRETE";
BA_ "SPN" SG_ 2147545091 RoadSpeedLimitStatus 1437;
BA_ "SigType" SG_ 2147545091 AccelPedalKickdownSwitch "DISCRETE";
BA_ "SPN" SG_ 2147545091 AccelPedalKickdownSwitch 559;
BA_ "SigType" SG_ 2147545091 AccelPedal1LowIdleSwitch "DISCRETE";
BA_ "SPN" SG_ 2147545091 AccelPedal1LowIdleSwitch 558;
BA_ "SigType" SG_ 2147545091 RemoteAccelPedalPos "RANGE";
BA_ "SPN" SG_ 2147545091 RemoteAccelPedalPos 974;
BA_ "SigType" SG_ 2147545091 AccelPedalPos1 "RANGE";
BA_ "SPN" SG_ 2147545091 AccelPedalPos1 91;
BA_ "SigType" SG_ 2147545092 EngDemandPercentTorque "RANGE";
BA_ "SPN" SG_ 2147545092 EngDemandPercentTorque 2432;
BA_ "SigType" SG_ 2147545092 EngStarterMode "DISCRETE";
BA_ "SPN" SG_ 2147545092 EngStarterMode 1675;
BA_ "SigType" SG_ 2147545092 SrcAddrssOfCtrllngDvcForEngCtrl "RANGE";
BA_ "SPN" SG_ 2147545092 SrcAddrssOfCtrllngDvcForEngCtrl 1483;
BA_ "SigType" SG_ 2147545092 EngSpeed "RANGE";
BA_ "SPN" SG_ 2147545092 EngSpeed 190;
BA_ "SigType" SG_ 2147545092 ActualEngPercentTorque "RANGE";
BA_ "SPN" SG_ 2147545092 ActualEngPercentTorque 513;
BA_ "SigType" SG_ 2147545092 DriversDemandEngPercentTorque "RANGE";
BA_ "SPN" SG_ 2147545092 DriversDemandEngPercentTorque 512;
BA_ "SigType" SG_ 2147545092 EngTorqueMode "DISCRETE";
BA_ "SPN" SG_ 2147545092 EngTorqueMode 899;
BA_ "SigType" SG_ 2147548756 EngMinContinuousTorque "RANGE";
BA_ "SPN" SG_ 2147548756 EngMinContinuousTorque 1775;
BA_ "SigType" SG_ 2147548756 EngMaxContinuousTorque "RANGE";
BA_ "SPN" SG_ 2147548756 EngMaxContinuousTorque 1774;
BA_ "SigType" SG_ 2147548756 EngMinContinuousRPM "RANGE";
BA_ "SPN" SG_ 2147548756 EngMinContinuousRPM 1773;
BA_ "SigType" SG_ 2147548756 EngMaxContinuousRPM "RANGE";
BA_ "SPN" SG_ 2147548756 EngMaxContinuousRPM 1772;
BA_ "SigType" SG_ 2147548756 EngHghLmtThrshhldFrMnCntnsTrqFrm "RANGE";
BA_ "SPN" SG_ 2147548756 EngHghLmtThrshhldFrMnCntnsTrqFrm 1771;
BA_ "SigType" SG_ 2147548756 EngLwLmtThrshldFrMxTrqueFromEng "RANGE";
BA_ "SPN" SG_ 2147548756 EngLwLmtThrshldFrMxTrqueFromEng 1770;
BA_ "SigType" SG_ 2147548756 EngHghLmtThrshhldFrMnCntnsEngRPM "RANGE";
BA_ "SPN" SG_ 2147548756 EngHghLmtThrshhldFrMnCntnsEngRPM 1769;
BA_ "SigType" SG_ 2147548756 EngLwLmtThrshhldFrMaxRPMFromEng "RANGE";
BA_ "SPN" SG_ 2147548756 EngLwLmtThrshhldFrMaxRPMFromEng 1768;
BA_ "SigType" SG_ 2147548899 EngDefaultTorqueLimit "RANGE";
BA_ "SPN" SG_ 2147548899 EngDefaultTorqueLimit 1846;
BA_ "SigType" SG_ 2147548899 EngMomentOfInertia "RANGE";
BA_ "SPN" SG_ 2147548899 EngMomentOfInertia 1794;
BA_ "SigType" SG_ 2147548899 EngExRngRqdSpdCtrlRngUpperLimit "RANGE";
BA_ "SPN" SG_ 2147548899 EngExRngRqdSpdCtrlRngUpperLimit 1712;
BA_ "SigType" SG_ 2147548899 EngRqdTorqueCtrlRangeUpperLimit "RANGE";
BA_ "SPN" SG_ 2147548899 EngRqdTorqueCtrlRangeUpperLimit 538;
BA_ "SigType" SG_ 2147548899 EngRqdTorqueCtrlRangeLowerLimit "RANGE";
BA_ "SPN" SG_ 2147548899 EngRqdTorqueCtrlRangeLowerLimit 537;
BA_ "SigType" SG_ 2147548899 EngRqedSpeedCtrlRangeUpperLimit "RANGE";
BA_ "SPN" SG_ 2147548899 EngRqedSpeedCtrlRangeUpperLimit 536;
BA_ "SigType" SG_ 2147548899 EngRqedSpeedCtrlRangeLowerLimit "RANGE";
BA_ "SPN" SG_ 2147548899 EngRqedSpeedCtrlRangeLowerLimit 535;
BA_ "SigType" SG_ 2147548899 EngMxMomentaryOverrideTimeLimit "RANGE";
BA_ "SPN" SG_ 2147548899 EngMxMomentaryOverrideTimeLimit 534;
BA_ "SigType" SG_ 2147548899 EngMxMmntaryOverrideSpeedPoint7 "RANGE";
BA_ "SPN" SG_ 2147548899 EngMxMmntaryOverrideSpeedPoint7 533;
BA_ "SigType" SG_ 2147548899 EngReferenceTorque "RANGE";
BA_ "SPN" SG_ 2147548899 EngReferenceTorque 544;
BA_ "SigType" SG_ 2147548899 EngSpeedAtHighIdlePoint6 "RANGE";
BA_ "SPN" SG_ 2147548899 EngSpeedAtHighIdlePoint6 532;
BA_ "SigType" SG_ 2147548899 EngGainOfEndspeedGovernor "RANGE";
BA_ "SPN" SG_ 2147548899 EngGainOfEndspeedGovernor 545;
BA_ "SigType" SG_ 2147548899 EngPercentTorqueAtPoint5 "RANGE";
BA_ "SPN" SG_ 2147548899 EngPercentTorqueAtPoint5 543;
BA_ "SigType" SG_ 2147548899 EngSpeedAtPoint5 "RANGE";
BA_ "SPN" SG_ 2147548899 EngSpeedAtPoint5 531;
BA_ "SigType" SG_ 2147548899 EngPercentTorqueAtPoint4 "RANGE";
BA_ "SPN" SG_ 2147548899 EngPercentTorqueAtPoint4 542;
BA_ "SigType" SG_ 2147548899 EngSpeedAtPoint4 "RANGE";
BA_ "SPN" SG_ 2147548899 EngSpeedAtPoint4 530;
BA_ "SigType" SG_ 2147548899 EngPercentTorqueAtPoint3 "RANGE";
BA_ "SPN" SG_ 2147548899 EngPercentTorqueAtPoint3 541;
BA_ "SigType" SG_ 2147548899 EngSpeedAtPoint3 "RANGE";
BA_ "SPN" SG_ 2147548899 EngSpeedAtPoint3 529;
BA_ "SigType" SG_ 2147548899 EngPercentTorqueAtPoint2 "RANGE";
BA_ "SPN" SG_ 2147548899 EngPercentTorqueAtPoint2 540;
BA_ "SigType" SG_ 2147548899 EngSpeedAtPoint2 "RANGE";
BA_ "SPN" SG_ 2147548899 EngSpeedAtPoint2 528;
BA_ "SigType" SG_ 2147548899 EngPercentTorqueAtIdlePoint1 "RANGE";
BA_ "SPN" SG_ 2147548899 EngPercentTorqueAtIdlePoint1 539;
BA_ "SigType" SG_ 2147548899 EngSpeedAtIdlePoint1 "RANGE";
BA_ "SPN" SG_ 2147548899 EngSpeedAtIdlePoint1 188;
BA_ "SigType" SG_ 2147548612 XBRAccelerationLimit "RANGE";
BA_ "SPN" SG_ 2147548612 XBRAccelerationLimit 2921;
BA_ "SigType" SG_ 2147548612 XBRActiveCtrlMode "DISCRETE";
BA_ "SPN" SG_ 2147548612 XBRActiveCtrlMode 2918;
BA_ "SigType" SG_ 2147548612 XBRSystemState "DISCRETE";
BA_ "SPN" SG_ 2147548612 XBRSystemState 2917;
BA_ "SigType" SG_ 2147548612 FoundationBrakeUse "DISCRETE";
BA_ "SPN" SG_ 2147548612 FoundationBrakeUse 2919;
BA_ "SigType" SG_ 2147548612 HillHolderMode "DISCRETE";
BA_ "SPN" SG_ 2147548612 HillHolderMode 2912;
BA_ "SigType" SG_ 2147548612 HaltBrakeMode "DISCRETE";
BA_ "SPN" SG_ 2147548612 HaltBrakeMode 2913;
BA_ "SigType" SG_ 2147548844 BrkLnngRmnngRearAxle3RightWheel "RANGE";
BA_ "SPN" SG_ 2147548844 BrkLnngRmnngRearAxle3RightWheel 1106;
BA_ "SigType" SG_ 2147548844 BrkLnngRmningRearAxle3LeftWheel "RANGE";
BA_ "SPN" SG_ 2147548844 BrkLnngRmningRearAxle3LeftWheel 1105;
BA_ "SigType" SG_ 2147548844 BrkLnngRmnngRearAxle2RightWheel "RANGE";
BA_ "SPN" SG_ 2147548844 BrkLnngRmnngRearAxle2RightWheel 1104;
BA_ "SigType" SG_ 2147548844 BrkLnngRmningRearAxle2LeftWheel "RANGE";
BA_ "SPN" SG_ 2147548844 BrkLnngRmningRearAxle2LeftWheel 1103;
BA_ "SigType" SG_ 2147548844 BrkLnngRmnngRearAxle1RightWheel "RANGE";
BA_ "SPN" SG_ 2147548844 BrkLnngRmnngRearAxle1RightWheel 1102;
BA_ "SigType" SG_ 2147548844 BrkLnngRmningRearAxle1LeftWheel "RANGE";
BA_ "SPN" SG_ 2147548844 BrkLnngRmningRearAxle1LeftWheel 1101;
BA_ "SigType" SG_ 2147548844 BrkLnngRmnngFrontAxleRightWheel "RANGE";
BA_ "SPN" SG_ 2147548844 BrkLnngRmnngFrontAxleRightWheel 1100;
BA_ "SigType" SG_ 2147548844 BrkLnngRmningFrontAxleLeftWheel "RANGE";
BA_ "SPN" SG_ 2147548844 BrkLnngRmningFrontAxleLeftWheel 1099;
BA_ "SigType" SG_ 2147548845 BrkAppPrssHghRngRrAxl3RghtWheel "RANGE";
BA_ "SPN" SG_ 2147548845 BrkAppPrssHghRngRrAxl3RghtWheel 1098;
BA_ "SigType" SG_ 2147548845 BrkAppPrssHghRngRrAxl3LeftWheel "RANGE";
BA_ "SPN" SG_ 2147548845 BrkAppPrssHghRngRrAxl3LeftWheel 1097;
BA_ "SigType" SG_ 2147548845 BrkAppPrssHghRngRrAxl2RghtWheel "RANGE";
BA_ "SPN" SG_ 2147548845 BrkAppPrssHghRngRrAxl2RghtWheel 1096;
BA_ "SigType" SG_ 2147548845 BrkAppPrssHghRngRrAxl2LeftWheel "RANGE";
BA_ "SPN" SG_ 2147548845 BrkAppPrssHghRngRrAxl2LeftWheel 1095;
BA_ "SigType" SG_ 2147548845 BrkAppPrssHghRngRrAxl1RghtWheel "RANGE";
BA_ "SPN" SG_ 2147548845 BrkAppPrssHghRngRrAxl1RghtWheel 1094;
BA_ "SigType" SG_ 2147548845 BrkAppPrssHghRngRrAxl1LeftWheel "RANGE";
BA_ "SPN" SG_ 2147548845 BrkAppPrssHghRngRrAxl1LeftWheel 1093;
BA_ "SigType" SG_ 2147548845 BrkAppPrssHghRngFrntAxlRghtWhel "RANGE";
BA_ "SPN" SG_ 2147548845 BrkAppPrssHghRngFrntAxlRghtWhel 1092;
BA_ "SigType" SG_ 2147548845 BrkAppPrssHghRngFrntAxlLftWheel "RANGE";
BA_ "SPN" SG_ 2147548845 BrkAppPrssHghRngFrntAxlLftWheel 1091;
BA_ "SigType" SG_ 2147548863 RlativeSpeedRearAxle2RightWheel "RANGE";
BA_ "SPN" SG_ 2147548863 RlativeSpeedRearAxle2RightWheel 910;
BA_ "SigType" SG_ 2147548863 RelativeSpeedRearAxle2LeftWheel "RANGE";
BA_ "SPN" SG_ 2147548863 RelativeSpeedRearAxle2LeftWheel 909;
BA_ "SigType" SG_ 2147548863 RlativeSpeedRearAxle1RightWheel "RANGE";
BA_ "SPN" SG_ 2147548863 RlativeSpeedRearAxle1RightWheel 908;
BA_ "SigType" SG_ 2147548863 RelativeSpeedRearAxle1LeftWheel "RANGE";
BA_ "SPN" SG_ 2147548863 RelativeSpeedRearAxle1LeftWheel 907;
BA_ "SigType" SG_ 2147548863 RlativeSpeedFrontAxleRightWheel "RANGE";
BA_ "SPN" SG_ 2147548863 RlativeSpeedFrontAxleRightWheel 906;
BA_ "SigType" SG_ 2147548863 RelativeSpeedFrontAxleLeftWheel "RANGE";
BA_ "SPN" SG_ 2147548863 RelativeSpeedFrontAxleLeftWheel 905;
BA_ "SigType" SG_ 2147548863 FrontAxleSpeed "RANGE";
BA_ "SPN" SG_ 2147548863 FrontAxleSpeed 904;
BA_ "SigType" SG_ 2147545089 SrcAddrssOfCtrllngDvcFrBrkCntrl "RANGE";
BA_ "SPN" SG_ 2147545089 SrcAddrssOfCtrllngDvcFrBrkCntrl 1481;
BA_ "SigType" SG_ 2147545089 BrakePedalPos "RANGE";
BA_ "SPN" SG_ 2147545089 BrakePedalPos 521;
BA_ "SigType" SG_ 2147545089 TrctrMntdTrilerABSWarningSignal "DISCRETE";
BA_ "SPN" SG_ 2147545089 TrctrMntdTrilerABSWarningSignal 1792;
BA_ "SigType" SG_ 2147545089 TrailerABSStatus "DISCRETE";
BA_ "SPN" SG_ 2147545089 TrailerABSStatus 1836;
BA_ "SigType" SG_ 2147545089 HaltBrakeSwitch "DISCRETE";
BA_ "SPN" SG_ 2147545089 HaltBrakeSwitch 2911;
BA_ "SigType" SG_ 2147545089 ATC_ASRInformationSignal "DISCRETE";
BA_ "SPN" SG_ 2147545089 ATC_ASRInformationSignal 1793;
BA_ "SigType" SG_ 2147545089 ABS_EBSAmberWarningSignal "DISCRETE";
BA_ "SPN" SG_ 2147545089 ABS_EBSAmberWarningSignal 1438;
BA_ "SigType" SG_ 2147545089 EBSRedWarningSignal "DISCRETE";
BA_ "SPN" SG_ 2147545089 EBSRedWarningSignal 1439;
BA_ "SigType" SG_ 2147545089 ABSFullyOperational "DISCRETE";
BA_ "SPN" SG_ 2147545089 ABSFullyOperational 1243;
BA_ "SigType" SG_ 2147545089 EngRetarderSelection "RANGE";
BA_ "SPN" SG_ 2147545089 EngRetarderSelection 973;
BA_ "SigType" SG_ 2147545089 RemoteAccelEnableSwitch "DISCRETE";
BA_ "SPN" SG_ 2147545089 RemoteAccelEnableSwitch 969;
BA_ "SigType" SG_ 2147545089 EngAuxEngShutdownSwitch "DISCRETE";
BA_ "SPN" SG_ 2147545089 EngAuxEngShutdownSwitch 970;
BA_ "SigType" SG_ 2147545089 EngDerateSwitch "DISCRETE";
BA_ "SPN" SG_ 2147545089 EngDerateSwitch 971;
BA_ "SigType" SG_ 2147545089 AccelInterlockSwitch "DISCRETE";
BA_ "SPN" SG_ 2147545089 AccelInterlockSwitch 972;
BA_ "SigType" SG_ 2147545089 TractionCtrlOverrideSwitch "DISCRETE";
BA_ "SPN" SG_ 2147545089 TractionCtrlOverrideSwitch 1238;
BA_ "SigType" SG_ 2147545089 ASRHillHolderSwitch "DISCRETE";
BA_ "SPN" SG_ 2147545089 ASRHillHolderSwitch 577;
BA_ "SigType" SG_ 2147545089 ASROffroadSwitch "DISCRETE";
BA_ "SPN" SG_ 2147545089 ASROffroadSwitch 576;
BA_ "SigType" SG_ 2147545089 ABSOffroadSwitch "DISCRETE";
BA_ "SPN" SG_ 2147545089 ABSOffroadSwitch 575;
BA_ "SigType" SG_ 2147545089 EBSBrakeSwitch "DISCRETE";
BA_ "SPN" SG_ 2147545089 EBSBrakeSwitch 1121;
BA_ "SigType" SG_ 2147545089 AntiLockBrakingActive "DISCRETE";
BA_ "SPN" SG_ 2147545089 AntiLockBrakingActive 563;
BA_ "SigType" SG_ 2147545089 ASRBrakeCtrlActive "DISCRETE";
BA_ "SPN" SG_ 2147545089 ASRBrakeCtrlActive 562;
BA_ "SigType" SG_ 2147545089 ASREngCtrlActive "DISCRETE";
BA_ "SPN" SG_ 2147545089 ASREngCtrlActive 561;
BA_ "SigType" SG_ 2147545094 DiffLockStateCentralRear "DISCRETE";
BA_ "SPN" SG_ 2147545094 DiffLockStateCentralRear 566;
BA_ "SigType" SG_ 2147545094 DiffLockStateCentralFront "DISCRETE";
BA_ "SPN" SG_ 2147545094 DiffLockStateCentralFront 565;
BA_ "SigType" SG_ 2147545094 DiffLockStateCentral "DISCRETE";
BA_ "SPN" SG_ 2147545094 DiffLockStateCentral 564;
BA_ "SigType" SG_ 2147545094 DiffLockStateRearAxle2 "DISCRETE";
BA_ "SPN" SG_ 2147545094 DiffLockStateRearAxle2 570;
BA_ "SigType" SG_ 2147545094 DiffLockStateRearAxle1 "DISCRETE";
BA_ "SPN" SG_ 2147545094 DiffLockStateRearAxle1 569;
BA_ "SigType" SG_ 2147545094 DiffLockStateFrontAxle2 "DISCRETE";
BA_ "SPN" SG_ 2147545094 DiffLockStateFrontAxle2 568;
BA_ "SigType" SG_ 2147545094 DiffLockStateFrontAxle1 "DISCRETE";
BA_ "SPN" SG_ 2147545094 DiffLockStateFrontAxle1 567;
BA_ "SigType" SG_ 2147545094 Location "RANGE";
BA_ "SPN" SG_ 2147545094 Location 927;
BA_ "SigType" SG_ 2147548820 SeaWaterPumpOutletPress "RANGE";
BA_ "SPN" SG_ 2147548820 SeaWaterPumpOutletPress 2435;
BA_ "SigType" SG_ 2147548820 EngAuxCoolantTemp "RANGE";
BA_ "SPN" SG_ 2147548820 EngAuxCoolantTemp 1212;
BA_ "SigType" SG_ 2147548820 EngAuxCoolantPress "RANGE";
BA_ "SPN" SG_ 2147548820 EngAuxCoolantPress 1203;
BA_ "SigType" SG_ 2147548924 CargoAmbientTemp "RANGE";
BA_ "SPN" SG_ 2147548924 CargoAmbientTemp 169;
BA_ "SigType" SG_ 2147548924 EngOilFilterDiffPress "RANGE";
BA_ "SPN" SG_ 2147548924 EngOilFilterDiffPress 99;
BA_ "SigType" SG_ 2147548924 EngFuelFilterDiffPress "RANGE";
BA_ "SPN" SG_ 2147548924 EngFuelFilterDiffPress 1382;
BA_ "SigType" SG_ 2147548924 FuelLevel "RANGE";
BA_ "SPN" SG_ 2147548924 FuelLevel 96;
BA_ "SigType" SG_ 2147548924 WasherFluidLevel "RANGE";
BA_ "SPN" SG_ 2147548924 WasherFluidLevel 80;
BA_ "SigType" SG_ 2147548750 Ramp_WheelChairLiftPos "DISCRETE";
BA_ "SPN" SG_ 2147548750 Ramp_WheelChairLiftPos 1820;
BA_ "SigType" SG_ 2147548750 PosOfDoors "DISCRETE";
BA_ "SPN" SG_ 2147548750 PosOfDoors 1821;
BA_ "SigType" SG_ 2147548614 EngStartEnableDevice2Config "DISCRETE";
BA_ "SPN" SG_ 2147548614 EngStartEnableDevice2Config 2898;
BA_ "SigType" SG_ 2147548614 EngStartEnableDevice1Config "DISCRETE";
BA_ "SPN" SG_ 2147548614 EngStartEnableDevice1Config 2899;
BA_ "SigType" SG_ 2147548614 EngStartEnableDevice2 "DISCRETE";
BA_ "SPN" SG_ 2147548614 EngStartEnableDevice2 1804;
BA_ "SigType" SG_ 2147548614 EngStartEnableDevice1 "DISCRETE";
BA_ "SPN" SG_ 2147548614 EngStartEnableDevice1 626;
BA_ "SigType" SG_ 2147548784 PoweredVehicleWeight "RANGE";
BA_ "SPN" SG_ 2147548784 PoweredVehicleWeight 1585;
BA_ "SigType" SG_ 2147548784 GrossCombinationVehicleWeight "RANGE";
BA_ "SPN" SG_ 2147548784 GrossCombinationVehicleWeight 1760;
BA_ "SigType" SG_ 2147536640 MxCntnuousRetarderTorqueLimitRq "RANGE";
BA_ "SPN" SG_ 2147536640 MxCntnuousRetarderTorqueLimitRq 1791;
BA_ "SigType" SG_ 2147536640 MnCntnuousRetarderTorqueLimitRq "RANGE";
BA_ "SPN" SG_ 2147536640 MnCntnuousRetarderTorqueLimitRq 1790;
BA_ "SigType" SG_ 2147536640 MxCntinuousRetarderSpeedLimitRq "RANGE";
BA_ "SPN" SG_ 2147536640 MxCntinuousRetarderSpeedLimitRq 1789;
BA_ "SigType" SG_ 2147536640 MnCntinuousRetarderSpeedLimitRq "RANGE";
BA_ "SPN" SG_ 2147536640 MnCntinuousRetarderSpeedLimitRq 1788;
BA_ "SigType" SG_ 2147536640 EngTorqueLimitRqMaxContinuous "RANGE";
BA_ "SPN" SG_ 2147536640 EngTorqueLimitRqMaxContinuous 1787;
BA_ "SigType" SG_ 2147536640 EngTorqueLimitRqMinContinuous "RANGE";
BA_ "SPN" SG_ 2147536640 EngTorqueLimitRqMinContinuous 1786;
BA_ "SigType" SG_ 2147536640 EngSpeedLimitRqMaxContinuous "RANGE";
BA_ "SPN" SG_ 2147536640 EngSpeedLimitRqMaxContinuous 1785;
BA_ "SigType" SG_ 2147536640 EngSpeedLimitRqMinContinuous "RANGE";
BA_ "SPN" SG_ 2147536640 EngSpeedLimitRqMinContinuous 1784;
BA_ "SigType" SG_ 2147548800 EngAverageCombustionTime "RANGE";
BA_ "SPN" SG_ 2147548800 EngAverageCombustionTime 1465;
BA_ "SigType" SG_ 2147548800 EngDesiredCombustionTime "RANGE";
BA_ "SPN" SG_ 2147548800 EngDesiredCombustionTime 1464;
BA_ "SigType" SG_ 2147548799 EngCyl20CombustionTime "RANGE";
BA_ "SPN" SG_ 2147548799 EngCyl20CombustionTime 1463;
BA_ "SigType" SG_ 2147548799 EngCyl19CombustionTime "RANGE";
BA_ "SPN" SG_ 2147548799 EngCyl19CombustionTime 1462;
BA_ "SigType" SG_ 2147548799 EngCyl18CombustionTime "RANGE";
BA_ "SPN" SG_ 2147548799 EngCyl18CombustionTime 1461;
BA_ "SigType" SG_ 2147548799 EngCyl17CombustionTime "RANGE";
BA_ "SPN" SG_ 2147548799 EngCyl17CombustionTime 1460;
BA_ "SigType" SG_ 2147548798 EngCyl16CombustionTime "RANGE";
BA_ "SPN" SG_ 2147548798 EngCyl16CombustionTime 1459;
BA_ "SigType" SG_ 2147548798 EngCyl15CombustionTime "RANGE";
BA_ "SPN" SG_ 2147548798 EngCyl15CombustionTime 1458;
BA_ "SigType" SG_ 2147548798 EngCyl14CombustionTime "RANGE";
BA_ "SPN" SG_ 2147548798 EngCyl14CombustionTime 1457;
BA_ "SigType" SG_ 2147548798 EngCyl13CombustionTime "RANGE";
BA_ "SPN" SG_ 2147548798 EngCyl13CombustionTime 1456;
BA_ "SigType" SG_ 2147548797 EngCyl12CombustionTime "RANGE";
BA_ "SPN" SG_ 2147548797 EngCyl12CombustionTime 1455;
BA_ "SigType" SG_ 2147548797 EngCyl11CombustionTime "RANGE";
BA_ "SPN" SG_ 2147548797 EngCyl11CombustionTime 1454;
BA_ "SigType" SG_ 2147548797 EngCyl10CombustionTime "RANGE";
BA_ "SPN" SG_ 2147548797 EngCyl10CombustionTime 1453;
BA_ "SigType" SG_ 2147548797 EngCyl9CombustionTime "RANGE";
BA_ "SPN" SG_ 2147548797 EngCyl9CombustionTime 1452;
BA_ "SigType" SG_ 2147548796 EngCyl8CombustionTime "RANGE";
BA_ "SPN" SG_ 2147548796 EngCyl8CombustionTime 1451;
BA_ "SigType" SG_ 2147548796 EngCyl7CombustionTime "RANGE";
BA_ "SPN" SG_ 2147548796 EngCyl7CombustionTime 1450;
BA_ "SigType" SG_ 2147548796 EngCyl6CombustionTime "RANGE";
BA_ "SPN" SG_ 2147548796 EngCyl6CombustionTime 1449;
BA_ "SigType" SG_ 2147548796 EngCyl5CombustionTime "RANGE";
BA_ "SPN" SG_ 2147548796 EngCyl5CombustionTime 1448;
BA_ "SigType" SG_ 2147548795 EngCyl4CombustionTime "RANGE";
BA_ "SPN" SG_ 2147548795 EngCyl4CombustionTime 1447;
BA_ "SigType" SG_ 2147548795 EngCyl3CombustionTime "RANGE";
BA_ "SPN" SG_ 2147548795 EngCyl3CombustionTime 1446;
BA_ "SigType" SG_ 2147548795 EngCyl2CombustionTime "RANGE";
BA_ "SPN" SG_ 2147548795 EngCyl2CombustionTime 1445;
BA_ "SigType" SG_ 2147548795 EngCyl1CombustionTime "RANGE";
BA_ "SPN" SG_ 2147548795 EngCyl1CombustionTime 1444;
BA_ "SigType" SG_ 2147548617 TotalCountOfConfigChangesMade "RANGE";
BA_ "SPN" SG_ 2147548617 TotalCountOfConfigChangesMade 2887;
BA_ "SigType" SG_ 2147548628 TransferCaseSelectorSwitch "DISCRETE";
BA_ "SPN" SG_ 2147548628 TransferCaseSelectorSwitch 2796;
BA_ "SigType" SG_ 2147540992 SelectedMaxVehicleSpeedLimit "RANGE";
BA_ "SPN" SG_ 2147540992 SelectedMaxVehicleSpeedLimit 2596;
BA_ "SigType" SG_ 2147540992 RqCabZoneHeating "DISCRETE";
BA_ "SPN" SG_ 2147540992 RqCabZoneHeating 1686;
BA_ "SigType" SG_ 2147540992 RqEngZoneHeating "DISCRETE";
BA_ "SPN" SG_ 2147540992 RqEngZoneHeating 1685;
BA_ "SigType" SG_ 2147540992 AuxHeaterModeRq "DISCRETE";
BA_ "SPN" SG_ 2147540992 AuxHeaterModeRq 1683;
BA_ "SigType" SG_ 2147540992 EngAutomaticStartEnableSwitch "DISCRETE";
BA_ "SPN" SG_ 2147540992 EngAutomaticStartEnableSwitch 1656;
BA_ "SigType" SG_ 2147540992 AtmaticGearShiftingEnableSwitch "DISCRETE";
BA_ "SPN" SG_ 2147540992 AtmaticGearShiftingEnableSwitch 1666;
BA_ "SigType" SG_ 2147540992 VhclLmtngSpdGvernorEnableSwitch "DISCRETE";
BA_ "SPN" SG_ 2147540992 VhclLmtngSpdGvernorEnableSwitch 1653;
BA_ "SigType" SG_ 2147540992 VhclLmtngSpdGvrnrIncrmentSwitch "DISCRETE";
BA_ "SPN" SG_ 2147540992 VhclLmtngSpdGvrnrIncrmentSwitch 1654;
BA_ "SigType" SG_ 2147540992 VhclLmtngSpdGvrnrDcrementSwitch "DISCRETE";
BA_ "SPN" SG_ 2147540992 VhclLmtngSpdGvrnrDcrementSwitch 1655;
BA_ "SigType" SG_ 2147540992 SeatBeltSwitch "DISCRETE";
BA_ "SPN" SG_ 2147540992 SeatBeltSwitch 1856;
BA_ "SigType" SG_ 2147540992 OperatorSeatDirectionSwitch "DISCRETE";
BA_ "SPN" SG_ 2147540992 OperatorSeatDirectionSwitch 1714;
BA_ "SigType" SG_ 2147540992 BatteryMainSwitchHoldRq "DISCRETE";
BA_ "SPN" SG_ 2147540992 BatteryMainSwitchHoldRq 1682;
BA_ "SigType" SG_ 2147540992 AuxHeaterCoolantPumpRq "DISCRETE";
BA_ "SPN" SG_ 2147540992 AuxHeaterCoolantPumpRq 1684;
BA_ "SigType" SG_ 2147540992 CabInteriorTempCmd "RANGE";
BA_ "SPN" SG_ 2147540992 CabInteriorTempCmd 1691;
BA_ "SigType" SG_ 2147540992 RqedPercentFanSpeed "RANGE";
BA_ "SPN" SG_ 2147540992 RqedPercentFanSpeed 986;
BA_ "SigType" SG_ 2147536896 IlluminationBrightnessPercent "RANGE";
BA_ "SPN" SG_ 2147536896 IlluminationBrightnessPercent 1487;
BA_ "SigType" SG_ 2147548913 EngShutdownOverrideSwitch "DISCRETE";
BA_ "SPN" SG_ 2147548913 EngShutdownOverrideSwitch 1237;
BA_ "SigType" SG_ 2147548913 EngTestModeSwitch "DISCRETE";
BA_ "SPN" SG_ 2147548913 EngTestModeSwitch 966;
BA_ "SigType" SG_ 2147548913 EngIdleDecrementSwitch "DISCRETE";
BA_ "SPN" SG_ 2147548913 EngIdleDecrementSwitch 967;
BA_ "SigType" SG_ 2147548913 EngIdleIncrementSwitch "DISCRETE";
BA_ "SPN" SG_ 2147548913 EngIdleIncrementSwitch 968;
BA_ "SigType" SG_ 2147548913 CruiseCtrlStates "DISCRETE";
BA_ "SPN" SG_ 2147548913 CruiseCtrlStates 527;
BA_ "SigType" SG_ 2147548913 PTOState "RANGE";
BA_ "SPN" SG_ 2147548913 PTOState 976;
BA_ "SigType" SG_ 2147548913 CruiseCtrlSetSpeed "RANGE";
BA_ "SPN" SG_ 2147548913 CruiseCtrlSetSpeed 86;
BA_ "SigType" SG_ 2147548913 CruiseCtrlAccelerateSwitch "DISCRETE";
BA_ "SPN" SG_ 2147548913 CruiseCtrlAccelerateSwitch 602;
BA_ "SigType" SG_ 2147548913 CruiseCtrlResumeSwitch "DISCRETE";
BA_ "SPN" SG_ 2147548913 CruiseCtrlResumeSwitch 601;
BA_ "SigType" SG_ 2147548913 CruiseCtrlCoastSwitch "DISCRETE";
BA_ "SPN" SG_ 2147548913 CruiseCtrlCoastSwitch 600;
BA_ "SigType" SG_ 2147548913 CruiseCtrlSetSwitch "DISCRETE";
BA_ "SPN" SG_ 2147548913 CruiseCtrlSetSwitch 599;
BA_ "SigType" SG_ 2147548913 ClutchSwitch "DISCRETE";
BA_ "SPN" SG_ 2147548913 ClutchSwitch 598;
BA_ "SigType" SG_ 2147548913 BrakeSwitch "DISCRETE";
BA_ "SPN" SG_ 2147548913 BrakeSwitch 597;
BA_ "SigType" SG_ 2147548913 CruiseCtrlEnableSwitch "DISCRETE";
BA_ "SPN" SG_ 2147548913 CruiseCtrlEnableSwitch 596;
BA_ "SigType" SG_ 2147548913 CruiseCtrlActive "DISCRETE";
BA_ "SPN" SG_ 2147548913 CruiseCtrlActive 595;
BA_ "SigType" SG_ 2147548913 WheelBasedVehicleSpeed "RANGE";
BA_ "SPN" SG_ 2147548913 WheelBasedVehicleSpeed 84;
BA_ "SigType" SG_ 2147548913 CruiseCtrlPauseSwitch "DISCRETE";
BA_ "SPN" SG_ 2147548913 CruiseCtrlPauseSwitch 1633;
BA_ "SigType" SG_ 2147548913 ParkingBrakeSwitch "DISCRETE";
BA_ "SPN" SG_ 2147548913 ParkingBrakeSwitch 70;
BA_ "SigType" SG_ 2147548913 TwoSpeedAxleSwitch "DISCRETE";
BA_ "SPN" SG_ 2147548913 TwoSpeedAxleSwitch 69;
BA_ "SigType" SG_ 2147548909 CruiseCtrlLowSetLimitSpeed "RANGE";
BA_ "SPN" SG_ 2147548909 CruiseCtrlLowSetLimitSpeed 88;
BA_ "SigType" SG_ 2147548909 CruiseCtrlHighSetLimitSpeed "RANGE";
BA_ "SPN" SG_ 2147548909 CruiseCtrlHighSetLimitSpeed 87;
BA_ "SigType" SG_ 2147548909 MaxVehicleSpeedLimit "RANGE";
BA_ "SPN" SG_ 2147548909 MaxVehicleSpeedLimit 74;
BA_ "SigType" SG_ 2147548775 AuxHeaterMaxOutputPower "RANGE";
BA_ "SPN" SG_ 2147548775 AuxHeaterMaxOutputPower 1690;
BA_ "SigType" SG_ 2147548860 TripServiceBrakeApps "RANGE";
BA_ "SPN" SG_ 2147548860 TripServiceBrakeApps 993;
BA_ "SigType" SG_ 2147548860 TripServiceBrakeDistance "RANGE";
BA_ "SPN" SG_ 2147548860 TripServiceBrakeDistance 992;
BA_ "SigType" SG_ 2147548860 TripCompressionBrakeDistance "RANGE";
BA_ "SPN" SG_ 2147548860 TripCompressionBrakeDistance 991;
BA_ "SigType" SG_ 2147548860 TotalCompressionBrakeDistance "RANGE";
BA_ "SPN" SG_ 2147548860 TotalCompressionBrakeDistance 990;
BA_ "SigType" SG_ 2147548641 CbA_CRfrgrntCmprssorOutletPress "RANGE";
BA_ "SPN" SG_ 2147548641 CbA_CRfrgrntCmprssorOutletPress 2609;
BA_ "SigType" SG_ 2147548752 Battery2Temp "RANGE";
BA_ "SPN" SG_ 2147548752 Battery2Temp 1801;
BA_ "SigType" SG_ 2147548752 Battery1Temp "RANGE";
BA_ "SPN" SG_ 2147548752 Battery1Temp 1800;
BA_ "SigType" SG_ 2147548774 BatteryMainSwitchHoldState "DISCRETE";
BA_ "SPN" SG_ 2147548774 BatteryMainSwitchHoldState 1681;
BA_ "SigType" SG_ 2147548634 Joystick3XAxisDetentPosStatus "DISCRETE";
BA_ "SPN" SG_ 2147548634 Joystick3XAxisDetentPosStatus 2754;
BA_ "SigType" SG_ 2147548634 Joystick3Button9PressedStatus "DISCRETE";
BA_ "SPN" SG_ 2147548634 Joystick3Button9PressedStatus 2767;
BA_ "SigType" SG_ 2147548634 Joystick3Button10PressedStatus "DISCRETE";
BA_ "SPN" SG_ 2147548634 Joystick3Button10PressedStatus 2768;
BA_ "SigType" SG_ 2147548634 Joystick3Button11PressedStatus "DISCRETE";
BA_ "SPN" SG_ 2147548634 Joystick3Button11PressedStatus 2769;
BA_ "SigType" SG_ 2147548634 Joystick3Button12PressedStatus "DISCRETE";
BA_ "SPN" SG_ 2147548634 Joystick3Button12PressedStatus 2770;
BA_ "SigType" SG_ 2147548634 Joystick3YAxisDetentPosStatus "DISCRETE";
BA_ "SPN" SG_ 2147548634 Joystick3YAxisDetentPosStatus 2755;
BA_ "SigType" SG_ 2147548634 Joystick3YAxisPos "RANGE";
BA_ "SPN" SG_ 2147548634 Joystick3YAxisPos 2735;
BA_ "SigType" SG_ 2147548634 Jystck3YAxsLvrFrwrdPstvPsStatus "DISCRETE";
BA_ "SPN" SG_ 2147548634 Jystck3YAxsLvrFrwrdPstvPsStatus 2740;
BA_ "SigType" SG_ 2147548634 Jystck3YAxsLvrBckNgtvePosStatus "DISCRETE";
BA_ "SPN" SG_ 2147548634 Jystck3YAxsLvrBckNgtvePosStatus 2745;
BA_ "SigType" SG_ 2147548634 Joystick3YAxisNeutralPosStatus "DISCRETE";
BA_ "SPN" SG_ 2147548634 Joystick3YAxisNeutralPosStatus 2750;
BA_ "SigType" SG_ 2147548634 Joystick3XAxisPos "RANGE";
BA_ "SPN" SG_ 2147548634 Joystick3XAxisPos 2734;
BA_ "SigType" SG_ 2147548634 Jystck3XAxsLvrRghtPstvPosStatus "DISCRETE";
BA_ "SPN" SG_ 2147548634 Jystck3XAxsLvrRghtPstvPosStatus 2739;
BA_ "SigType" SG_ 2147548634 Jystck3XAxsLvrLftNgtvePosStatus "DISCRETE";
BA_ "SPN" SG_ 2147548634 Jystck3XAxsLvrLftNgtvePosStatus 2744;
BA_ "SigType" SG_ 2147548634 Joystick3XAxisNeutralPosStatus "DISCRETE";
BA_ "SPN" SG_ 2147548634 Joystick3XAxisNeutralPosStatus 2749;
BA_ "SigType" SG_ 2147548634 Joystick3Button5PressedStatus "DISCRETE";
BA_ "SPN" SG_ 2147548634 Joystick3Button5PressedStatus 2763;
BA_ "SigType" SG_ 2147548634 Joystick3Button6PressedStatus "DISCRETE";
BA_ "SPN" SG_ 2147548634 Joystick3Button6PressedStatus 2764;
BA_ "SigType" SG_ 2147548634 Joystick3Button7PressedStatus "DISCRETE";
BA_ "SPN" SG_ 2147548634 Joystick3Button7PressedStatus 2765;
BA_ "SigType" SG_ 2147548634 Joystick3Button8PressedStatus "DISCRETE";
BA_ "SPN" SG_ 2147548634 Joystick3Button8PressedStatus 2766;
BA_ "SigType" SG_ 2147548634 Joystick3Button1PressedStatus "DISCRETE";
BA_ "SPN" SG_ 2147548634 Joystick3Button1PressedStatus 2759;
BA_ "SigType" SG_ 2147548634 Joystick3Button2PressedStatus "DISCRETE";
BA_ "SPN" SG_ 2147548634 Joystick3Button2PressedStatus 2760;
BA_ "SigType" SG_ 2147548634 Joystick3Button3PressedStatus "DISCRETE";
BA_ "SPN" SG_ 2147548634 Joystick3Button3PressedStatus 2761;
BA_ "SigType" SG_ 2147548634 Joystick3Button4PressedStatus "DISCRETE";
BA_ "SPN" SG_ 2147548634 Joystick3Button4PressedStatus 2762;
BA_ "SigType" SG_ 2147548632 Joystick2XAxisDetentPosStatus "DISCRETE";
BA_ "SPN" SG_ 2147548632 Joystick2XAxisDetentPosStatus 2717;
BA_ "SigType" SG_ 2147548632 Joystick2YAxisDetentPosStatus "DISCRETE";
BA_ "SPN" SG_ 2147548632 Joystick2YAxisDetentPosStatus 2718;
BA_ "SigType" SG_ 2147548632 Joystick2YAxisPos "RANGE";
BA_ "SPN" SG_ 2147548632 Joystick2YAxisPos 2698;
BA_ "SigType" SG_ 2147548632 Jystck2YAxsLvrFrwrdPstvPsStatus "DISCRETE";
BA_ "SPN" SG_ 2147548632 Jystck2YAxsLvrFrwrdPstvPsStatus 2703;
BA_ "SigType" SG_ 2147548632 Jystck2YAxsLvrBckNgtvePosStatus "DISCRETE";
BA_ "SPN" SG_ 2147548632 Jystck2YAxsLvrBckNgtvePosStatus 2708;
BA_ "SigType" SG_ 2147548632 Joystick2YAxisNeutralPosStatus "DISCRETE";
BA_ "SPN" SG_ 2147548632 Joystick2YAxisNeutralPosStatus 2713;
BA_ "SigType" SG_ 2147548632 Joystick2XAxisPos "RANGE";
BA_ "SPN" SG_ 2147548632 Joystick2XAxisPos 2697;
BA_ "SigType" SG_ 2147548632 Jystck2XAxsLvrRghtPstvPosStatus "DISCRETE";
BA_ "SPN" SG_ 2147548632 Jystck2XAxsLvrRghtPstvPosStatus 2702;
BA_ "SigType" SG_ 2147548632 Jystck2XAxsLvrLftNgtvePosStatus "DISCRETE";
BA_ "SPN" SG_ 2147548632 Jystck2XAxsLvrLftNgtvePosStatus 2707;
BA_ "SigType" SG_ 2147548632 Joystick2XAxisNeutralPosStatus "DISCRETE";
BA_ "SPN" SG_ 2147548632 Joystick2XAxisNeutralPosStatus 2712;
BA_ "SigType" SG_ 2147548632 Joystick2Button9PressedStatus "DISCRETE";
BA_ "SPN" SG_ 2147548632 Joystick2Button9PressedStatus 2730;
BA_ "SigType" SG_ 2147548632 Joystick2Button10PressedStatus "DISCRETE";
BA_ "SPN" SG_ 2147548632 Joystick2Button10PressedStatus 2731;
BA_ "SigType" SG_ 2147548632 Joystick2Button11PressedStatus "DISCRETE";
BA_ "SPN" SG_ 2147548632 Joystick2Button11PressedStatus 2732;
BA_ "SigType" SG_ 2147548632 Joystick2Button12PressedStatus "DISCRETE";
BA_ "SPN" SG_ 2147548632 Joystick2Button12PressedStatus 2733;
BA_ "SigType" SG_ 2147548632 Joystick2Button5PressedStatus "DISCRETE";
BA_ "SPN" SG_ 2147548632 Joystick2Button5PressedStatus 2726;
BA_ "SigType" SG_ 2147548632 Joystick2Button6PressedStatus "DISCRETE";
BA_ "SPN" SG_ 2147548632 Joystick2Button6PressedStatus 2727;
BA_ "SigType" SG_ 2147548632 Joystick2Button7PressedStatus "DISCRETE";
BA_ "SPN" SG_ 2147548632 Joystick2Button7PressedStatus 2728;
BA_ "SigType" SG_ 2147548632 Joystick2Button8PressedStatus "DISCRETE";
BA_ "SPN" SG_ 2147548632 Joystick2Button8PressedStatus 2729;
BA_ "SigType" SG_ 2147548632 Joystick2Button1PressedStatus "DISCRETE";
BA_ "SPN" SG_ 2147548632 Joystick2Button1PressedStatus 2722;
BA_ "SigType" SG_ 2147548632 Joystick2Button2PressedStatus "DISCRETE";
BA_ "SPN" SG_ 2147548632 Joystick2Button2PressedStatus 2723;
BA_ "SigType" SG_ 2147548632 Joystick2Button3PressedStatus "DISCRETE";
BA_ "SPN" SG_ 2147548632 Joystick2Button3PressedStatus 2724;
BA_ "SigType" SG_ 2147548632 Joystick2Button4PressedStatus "DISCRETE";
BA_ "SPN" SG_ 2147548632 Joystick2Button4PressedStatus 2725;
VAL_ 2147548636 SlowVesselModeStatus 3 "TakeNoAction" 2 "Reserved" 1 "SlowVesselModeIsACTIVE" 0 "SlowVesselModeIsOFF" ;
VAL_ 2147548636 TrollingModeStatus 3 "TakeNoAction" 2 "Reserved" 1 "TrollingModeIsACTIVE" 0 "TrollingModeIsOFF" ;
VAL_ 2147548636 EngThrttlSynchrnztionModeStatus 15 "TakeNoAction" 5 "1110Reserved" 4 "SynchronizedMaster" 3 "SynchronizedStarboard" 2 "SynchronizedPort" 1 "SynchronizedCenter" 0 "NotSynchronized" ;
VAL_ 2147548790 DisplayDeadbands 15 "NotAvailable" 3 "1110Reserved" 2 "Wide_24mm" 1 "Standard_12mm" 0 "Narrow_45mm" ;
VAL_ 2147548790 LEDPatternCtrl 15 "NotAvailable" 3 "1110Reserved" 2 "7Channel" 1 "Offset" 0 "5Channel" ;
VAL_ 2147548790 LEDDisplayDeadbandCtrl 15 "NotAvailableNotApplicable" 5 "1110Reserved" 4 "_1Mm" 3 "_5Mm" 2 "_24Mm" 1 "_12Mm" 0 "_45Mm" ;
VAL_ 2147548790 LEDDisplayModeCtrl 15 "NotAvailableNotApplicable" 3 "1110Reserved" 2 "CenterOnGradeDisplayMode2" 1 "OffsetOnGradeDisplayMode" 0 "CenterOnGradeDisplayMode1" ;
VAL_ 2147548790 LEDDisplayData1 32 "LowCoarseLEDOn" 16 "LowFineLEDOn" 8 "OngradeLEDOn" 4 "HighFineLEDOn" 2 "HighCoarseLEDOn" ;
VAL_ 2147548789 LaserReceiverType 1 "LinearLaserReceiver" 0 "Reserved" ;
VAL_ 2147548785 LaserTracerInformation 32 "Curb" 16 "Stringline" 8 "PreviousPass" 4 "ValidTarget" 2 "LaserIsReady" 1 "LaserPowerIsOn" ;
VAL_ 2147548785 LEDDisplayData2 64 "RightLEDOn" 32 "LeftLEDOn" 16 "DownLEDOn" 8 "UpLEDOn" 4 "OngradeCLEDOn" 2 "OngradeBLEDOn" 1 "OngradeALEDOn" ;
VAL_ 2147545101 BladeAutoModeCmd 15 "NotSupported" 14 "ErrorIndicator" 4 "AutoNotAllowed" 3 "SrvcMdAtAllwdOnlyDrngSrvceModes" 2 "SspndAtTmprarilySuspendAutoMode" 1 "ActvtyAllwsAtMstDtctOprtrBfrAtA" 0 "AutoAllowed" ;
VAL_ 2147545101 DesiredGradeOffsetSwitch 15 "NotInstalled" 14 "ErrorIndicator" 2 "DecrementButtonPressed" 0 "NoButtonPressed" 1 "SwtchSttCnBRdInTwWysOnMthdUssTh" ;
VAL_ 2147545101 BladeCtrlModeSwitch 15 "NotInstalled" 14 "ErrorIndicator" 3 "AutomaticButtonPressed" 2 "ManualButtonPressed" 0 "NoButtonPressed" 1 "SwtchSttCnBRdInTwWysOnMthdUssTh" ;
VAL_ 2147548639 FrontWheelDriveActuatorStatus 3 "NotAvailable" 2 "Error" 1 "FrontWheelDriveActuatorEngaged" 0 "FrntWhelDriveActuatorNotEngaged" ;
VAL_ 2147548625 FMSstandardRqsSupported 3 "DontCare" 2 "Reserved" 1 "OnRqModeIsSupported" 0 "OnRqModeIsNotSupported" ;
VAL_ 2147548625 FMSstandardDiagnosticsSupported 3 "DontCare" 2 "Reserved" 1 "DiagnosticsIsSupported" 0 "DiagnosticsIsNotSupported" ;
VAL_ 2147548763 LnDprtureIndicationEnableStatus 3 "NotUsed" 2 "Reserved" 1 "LaneDepartureIndicationEnabled" 0 "LaneDepartureIndicationDisabled" ;
VAL_ 2147548763 LaneTrackingStatusLeftSide 3 "DontCare_TakeNoAction" 2 "Reserved" 1 "TrackingLeftSide" 0 "NotTrackingLeftSide" ;
VAL_ 2147548763 LaneTrackingStatusRightSide 3 "DontCare_TakeNoAction" 2 "Reserved" 1 "TrackingRightSide" 0 "NotTrackingRightSide" ;
VAL_ 2147545095 LaneDepartureImminentLeftSide 3 "NotUsed" 2 "Reserved" 1 "Imminent" 0 "NotImminent" ;
VAL_ 2147545095 LaneDepartureImminentRightSide 3 "NotUsed" 2 "Reserved" 1 "Imminent" 0 "NotImminent" ;
VAL_ 2147548817 EngFuelLeakage2 1 "LeakageDetected" 0 "NoLeakageDetected" ;
VAL_ 2147548817 EngFuelLeakage1 0 "NoLeakageDetected" 1 "LeakageDetected" ;
VAL_ 2147548861 FanDriveState 15 "NotAvailable" 14 "Other" 13 "EngBrake" 12 "Timer" 11 "A_CSystem" 10 "TransRetarder" 9 "ManualCtrl" 8 "NotDefined" 7 "DefaultOperation" 6 "ExcessiveHydOilTemp" 5 "ExcessiveTransOilTemp" 4 "ExcessiveEngCoolantTemp" 3 "ExcessiveEngOilTemp" 2 "ExcessiveEngAirTemp" 1 "EngSystemGeneral" 0 "FanOff" ;
VAL_ 2147548816 EngTorqueLimitFeature 7 "NotAvailable" 5 "110Reserved" 4 "CurrentTorqueRating" 3 "PreviousTorqueRating" 2 "FirstTorqueRating" 1 "HighestTorqueRating" 0 "Reserved" ;
VAL_ 2147548816 TorqueLimitingFeatureStatus 1 "Enabled" 0 "Disabled" ;
VAL_ 2147548746 TransMode1Indicator 3 "NotAvailable" 2 "Error" 1 "TransMode1Active" 0 "TransMode1NotActive" ;
VAL_ 2147548746 TransMode2Indicator 3 "NotAvailable" 2 "Error" 1 "TransMode2Active" 0 "TransMode2NotActive" ;
VAL_ 2147548746 TransMode3Indicator 3 "NotAvailable" 2 "Error" 1 "TransMode3Active" 0 "TransMode3NotActive" ;
VAL_ 2147548746 TransMode4Indicator 3 "NotAvailable" 2 "Error" 1 "TransMode4Active" 0 "TransMode4NotActive" ;
VAL_ 2147548746 TransShiftInhibitIndicator 3 "TakeNoAction" 2 "Reserved" 1 "ActiveShiftIsInhibited" 0 "InactiveShiftIsNotInhibited" ;
VAL_ 2147548746 TransEngCrankEnable 3 "NotAvailable" 2 "Error" 1 "CrnkngEnbldEngCrnkngIsAllwdByTr" 0 "CrnkngDsbldEngCrnkngIsPrhbtdByT" ;
VAL_ 2147548746 ActiveShiftConsoleIndicator 3 "NotAvailable" 2 "Reserved" 1 "SecondShiftConsoleIsActive" 0 "PrimaryShiftConsoleIsActive" ;
VAL_ 2147548746 TransReadyForBrakeRelease 3 "DontCare" 2 "Reserved" 1 "TransReadyForBrakeRelease" 0 "TransNotReadyForBrakeRelease" ;
VAL_ 2147548746 TransRqedRangeDisplayFlashState 3 "TakeNoAction" 2 "Reserved" 1 "ActvTrnsRqdRngDsplyShldBFlshing" 0 "InctvTrnsRqdRngDsplyShldNtBFlsh" ;
VAL_ 2147548746 TransRqedRangeDisplayBlankState 3 "TakeNoAction" 2 "Reserved" 1 "ActvTrnsRqdRngDsplyShldBBlanked" 0 "InctvTrnsRqdRngDsplyShldNtBBlnk" ;
VAL_ 2147548867 TransForwardDirectionSwitch 1 "On" 0 "Off" ;
VAL_ 2147548867 TransNeutralSwitch 1 "On" 0 "Off" ;
VAL_ 2147548867 TransReverseDirectionSwitch 1 "On" 0 "Off" ;
VAL_ 2147548867 TransLowRangeSenseSwitch 1 "On" 0 "Off" ;
VAL_ 2147548867 TransHighRangeSenseSwitch 1 "On" 0 "Off" ;
VAL_ 2147548871 TransInertiaBrakeActuator 1 "On" 0 "Off" ;
VAL_ 2147548871 TransDefuelActuator 1 "On" 0 "Off" ;
VAL_ 2147548871 TransLockupClutchActuator 1 "On" 0 "Off" ;
VAL_ 2147548871 TransClutchActuator 1 "On" 0 "Off" ;
VAL_ 2147548871 TransSplitterIndirectActuator 1 "On" 0 "Off" ;
VAL_ 2147548871 TransSplitterDirectActuator 1 "On" 0 "Off" ;
VAL_ 2147548871 TransRangeLowActuator 1 "On" 0 "Off" ;
VAL_ 2147548871 TransRangeHighActuator 1 "On" 0 "Off" ;
VAL_ 2147548871 TransShiftFingerGearActuator2 1 "On" 0 "Off" ;
VAL_ 2147548871 TransShiftFingerRailActuator2 1 "On" 0 "Off" ;
VAL_ 2147548871 TransShiftFingerGearActuator1 1 "On" 0 "Off" ;
VAL_ 2147548871 TransShiftFingerRailActuator1 1 "On" 0 "Off" ;
VAL_ 2147548871 TrnsShftFngrCenterRailIndicator 1 "On" 0 "Off" ;
VAL_ 2147548871 TrnsShftFngrEngagementIndicator 1 "On" 0 "Off" ;
VAL_ 2147548871 TrnsShiftFingerNeutralIndicator 1 "On" 0 "Off" ;
VAL_ 2147545090 ProgressiveShiftDisable 3 "TakeNoAction" 1 "ProgressiveShiftIsDisabled" 0 "ProgressiveShiftIsNotDisabled" ;
VAL_ 2147545090 EngMomentaryOverspeedEnable 3 "TakeNoAction" 1 "MomentaryEngOverspeedIsEnabled" 0 "MomentaryEngOverspeedIsDisabled" ;
VAL_ 2147545090 TransShiftInProcess 1 "ShiftInProcess" 0 "ShiftIsNotInProcess" ;
VAL_ 2147545090 TorqueConverterLockupEngaged 1 "TorqueConverterLockupEngaged" 0 "TorqueConverterLockupDisengaged" ;
VAL_ 2147545090 TransDrivelineEngaged 3 "NotAvailable" 2 "Error" 1 "DrivelineEngaged" 0 "DrivelineDisengaged" ;
VAL_ 2147545099 SterableLiftAxleLoweringInhibit 3 "NotAvailable" 2 "Reserved" 1 "LoweringInhibited" 0 "LoweringAllowed" ;
VAL_ 2147545099 TypeOfSteerTrans 15 "NotAvailable" 4 "1110ReservedForSAEAssignment" 3 "HybrdStrTrnsAStrngTrnsmssnInWhc" 2 "PrlyElctrcStrTrnsAStrngTrnsmssn" 1 "PrlyHydStrTrnsAStrngTrnsmssnInW" 0 "PrlyMchStrTrnsAStrngTrnsmssnInW" ;
VAL_ 2147545099 TypeOfSteerForces 15 "NotAvailable" 4 "1110ReservedForSAEAssignment" 3 "SlfTrckngStrEqpmntASystmDsgndTC" 2 "FllPwrStrEqpmntStrngFrcsArPrvdd" 1 "PwrAssstdStrEqpmntStrngFrcsRslt" 0 "MnlStrEqpmntStrngFrcsRsltSllyFr" ;
VAL_ 2147545099 SteerType 15 "NotAvailable" 2 "1110ReservedForAssignmentBySAE" 1 "AxStrEqpmntASystmInWhchWhlsOnAx" 0 "MnStrSystmStrngEqpmntOfAVhclWhc" ;
VAL_ 2147545099 StatusOfSteerAxle 15 "NotAvailable" 6 "1110ReservedForSAEAssignment" 5 "AxleSteerInSpecialMode" 4 "AxleNotActiveBecauseOfAnError" 3 "AxleCenteredBecauseOfAnError" 2 "AxleCentered" 1 "AxleSteerActive" 0 "AxleSteerNotActive" ;
VAL_ 2147548866 TransOutputRetarder 1 "On" 0 "Off" ;
VAL_ 2147545088 EngCoolantLoadIncrease 1 "CoolantLoadIncreasePossible" 0 "NoCoolantLoadIncrease" ;
VAL_ 2147545088 RetarderEnableShiftAssistSwitch 1 "RetarderShiftAssistEnabled" 0 "RetarderShiftAssistDisabled" ;
VAL_ 2147545088 RetarderEnableBrakeAssistSwitch 1 "RetarderBrakeAssistEnabled" 0 "RetarderBrakeAssistDisabled" ;
VAL_ 2147548841 EngExhstGsOxygnSnsrClsdLpOprton 3 "DontCare_TakeNoAction" 2 "Reserved" 1 "CmdToEnableFunction" 0 "CmdToDisableFunction" ;
VAL_ 2147548635 Jystck3GripXAxisDetentPosStatus 3 "NotAvailable" 2 "ErrorIndicator" 1 "InDetentPos" 0 "NotInDetentPos" ;
VAL_ 2147548635 Jystck3GripYAxisDetentPosStatus 3 "NotAvailable" 2 "ErrorIndicator" 1 "InDetentPos" 0 "NotInDetentPos" ;
VAL_ 2147548635 Jystck3ThetaAxisDetentPosStatus 3 "NotAvailable" 2 "ErrorIndicator" 1 "InDetentPos" 0 "NotInDetentPos" ;
VAL_ 2147548635 Jystck3ThtAxsClckwsPstvPsStatus 3 "NotAvailable" 2 "ErrorIndicator" 1 "OnPositiveSideOfNeutral" 0 "NotOnPositiveSideOfNeutral" ;
VAL_ 2147548635 Jystck3ThtAxsCntrClckwsNgtvPsStt 3 "NotAvailable" 2 "ErrorIndicator" 1 "OnNegativeSideOfNeutral" 0 "NotOnNegativeSideOfNeutral" ;
VAL_ 2147548635 Jystck3ThtaAxisNeutralPosStatus 3 "NotAvailable" 2 "ErrorIndicator" 1 "InNeutralPos" 0 "NotInNeutralPos" ;
VAL_ 2147548635 Jystck3GrpYAxsLvrFrwrdPstvPsStts 3 "NotAvailable" 2 "ErrorIndicator" 1 "OnPositiveSideOfNeutral" 0 "NotOnPositiveSideOfNeutral" ;
VAL_ 2147548635 Jystck3GrpYAxsLvrBckNgtvPsSttus 3 "NotAvailable" 2 "ErrorIndicator" 1 "OnNegativeSideOfNeutral" 0 "NotOnNegativeSideOfNeutral" ;
VAL_ 2147548635 Jystck3GrpYAxisNeutralPosStatus 3 "NotAvailable" 2 "ErrorIndicator" 1 "InNeutralPos" 0 "NotInNeutralPos" ;
VAL_ 2147548635 Jystck3GrpXAxsLvrRghtPstvPsStts 3 "NotAvailable" 2 "ErrorIndicator" 1 "OnPositiveSideOfNeutral" 0 "NotOnPositiveSideOfNeutral" ;
VAL_ 2147548635 Jystck3GrpXAxsLvrLftNgtvPsSttus 3 "NotAvailable" 2 "ErrorIndicator" 1 "OnNegativeSideOfNeutral" 0 "NotOnNegativeSideOfNeutral" ;
VAL_ 2147548635 Jystck3GrpXAxisNeutralPosStatus 3 "NotAvailable" 2 "ErrorIndicator" 1 "OnNegativeSideOfNeutral" 0 "NotOnNegativeSideOfNeutral" ;
VAL_ 2147548633 Jystck2GripXAxisDetentPosStatus 3 "NotAvailable" 2 "ErrorIndicator" 1 "InDetentPos" 0 "NotInDetentPos" ;
VAL_ 2147548633 Jystck2GripYAxisDetentPosStatus 3 "NotAvailable" 2 "ErrorIndicator" 1 "InDetentPos" 0 "NotInDetentPos" ;
VAL_ 2147548633 Jystck2ThetaAxisDetentPosStatus 3 "NotAvailable" 2 "ErrorIndicator" 1 "InDetentPos" 0 "NotInDetentPos" ;
VAL_ 2147548633 Jystck2ThtAxsClckwsPstvPsStatus 3 "NotAvailable" 2 "ErrorIndicator" 1 "OnPositiveSideOfNeutral" 0 "NotOnPositiveSideOfNeutral" ;
VAL_ 2147548633 Jystck2ThtAxsCntrClckwsNgtvPsStt 3 "NotAvailable" 2 "ErrorIndicator" 1 "OnNegativeSideOfNeutral" 0 "NotOnNegativeSideOfNeutral" ;
VAL_ 2147548633 Jystck2ThtaAxisNeutralPosStatus 3 "NotAvailable" 2 "ErrorIndicator" 1 "InNeutralPos" 0 "NotInNeutralPos" ;
VAL_ 2147548633 Jystck2GrpYAxsLvrFrwrdPstvPsStts 3 "NotAvailable" 2 "ErrorIndicator" 1 "OnPositiveSideOfNeutral" 0 "NotOnPositiveSideOfNeutral" ;
VAL_ 2147548633 Jystck2GrpYAxsLvrBckNgtvPsSttus 3 "NotAvailable" 2 "ErrorIndicator" 1 "OnNegativeSideOfNeutral" 0 "NotOnNegativeSideOfNeutral" ;
VAL_ 2147548633 Jystck2GrpYAxisNeutralPosStatus 3 "NotAvailable" 2 "ErrorIndicator" 1 "InNeutralPos" 0 "NotInNeutralPos" ;
VAL_ 2147548633 Jystck2GrpXAxsLvrRghtPstvPsStts 3 "NotAvailable" 2 "ErrorIndicator" 1 "OnPositiveSideOfNeutral" 0 "NotOnPositiveSideOfNeutral" ;
VAL_ 2147548633 Jystck2GrpXAxsLvrLftNgtvPsSttus 3 "NotAvailable" 2 "ErrorIndicator" 1 "OnNegativeSideOfNeutral" 0 "NotOnNegativeSideOfNeutral" ;
VAL_ 2147548633 Jystck2GrpXAxisNeutralPosStatus 3 "NotAvailable" 2 "ErrorIndicator" 1 "OnNegativeSideOfNeutral" 0 "NotOnNegativeSideOfNeutral" ;
VAL_ 2147548631 Jystck1GripXAxisDetentPosStatus 3 "NotAvailable" 2 "ErrorIndicator" 1 "InDetentPos" 0 "NotInDetentPos" ;
VAL_ 2147548631 Jystck1GripYAxisDetentPosStatus 3 "NotAvailable" 2 "ErrorIndicator" 1 "InDetentPos" 0 "NotInDetentPos" ;
VAL_ 2147548631 Jystck1ThetaAxisDetentPosStatus 3 "NotAvailable" 2 "ErrorIndicator" 1 "InDetentPos" 0 "NotInDetentPos" ;
VAL_ 2147548631 Jystck1ThtAxsClckwsPstvPsStatus 3 "NotAvailable" 2 "ErrorIndicator" 1 "OnPositiveSideOfNeutral" 0 "NotOnPositiveSideOfNeutral" ;
VAL_ 2147548631 Jystck1ThtAxsCntrClckwsNgtvPsStt 3 "NotAvailable" 2 "ErrorIndicator" 1 "OnNegativeSideOfNeutral" 0 "NotOnNegativeSideOfNeutral" ;
VAL_ 2147548631 Jystck1ThtaAxisNeutralPosStatus 3 "NotAvailable" 2 "ErrorIndicator" 1 "InNeutralPos" 0 "NotInNeutralPos" ;
VAL_ 2147548631 Jystck1GrpYAxsLvrFrwrdPstvPsStts 3 "NotAvailable" 2 "ErrorIndicator" 1 "OnPositiveSideOfNeutral" 0 "NotOnPositiveSideOfNeutral" ;
VAL_ 2147548631 Jystck1GrpYAxsLvrBckNgtvPsSttus 3 "NotAvailable" 2 "ErrorIndicator" 1 "OnNegativeSideOfNeutral" 0 "NotOnNegativeSideOfNeutral" ;
VAL_ 2147548631 Jystck1GrpYAxisNeutralPosStatus 3 "NotAvailable" 2 "ErrorIndicator" 1 "InNeutralPos" 0 "NotInNeutralPos" ;
VAL_ 2147548631 Jystck1GrpXAxsLvrRghtPstvPsStts 3 "NotAvailable" 2 "ErrorIndicator" 1 "OnPositiveSideOfNeutral" 0 "NotOnPositiveSideOfNeutral" ;
VAL_ 2147548631 Jystck1GrpXAxsLvrLftNgtvPsSttus 3 "NotAvailable" 2 "ErrorIndicator" 1 "OnNegativeSideOfNeutral" 0 "NotOnNegativeSideOfNeutral" ;
VAL_ 2147548631 Jystck1GrpXAxisNeutralPosStatus 3 "NotAvailable" 2 "ErrorIndicator" 1 "InNeutralPos" 0 "NotInNeutralPos" ;
VAL_ 2147548819 TurningGearEngaged 1 "TurningGearIsEngaged" 0 "TurningGearIsNotEngaged" ;
VAL_ 2147548819 SafetyWireStatus 1 "SafetyWireHasBeenActivated" 0 "SafetyWireHasNotBeenActivated" ;
VAL_ 2147548629 EngVrblGmtryTrbArCtrlShtffValve 3 "NotAvailable" 2 "Reserved" 1 "VGTAirCtrlShutoffValveIsOn" 0 "VGTAirCtrlShutoffValveIsOff" ;
VAL_ 2147545091 VhclAccelerationRateLimitStatus 3 "NotAvailable" 2 "Reserved" 1 "LimitActive" 0 "LimitNotActive" ;
VAL_ 2147545091 AccelPedal2LowIdleSwitch 3 "NotAvailable" 2 "Error" 1 "AccelPedal2InLowIdleCondition" 0 "AcclPedal2NotInLowIdleCondition" ;
VAL_ 2147545091 RoadSpeedLimitStatus 1 "NotActive" 0 "Active" ;
VAL_ 2147545091 AccelPedalKickdownSwitch 3 "NotAvailable" 2 "Error" 1 "KickdownActive" 0 "KickdownPassive" ;
VAL_ 2147545091 AccelPedal1LowIdleSwitch 2 "Error" 1 "AccelPedal1InLowIdleCondition" 0 "AcclPedal1NotInLowIdleCondition" ;
VAL_ 2147545091 AccelPedalPos1 1 "SPN558" ;
VAL_ 2147545092 EngStarterMode 15 "notAvailable" 14 "error" 12 "starterInhibitedReasonUnknown" 9 "1011Reserved" 8 "strtrInhbtdDueToStarterOvertemp" 7 "strtrInhbtdDToActiveImmobilizer" 6 "strtrInhbtdDTDrvlnEnggdOthrTrns" 5 "strtrInhbtdDTEngNtReadyForStart" 4 "strtrInhbtdDToEngAlreadyRunning" 3 "strtFnshdStrtrNtActvAftrHvngBnA" 2 "starterActiveGearEngaged" 1 "starterActiveGearNotEngaged" 0 "startNotRqed" ;
VAL_ 2147548899 EngSpeedAtPoint2 1 "nd3Pnt2IsDfndAsKcknPntFrmWhchTr" ;
VAL_ 2147548612 XBRActiveCtrlMode 15 "NotAvailable" 4 "1110ReservedForSAEAssignment" 3 "MxMdOfXBRAcclrtnCtrlBngExecuted" 2 "AddtnMdOfXBRAcclrtnCtrlBngExctd" 1 "DrvrsBrkDmndBngExctdNExtlBrkDmn" 0 "NoBrakeDemandBeingExecuted" ;
VAL_ 2147548612 XBRSystemState 3 "NotAvailable" 2 "NoExtlBrakeDemandWillBeAccepted" 1 "OnlyExtlBrkDmndOfHghstXBRPrrtyW" 0 "AnyExtlBrkeDemandWillBeAccepted" ;
VAL_ 2147548612 FoundationBrakeUse 3 "NotAvailable" 2 "Reserved" 1 "FoundationBrakesInUse" 0 "FoundationBrakesNotInUse" ;
VAL_ 2147548612 HillHolderMode 7 "NotAvailable" 6 "Reserved" 3 "101NotDefined" 2 "ActvBtWllChngTInctvInAShortTime" 1 "Active" 0 "Inactive" ;
VAL_ 2147548612 HaltBrakeMode 7 "NotAvailable" 6 "Reserved" 3 "101NotDefined" 2 "ActiveButNotFunctioningProperly" 1 "Active" 0 "Inactive" ;
VAL_ 2147545089 TrctrMntdTrilerABSWarningSignal 3 "TakeNoAction" 2 "Reserved" 1 "On" 0 "Off" ;
VAL_ 2147545089 TrailerABSStatus 3 "TrlrABSSttsInfrmtnNtAvlblPrmtrN" 2 "Reserved" 1 "TrailerABSActive" 0 "TrlrABSSttsInfrmtnAvlblBtNtActv" ;
VAL_ 2147545089 HaltBrakeSwitch 3 "NotAvailable" 2 "Error" 1 "HaltBrakeSwitchActive" 0 "HaltBrakeSwitchPassive" ;
VAL_ 2147545089 ATC_ASRInformationSignal 3 "TakeNoAction" 2 "Reserved" 1 "On" 0 "Off" ;
VAL_ 2147545089 ABS_EBSAmberWarningSignal 3 "TakeNoAction" 2 "Reserved" 1 "On" 0 "Off" ;
VAL_ 2147545089 EBSRedWarningSignal 3 "TakeNoAction" 2 "Reserved" 1 "On" 0 "Off" ;
VAL_ 2147545089 ABSFullyOperational 3 "NotAvailable" 2 "Reserved" 1 "FullyOperational" 0 "NotFullyOperational" ;
VAL_ 2147545089 RemoteAccelEnableSwitch 3 "NotAvailable" 2 "Error" 1 "On" 0 "Off" ;
VAL_ 2147545089 EngAuxEngShutdownSwitch 3 "NotAvailable" 2 "Error" 1 "On" 0 "Off" ;
VAL_ 2147545089 EngDerateSwitch 3 "NotAvailable" 2 "Error" 1 "On" 0 "Off" ;
VAL_ 2147545089 AccelInterlockSwitch 3 "NotAvailable" 2 "Error" 1 "On" 0 "Off" ;
VAL_ 2147545089 TractionCtrlOverrideSwitch 3 "NotAvailableNotInstalled" 2 "Error" 1 "On" 0 "Off" ;
VAL_ 2147545089 ASRHillHolderSwitch 3 "NotAvailable" 2 "Error" 1 "ASRHillHolderSwitchActive" 0 "ASRHillHolderSwitchPassive" ;
VAL_ 2147545089 ASROffroadSwitch 2 "Error" 1 "ASROffroadSwitchActive" 0 "ASROffroadSwitchPassive" 3 "NotAvailable" ;
VAL_ 2147545089 ABSOffroadSwitch 3 "NotAvailable" 2 "Error" 1 "ABSOffroadSwitchActive" 0 "ABSOffroadSwitchPassive" ;
VAL_ 2147545089 EBSBrakeSwitch 3 "NotAvailable" 2 "Error" 1 "BrakePedalIsBeingPressed" 0 "BrakePedalIsNotBeingPressed" ;
VAL_ 2147545089 AntiLockBrakingActive 3 "NotAvailable" 2 "Reserved" 1 "ABSActive" 0 "ABSPassiveButInstalled" ;
VAL_ 2147545089 ASRBrakeCtrlActive 3 "NotAvailable" 2 "Reserved" 1 "ASRBrakeCtrlActive" 0 "ASRBrakeCtrlPassiveButInstalled" ;
VAL_ 2147545089 ASREngCtrlActive 3 "NotAvailable" 2 "Reserved" 1 "ASREngCtrlActive" 0 "ASREngCtrlPassiveButInstalled" ;
VAL_ 2147545094 DiffLockStateCentralRear 1 "DiffLockEngaged" 0 "DiffLockDisengaged" ;
VAL_ 2147545094 DiffLockStateCentralFront 1 "DiffLockEngaged" 0 "DiffLockDisengaged" ;
VAL_ 2147545094 DiffLockStateCentral 1 "DiffLockEngaged" 0 "DiffLockDisengaged" ;
VAL_ 2147545094 DiffLockStateRearAxle2 1 "DiffLockEngaged" 0 "DiffLockDisengaged" ;
VAL_ 2147545094 DiffLockStateRearAxle1 1 "DiffLockEngaged" 0 "DiffLockDisengaged" ;
VAL_ 2147545094 DiffLockStateFrontAxle2 1 "DiffLockEngaged" 0 "DiffLockDisengaged" ;
VAL_ 2147545094 DiffLockStateFrontAxle1 1 "DiffLockEngaged" 0 "DiffLockDisengaged" ;
VAL_ 2147548750 Ramp_WheelChairLiftPos 3 "NotAvailable" 2 "Error" 1 "OutsideBus" 0 "InsideBus" ;
VAL_ 2147548750 PosOfDoors 15 "NotAvailable" 14 "Error" 3 "1101NotDefined" 2 "AllDoorsClosed" 1 "ClosingLastDoor" 0 "AtLeast1DoorIsOpen" ;
VAL_ 2147548614 EngStartEnableDevice2Config 15 "NotAvailable" 5 "1110Reserved" 4 "ElectricInletAirHeaterInstalled" 3 "EtherInjectionInstalled" 2 "FuelledStartInstalled" 1 "GlowPlugsInstalled" 0 "NoStartEnableDevice2Installed" ;
VAL_ 2147548614 EngStartEnableDevice1Config 15 "NotAvailable" 5 "1110Reserved" 4 "ElectricInletAirHeaterInstalled" 3 "EtherInjectionInstalled" 2 "FuelledStartInstalled" 1 "GlowPlugsInstalled" 0 "NoStartEnableDevice1Installed" ;
VAL_ 2147548614 EngStartEnableDevice2 2 "Reserved" 1 "StartEnableON" 0 "StartEnableOFF" ;
VAL_ 2147548614 EngStartEnableDevice1 3 "NotAvailible" 2 "Reserved" 1 "StartEnableON" 0 "StartEnableOFF" ;
VAL_ 2147548628 TransferCaseSelectorSwitch 7 "NotAvailable" 6 "ErrorIndicator" 3 "101ReservedForSAEAssignment" 2 "Neutral" 1 "Wheel" ;
VAL_ 2147540992 RqCabZoneHeating 3 "DontCare_TakeNoAction" 2 "Reserved" 1 "HeatCabZone" 0 "DoNotCabEngZone" ;
VAL_ 2147540992 RqEngZoneHeating 3 "DontCare_TakeNoAction" 2 "Reserved" 1 "HeatEngZone" 0 "DoNotHeatEngZone" ;
VAL_ 2147540992 AuxHeaterModeRq 15 "DontCare_TakeNoAction" 14 "Reserved" 4 "1101NotDefined" 3 "NormalMode" 2 "EconomyMode" 1 "OffDTADRPrErpnRgltnsFrTrnsprtOf" 0 "DeactivateAuxHeater" ;
VAL_ 2147540992 SeatBeltSwitch 3 "NotAvailable" 2 "ErrrSwtchStteCannotBeDetermined" 1 "OKSeatBeltIsBuckled" 0 "NOTBuckled" ;
VAL_ 2147540992 OperatorSeatDirectionSwitch 3 "NotAvailable" 2 "Error" 1 "OperatorSeatIsFacingForward" 0 "OperatorSeatNotFacingForward" ;
VAL_ 2147540992 BatteryMainSwitchHoldRq 3 "DontCare_TakeNoAction" 2 "undefined" 1 "HoldBatteryMainSwitch" 0 "ReleaseBatteryMainSwitch" ;
VAL_ 2147540992 AuxHeaterCoolantPumpRq 3 "DontCare_TakeNoAction" 2 "Reserved" 1 "ActivateWaterPump" 0 "DeactivateWaterPump" ;
VAL_ 2147548913 EngShutdownOverrideSwitch 1 "On" 0 "Off" ;
VAL_ 2147548913 EngTestModeSwitch 1 "On" 0 "Off" ;
VAL_ 2147548913 EngIdleDecrementSwitch 1 "On" 0 "Off" ;
VAL_ 2147548913 EngIdleIncrementSwitch 1 "On" 0 "Off" ;
VAL_ 2147548913 CruiseCtrlAccelerateSwitch 1 "CrsCtrlActivatorInPosAccelerate" 0 "CrsCtrlActvtrNotInPosAccelerate" ;
VAL_ 2147548913 CruiseCtrlResumeSwitch 1 "CruiseCtrlActivatorInPosResume" 0 "CrseCtrlActivatorNotInPosResume" ;
VAL_ 2147548913 CruiseCtrlCoastSwitch 1 "CruiseCtrlActivatorInPosCoast" 0 "CriseCtrlActivatorNotInPosCoast" ;
VAL_ 2147548913 CruiseCtrlSetSwitch 1 "CruiseCtrlActivatorInPosSet" 0 "CruiseCtrlActivatorNotInPosSet" ;
VAL_ 2147548913 ClutchSwitch 1 "ClutchPedalDepressed" 0 "ClutchPedalReleased" ;
VAL_ 2147548913 BrakeSwitch 3 "NotAvailable" 2 "Error" 1 "BrakePedalDepressed" 0 "BrakePedalReleased" ;
VAL_ 2147548913 CruiseCtrlEnableSwitch 1 "CruiseCtrlEnabled" 0 "CruiseCtrlDisabled" ;
VAL_ 2147548913 CruiseCtrlActive 1 "CruiseCtrlSwitchedOn" 0 "CruiseCtrlSwitchedOff" ;
VAL_ 2147548913 CruiseCtrlPauseSwitch 3 "TakeNoAction" 2 "ErrorIndicator" 1 "On" 0 "Off" ;
VAL_ 2147548913 ParkingBrakeSwitch 1 "ParkingBrakeSet" 0 "ParkingBrakeNotSet" ;
VAL_ 2147548913 TwoSpeedAxleSwitch 1 "HighSpeedRange" 0 "LowSpeedRange" ;
VAL_ 2147548774 BatteryMainSwitchHoldState 3 "DontCare_TakeNoAction" 2 "Reserved" 1 "BatteryMainSwitchHeld" 0 "BatteryMainSwitchNotHeld" ;
VAL_ 2147548634 Joystick3XAxisDetentPosStatus 3 "NotAvailable" 2 "ErrorIndicator" 1 "InDetentPos" 0 "NotInDetentPos" ;
VAL_ 2147548634 Joystick3Button9PressedStatus 3 "NotAvailable" 2 "ErrorIndicator" 1 "ButtonPressed" 0 "ButtonNotPressed" ;
VAL_ 2147548634 Joystick3Button10PressedStatus 3 "NotAvailable" 2 "ErrorIndicator" 1 "ButtonPressed" 0 "ButtonNotPressed" ;
VAL_ 2147548634 Joystick3Button11PressedStatus 3 "NotAvailable" 2 "ErrorIndicator" 1 "ButtonPressed" 0 "ButtonNotPressed" ;
VAL_ 2147548634 Joystick3Button12PressedStatus 3 "NotAvailable" 2 "ErrorIndicator" 1 "ButtonPressed" 0 "ButtonNotPressed" ;
VAL_ 2147548634 Joystick3YAxisDetentPosStatus 3 "NotAvailable" 2 "ErrorIndicator" 1 "InDetentPos" 0 "NotInDetentPos" ;
VAL_ 2147548634 Jystck3YAxsLvrFrwrdPstvPsStatus 3 "NotAvailable" 2 "ErrorIndicator" 1 "OnPositiveSideOfNeutral" 0 "NotOnPositiveSideOfNeutral" ;
VAL_ 2147548634 Jystck3YAxsLvrBckNgtvePosStatus 3 "NotAvailable" 2 "ErrorIndicator" 1 "OnNegativeSideOfNeutral" 0 "NotOnNegativeSideOfNeutral" ;
VAL_ 2147548634 Joystick3YAxisNeutralPosStatus 3 "NotAvailable" 2 "ErrorIndicator" 1 "InNeutralPos" 0 "NotInNeutralPos" ;
VAL_ 2147548634 Jystck3XAxsLvrRghtPstvPosStatus 3 "NotAvailable" 2 "ErrorIndicator" 1 "OnPositiveSideOfNeutral" 0 "NotOnPositiveSideOfNeutral" ;
VAL_ 2147548634 Jystck3XAxsLvrLftNgtvePosStatus 2 "ErrorIndicator" 1 "OnNegativeSideOfNeutral" 0 "NotOnNegativeSideOfNeutral" 3 "NotAvailable" ;
VAL_ 2147548634 Joystick3XAxisNeutralPosStatus 3 "NotAvailable" 2 "ErrorIndicator" 1 "InNeutralPos" 0 "NotInNeutralPos" ;
VAL_ 2147548634 Joystick3Button5PressedStatus 3 "NotAvailable" 2 "ErrorIndicator" 1 "ButtonPressed" 0 "ButtonNotPressed" ;
VAL_ 2147548634 Joystick3Button6PressedStatus 3 "NotAvailable" 2 "ErrorIndicator" 1 "ButtonPressed" 0 "ButtonNotPressed" ;
VAL_ 2147548634 Joystick3Button7PressedStatus 3 "NotAvailable" 2 "ErrorIndicator" 1 "ButtonPressed" 0 "ButtonNotPressed" ;
VAL_ 2147548634 Joystick3Button8PressedStatus 3 "NotAvailable" 2 "ErrorIndicator" 1 "ButtonPressed" 0 "ButtonNotPressed" ;
VAL_ 2147548634 Joystick3Button1PressedStatus 3 "NotAvailable" 2 "ErrorIndicator" 1 "ButtonPressed" 0 "ButtonNotPressed" ;
VAL_ 2147548634 Joystick3Button2PressedStatus 3 "NotAvailable" 2 "ErrorIndicator" 1 "ButtonPressed" 0 "ButtonNotPressed" ;
VAL_ 2147548634 Joystick3Button3PressedStatus 3 "NotAvailable" 2 "ErrorIndicator" 1 "ButtonPressed" 0 "ButtonNotPressed" ;
VAL_ 2147548634 Joystick3Button4PressedStatus 3 "NotAvailable" 2 "ErrorIndicator" 1 "ButtonPressed" 0 "ButtonNotPressed" ;
VAL_ 2147548632 Joystick2XAxisDetentPosStatus 3 "NotAvailable" 2 "ErrorIndicator" 1 "InDetentPos" 0 "NotInDetentPos" ;
VAL_ 2147548632 Joystick2YAxisDetentPosStatus 3 "NotAvailable" 2 "ErrorIndicator" 1 "InDetentPos" 0 "NotInDetentPos" ;
VAL_ 2147548632 Jystck2YAxsLvrFrwrdPstvPsStatus 3 "NotAvailable" 2 "ErrorIndicator" 1 "OnPositiveSideOfNeutral" 0 "NotOnPositiveSideOfNeutral" ;
VAL_ 2147548632 Jystck2YAxsLvrBckNgtvePosStatus 3 "NotAvailable" 2 "ErrorIndicator" 1 "OnNegativeSideOfNeutral" 0 "NotOnNegativeSideOfNeutral" ;
VAL_ 2147548632 Joystick2YAxisNeutralPosStatus 3 "NotAvailable" 2 "ErrorIndicator" 1 "InNeutralPos" 0 "NotInNeutralPos" ;
VAL_ 2147548632 Jystck2XAxsLvrRghtPstvPosStatus 3 "NotAvailable" 2 "ErrorIndicator" 1 "OnPositiveSideOfNeutral" 0 "NotOnPositiveSideOfNeutral" ;
VAL_ 2147548632 Jystck2XAxsLvrLftNgtvePosStatus 3 "NotAvailable" 2 "ErrorIndicator" 1 "OnNegativeSideOfNeutral" 0 "NotOnNegativeSideOfNeutral" ;
VAL_ 2147548632 Joystick2XAxisNeutralPosStatus 3 "NotAvailable" 2 "ErrorIndicator" 1 "InNeutralPos" 0 "NotInNeutralPos" ;
VAL_ 2147548632 Joystick2Button9PressedStatus 3 "NotAvailable" 2 "ErrorIndicator" 1 "ButtonPressed" 0 "ButtonNotPressed" ;
VAL_ 2147548632 Joystick2Button10PressedStatus 3 "NotAvailable" 2 "ErrorIndicator" 1 "ButtonPressed" 0 "ButtonNotPressed" ;
VAL_ 2147548632 Joystick2Button11PressedStatus 3 "NotAvailable" 2 "ErrorIndicator" 1 "ButtonPressed" 0 "ButtonNotPressed" ;
VAL_ 2147548632 Joystick2Button12PressedStatus 3 "NotAvailable" 2 "ErrorIndicator" 1 "ButtonPressed" 0 "ButtonNotPressed" ;
VAL_ 2147548632 Joystick2Button5PressedStatus 3 "NotAvailable" 2 "ErrorIndicator" 1 "ButtonPressed" 0 "ButtonNotPressed" ;
VAL_ 2147548632 Joystick2Button6PressedStatus 3 "NotAvailable" 2 "ErrorIndicator" 1 "ButtonPressed" 0 "ButtonNotPressed" ;
VAL_ 2147548632 Joystick2Button7PressedStatus 3 "NotAvailable" 2 "ErrorIndicator" 1 "ButtonPressed" 0 "ButtonNotPressed" ;
VAL_ 2147548632 Joystick2Button8PressedStatus 3 "NotAvailable" 2 "ErrorIndicator" 1 "ButtonPressed" 0 "ButtonNotPressed" ;
VAL_ 2147548632 Joystick2Button1PressedStatus 3 "NotAvailable" 2 "ErrorIndicator" 1 "ButtonPressed" 0 "ButtonNotPressed" ;
VAL_ 2147548632 Joystick2Button2PressedStatus 3 "NotAvailable" 2 "ErrorIndicator" 1 "ButtonPressed" 0 "ButtonNotPressed" ;
VAL_ 2147548632 Joystick2Button3PressedStatus 3 "NotAvailable" 2 "ErrorIndicator" 1 "ButtonPressed" 0 "ButtonNotPressed" ;
VAL_ 2147548632 Joystick2Button4PressedStatus 3 "NotAvailable" 2 "ErrorIndicator" 1 "ButtonPressed" 0 "ButtonNotPressed" ;
